VERSION ""

NS_ :

BS_:

BU_: EHR_Spare FEHR_3 PTO_SpeedSelector Dummy_Node_Ch2 FEHR_2 TrailerBrake OffBoardDiagnosticTool1_Ch2 PowerTakeOff_Ch2 Transmission1_Ch2 FEHR_1 REHR_5 REHR_4 REHR_3 REHR_2 REHR_1 InstrumentCluster_Ch2 ManagementComputer_Ch2 GWAY_OnBoardDiagnosticUnit_Ch2 GWAY_OffBoardDiagTool1_VB1_Ch2 GWAY_Engine1_Ch2 GWAY_CabDisplay1_Ch2 AuxiliaryValveControl_Ch2

BO_ 2632777610 TPCM_8A: 8 FEHR_2
 SG_ CByteTPCM M : 0|8@1+ (1,0) [0|255] ""  InstrumentCluster_Ch2
 SG_ ConnAbrtReason m255 : 8|8@1+ (1,0) [0|255] ""  InstrumentCluster_Ch2
 SG_ MaxNumPktTPCM_RTS m16 : 32|8@1+ (1,0) [0|255] ""  InstrumentCluster_Ch2
 SG_ NumPktSentTPCM_CTS m17 : 8|8@1+ (1,0) [0|255] ""  InstrumentCluster_Ch2
 SG_ NxtPktNumSentTPCM_CTS m17 : 16|8@1+ (1,0) [0|255] ""  InstrumentCluster_Ch2
 SG_ PGN_PktMsgTPCM_BAM m32 : 40|24@1+ (1,0) [0|16777200] ""  InstrumentCluster_Ch2
 SG_ PGN_PktMsgTPCM_ConnAbort m255 : 40|24@1+ (1,0) [0|16777200] ""  InstrumentCluster_Ch2
 SG_ PGN_PktMsgTPCM_CTS m17 : 40|24@1+ (1,0) [0|16777200] ""  InstrumentCluster_Ch2
 SG_ PGN_PktMsgTPCM_RTS m16 : 40|24@1+ (1,0) [0|16777200] ""  InstrumentCluster_Ch2
 SG_ PGN_PktMsgTPCM_RTS2 m19 : 40|24@1+ (1,0) [0|16777200] ""  InstrumentCluster_Ch2
 SG_ TotMsgSizeBAM m32 : 8|16@1+ (1,0) [0|64255] "counts"  InstrumentCluster_Ch2
 SG_ TotMsgSizeEoMA m19 : 8|16@1+ (1,0) [0|64255] "counts"  InstrumentCluster_Ch2
 SG_ TotMsgSizeTPCM_RTS m16 : 8|16@1+ (1,0) [0|64255] "counts"  InstrumentCluster_Ch2
 SG_ TotNumPktBAM m32 : 24|8@1+ (1,0) [0|255] ""  InstrumentCluster_Ch2
 SG_ TotNumPktEoMA m19 : 24|8@1+ (1,0) [0|255] ""  InstrumentCluster_Ch2
 SG_ TotNumPktTPCM_RTS m16 : 24|8@1+ (1,0) [0|255] ""  InstrumentCluster_Ch2

BO_ 2566834825 DM1_89: 18 FEHR_1
 SG_ AmbrWarnLmp : 2|2@1+ (1,0) [0|3] ""  InstrumentCluster_Ch2
 SG_ DTC_01 : 16|32@1+ (1,0) [0|4294970000] ""  InstrumentCluster_Ch2
 SG_ DTC_02 : 48|32@1+ (1,0) [0|4294970000] ""  InstrumentCluster_Ch2
 SG_ DTC_03 : 80|32@1+ (1,0) [0|4294970000] ""  InstrumentCluster_Ch2
 SG_ DTC_04 : 112|32@1+ (1,0) [0|4294970000] ""  InstrumentCluster_Ch2
 SG_ FlashAmbrWarnLmpAWL : 10|2@1+ (1,0) [0|3] ""  InstrumentCluster_Ch2
 SG_ FlashMIL : 14|2@1+ (1,0) [0|3] ""  InstrumentCluster_Ch2
 SG_ FlashProtLmp : 8|2@1+ (1,0) [0|3] ""  InstrumentCluster_Ch2
 SG_ FlashRedStopLmpRSL : 12|2@1+ (1,0) [0|3] ""  InstrumentCluster_Ch2
 SG_ MIL : 6|2@1+ (1,0) [0|3] ""  InstrumentCluster_Ch2
 SG_ ProtLmp : 0|2@1+ (1,0) [0|3] ""  InstrumentCluster_Ch2
 SG_ RedStopLmp : 4|2@1+ (1,0) [0|3] ""  InstrumentCluster_Ch2

BO_ 2566834826 DM1_8A: 18 FEHR_2
 SG_ AmbrWarnLmp : 2|2@1+ (1,0) [0|3] ""  InstrumentCluster_Ch2
 SG_ DTC_01 : 16|32@1+ (1,0) [0|4294970000] ""  InstrumentCluster_Ch2
 SG_ DTC_02 : 48|32@1+ (1,0) [0|4294970000] ""  InstrumentCluster_Ch2
 SG_ DTC_03 : 80|32@1+ (1,0) [0|4294970000] ""  InstrumentCluster_Ch2
 SG_ DTC_04 : 112|32@1+ (1,0) [0|4294970000] ""  InstrumentCluster_Ch2
 SG_ FlashAmbrWarnLmpAWL : 10|2@1+ (1,0) [0|3] ""  InstrumentCluster_Ch2
 SG_ FlashMIL : 14|2@1+ (1,0) [0|3] ""  InstrumentCluster_Ch2
 SG_ FlashProtLmp : 8|2@1+ (1,0) [0|3] ""  InstrumentCluster_Ch2
 SG_ FlashRedStopLmpRSL : 12|2@1+ (1,0) [0|3] ""  InstrumentCluster_Ch2
 SG_ MIL : 6|2@1+ (1,0) [0|3] ""  InstrumentCluster_Ch2
 SG_ ProtLmp : 0|2@1+ (1,0) [0|3] ""  InstrumentCluster_Ch2
 SG_ RedStopLmp : 4|2@1+ (1,0) [0|3] ""  InstrumentCluster_Ch2

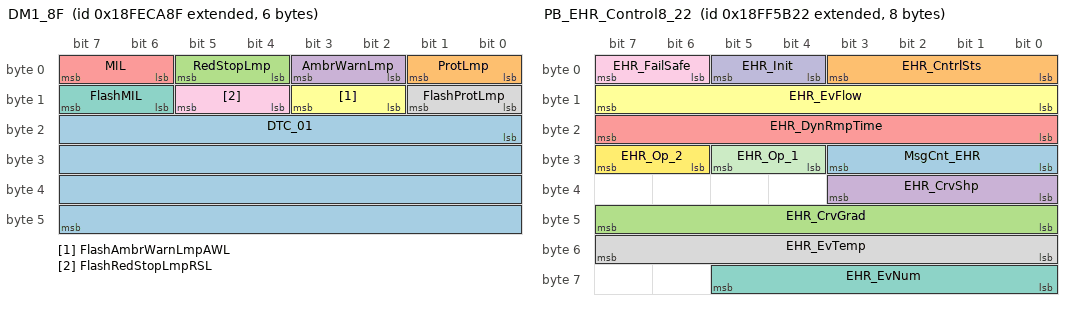
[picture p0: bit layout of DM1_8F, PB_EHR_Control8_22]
BO_ 2566834831 DM1_8F: 6 EHR_Spare
 SG_ DTC_01 : 16|32@1+ (1,0) [0|4294970000] ""  AuxiliaryValveControl_Ch2
 SG_ ProtLmp : 0|2@1+ (1,0) [0|3] ""  AuxiliaryValveControl_Ch2
 SG_ RedStopLmp : 4|2@1+ (1,0) [0|3] ""  AuxiliaryValveControl_Ch2
 SG_ AmbrWarnLmp : 2|2@1+ (1,0) [0|3] ""  AuxiliaryValveControl_Ch2
 SG_ MIL : 6|2@1+ (1,0) [0|3] ""  AuxiliaryValveControl_Ch2
 SG_ FlashAmbrWarnLmpAWL : 10|2@1+ (1,0) [0|3] ""  AuxiliaryValveControl_Ch2
 SG_ FlashMIL : 14|2@1+ (1,0) [0|3] ""  AuxiliaryValveControl_Ch2
 SG_ FlashProtLmp : 8|2@1+ (1,0) [0|3] ""  AuxiliaryValveControl_Ch2
 SG_ FlashRedStopLmpRSL : 12|2@1+ (1,0) [0|3] ""  AuxiliaryValveControl_Ch2

BO_ 2632712075 TPDT_8B: 8 FEHR_3
 SG_ PktDataTPDT : 8|56@1+ (1,0) [0|7.20575940379279E+16] ""  InstrumentCluster_Ch2
 SG_ SN_TPDT : 0|8@1+ (1,0) [0|255] ""  InstrumentCluster_Ch2

BO_ 2632777611 TPCM_8B: 8 FEHR_3
 SG_ CByteTPCM M : 0|8@1+ (1,0) [0|255] ""  InstrumentCluster_Ch2
 SG_ ConnAbrtReason m255 : 8|8@1+ (1,0) [0|255] ""  InstrumentCluster_Ch2
 SG_ MaxNumPktTPCM_RTS m16 : 32|8@1+ (1,0) [0|255] ""  InstrumentCluster_Ch2
 SG_ NumPktSentTPCM_CTS m17 : 8|8@1+ (1,0) [0|255] ""  InstrumentCluster_Ch2
 SG_ NxtPktNumSentTPCM_CTS m17 : 16|8@1+ (1,0) [0|255] ""  InstrumentCluster_Ch2
 SG_ PGN_PktMsgTPCM_BAM m32 : 40|24@1+ (1,0) [0|16777200] ""  InstrumentCluster_Ch2
 SG_ PGN_PktMsgTPCM_ConnAbort m255 : 40|24@1+ (1,0) [0|16777200] ""  InstrumentCluster_Ch2
 SG_ PGN_PktMsgTPCM_CTS m17 : 40|24@1+ (1,0) [0|16777200] ""  InstrumentCluster_Ch2
 SG_ PGN_PktMsgTPCM_RTS m16 : 40|24@1+ (1,0) [0|16777200] ""  InstrumentCluster_Ch2
 SG_ PGN_PktMsgTPCM_RTS2 m19 : 40|24@1+ (1,0) [0|16777200] ""  InstrumentCluster_Ch2
 SG_ TotMsgSizeBAM m32 : 8|16@1+ (1,0) [0|64255] "counts"  InstrumentCluster_Ch2
 SG_ TotMsgSizeEoMA m19 : 8|16@1+ (1,0) [0|64255] "counts"  InstrumentCluster_Ch2
 SG_ TotMsgSizeTPCM_RTS m16 : 8|16@1+ (1,0) [0|64255] "counts"  InstrumentCluster_Ch2
 SG_ TotNumPktBAM m32 : 24|8@1+ (1,0) [0|255] ""  InstrumentCluster_Ch2
 SG_ TotNumPktEoMA m19 : 24|8@1+ (1,0) [0|255] ""  InstrumentCluster_Ch2
 SG_ TotNumPktTPCM_RTS m16 : 24|8@1+ (1,0) [0|255] ""  InstrumentCluster_Ch2

BO_ 2566838923 SOFT_8B: 89 FEHR_3
 SG_ Appl_Id_Byte_24 : 552|8@1+ (1,0) [0|255] ""  AuxiliaryValveControl_Ch2
 SG_ Appl_Id_Byte_25 : 560|8@1+ (1,0) [0|255] ""  AuxiliaryValveControl_Ch2
 SG_ Appl_Id_Byte_26 : 568|8@1+ (1,0) [0|255] ""  AuxiliaryValveControl_Ch2
 SG_ Appl_Id_Byte_27 : 576|8@1+ (1,0) [0|255] ""  AuxiliaryValveControl_Ch2
 SG_ Appl_Id_Byte_28 : 584|8@1+ (1,0) [0|255] ""  AuxiliaryValveControl_Ch2
 SG_ Appl_Id_Byte_29 : 592|8@1+ (1,0) [0|255] ""  AuxiliaryValveControl_Ch2
 SG_ Appl_Id_Byte_30 : 600|8@1+ (1,0) [0|255] ""  AuxiliaryValveControl_Ch2
 SG_ Appl_Id_Byte_31 : 608|8@1+ (1,0) [0|255] ""  AuxiliaryValveControl_Ch2
 SG_ Appl_Id_Byte_32 : 616|8@1+ (1,0) [0|255] ""  AuxiliaryValveControl_Ch2
 SG_ Appl_Id_Byte_33 : 624|8@1+ (1,0) [0|255] ""  AuxiliaryValveControl_Ch2
 SG_ Appl_Id_Byte_34 : 632|8@1+ (1,0) [0|255] ""  AuxiliaryValveControl_Ch2
 SG_ Appl_Id_Byte_35 : 640|8@1+ (1,0) [0|255] ""  AuxiliaryValveControl_Ch2
 SG_ Appl_Id_Byte_36 : 648|8@1+ (1,0) [0|255] ""  AuxiliaryValveControl_Ch2
 SG_ Appl_Id_Byte_37 : 656|8@1+ (1,0) [0|255] ""  AuxiliaryValveControl_Ch2
 SG_ Appl_Id_Byte_38 : 664|8@1+ (1,0) [0|255] ""  AuxiliaryValveControl_Ch2
 SG_ Appl_Id_Byte_39 : 672|8@1+ (1,0) [0|255] ""  AuxiliaryValveControl_Ch2
 SG_ Appl_Id_Enum : 680|24@1+ (1,0) [0|16777215] ""  AuxiliaryValveControl_Ch2
 SG_ Bootloader_Id : 360|8@1+ (1,0) [0|255] ""  AuxiliaryValveControl_Ch2
 SG_ Bootloader_Id_Byte_01 : 16|8@1+ (1,0) [0|255] ""  AuxiliaryValveControl_Ch2
 SG_ Bootloader_Id_Byte_02 : 24|8@1+ (1,0) [0|255] ""  AuxiliaryValveControl_Ch2
 SG_ Bootloader_Id_Byte_03 : 32|8@1+ (1,0) [0|255] ""  AuxiliaryValveControl_Ch2
 SG_ Bootloader_Id_Byte_04 : 40|8@1+ (1,0) [0|255] ""  AuxiliaryValveControl_Ch2
 SG_ Bootloader_Id_Byte_05 : 48|8@1+ (1,0) [0|255] ""  AuxiliaryValveControl_Ch2
 SG_ Bootloader_Id_Byte_06 : 56|8@1+ (1,0) [0|255] ""  AuxiliaryValveControl_Ch2
 SG_ Bootloader_Id_Byte_07 : 64|8@1+ (1,0) [0|255] ""  AuxiliaryValveControl_Ch2
 SG_ Bootloader_Id_Byte_08 : 72|8@1+ (1,0) [0|255] ""  AuxiliaryValveControl_Ch2
 SG_ Bootloader_Id_Byte_09 : 80|8@1+ (1,0) [0|255] ""  AuxiliaryValveControl_Ch2
 SG_ Bootloader_Id_Byte_10 : 88|8@1+ (1,0) [0|255] ""  AuxiliaryValveControl_Ch2
 SG_ Bootloader_Id_Byte_11 : 96|8@1+ (1,0) [0|255] ""  AuxiliaryValveControl_Ch2
 SG_ Bootloader_Id_Byte_12 : 104|8@1+ (1,0) [0|255] ""  AuxiliaryValveControl_Ch2
 SG_ Bootloader_Id_Byte_13 : 112|8@1+ (1,0) [0|255] ""  AuxiliaryValveControl_Ch2
 SG_ Bootloader_Id_Byte_14 : 120|8@1+ (1,0) [0|255] ""  AuxiliaryValveControl_Ch2
 SG_ Bootloader_Id_Byte_15 : 128|8@1+ (1,0) [0|255] ""  AuxiliaryValveControl_Ch2
 SG_ Bootloader_Id_Byte_16 : 136|8@1+ (1,0) [0|255] ""  AuxiliaryValveControl_Ch2
 SG_ Bootloader_Id_Byte_17 : 144|8@1+ (1,0) [0|255] ""  AuxiliaryValveControl_Ch2
 SG_ Bootloader_Id_Byte_18 : 152|8@1+ (1,0) [0|255] ""  AuxiliaryValveControl_Ch2
 SG_ Bootloader_Id_Byte_19 : 160|8@1+ (1,0) [0|255] ""  AuxiliaryValveControl_Ch2
 SG_ Bootloader_Id_Byte_20 : 168|8@1+ (1,0) [0|255] ""  AuxiliaryValveControl_Ch2
 SG_ Bootloader_Id_Byte_21 : 176|8@1+ (1,0) [0|255] ""  AuxiliaryValveControl_Ch2
 SG_ Bootloader_Id_Byte_22 : 184|8@1+ (1,0) [0|255] ""  AuxiliaryValveControl_Ch2
 SG_ Bootloader_Id_Byte_23 : 192|8@1+ (1,0) [0|255] ""  AuxiliaryValveControl_Ch2
 SG_ Bootloader_Id_Byte_24 : 200|8@1+ (1,0) [0|255] ""  AuxiliaryValveControl_Ch2
 SG_ Bootloader_Id_Byte_25 : 208|8@1+ (1,0) [0|255] ""  AuxiliaryValveControl_Ch2
 SG_ Bootloader_Id_Byte_26 : 216|8@1+ (1,0) [0|255] ""  AuxiliaryValveControl_Ch2
 SG_ Bootloader_Id_Byte_27 : 224|8@1+ (1,0) [0|255] ""  AuxiliaryValveControl_Ch2
 SG_ Bootloader_Id_Byte_28 : 232|8@1+ (1,0) [0|255] ""  AuxiliaryValveControl_Ch2
 SG_ Bootloader_Id_Byte_29 : 240|8@1+ (1,0) [0|255] ""  AuxiliaryValveControl_Ch2
 SG_ Bootloader_Id_Byte_30 : 248|8@1+ (1,0) [0|255] ""  AuxiliaryValveControl_Ch2
 SG_ Bootloader_Id_Byte_31 : 256|8@1+ (1,0) [0|255] ""  AuxiliaryValveControl_Ch2
 SG_ Bootloader_Id_Byte_32 : 264|8@1+ (1,0) [0|255] ""  AuxiliaryValveControl_Ch2
 SG_ Bootloader_Id_Byte_33 : 272|8@1+ (1,0) [0|255] ""  AuxiliaryValveControl_Ch2
 SG_ Bootloader_Id_Byte_34 : 280|8@1+ (1,0) [0|255] ""  AuxiliaryValveControl_Ch2
 SG_ Bootloader_Id_Byte_35 : 288|8@1+ (1,0) [0|255] ""  AuxiliaryValveControl_Ch2
 SG_ Bootloader_Id_Byte_36 : 296|8@1+ (1,0) [0|255] ""  AuxiliaryValveControl_Ch2
 SG_ Bootloader_Id_Byte_37 : 304|8@1+ (1,0) [0|255] ""  AuxiliaryValveControl_Ch2
 SG_ Bootloader_Id_Byte_38 : 312|8@1+ (1,0) [0|255] ""  AuxiliaryValveControl_Ch2
 SG_ Bootloader_Id_Byte_39 : 320|8@1+ (1,0) [0|255] ""  AuxiliaryValveControl_Ch2
 SG_ Bootloader_Id_Enum : 328|24@1+ (1,0) [0|16777215] ""  AuxiliaryValveControl_Ch2
 SG_ EndStrng_00 : 352|8@1+ (1,0) [0|255] "per byte"  AuxiliaryValveControl_Ch2
 SG_ EndStrng_01 : 704|8@1+ (1,0) [0|255] "per byte"  AuxiliaryValveControl_Ch2
 SG_ NumSW_IdField : 0|8@1+ (1,0) [0|250] "step"  AuxiliaryValveControl_Ch2
 SG_ Appl_Id : 8|8@1+ (1,0) [0|255] ""  AuxiliaryValveControl_Ch2
 SG_ Appl_Id_Byte_01 : 368|8@1+ (1,0) [0|255] ""  AuxiliaryValveControl_Ch2
 SG_ Appl_Id_Byte_02 : 376|8@1+ (1,0) [0|255] ""  AuxiliaryValveControl_Ch2
 SG_ Appl_Id_Byte_03 : 384|8@1+ (1,0) [0|255] ""  AuxiliaryValveControl_Ch2
 SG_ Appl_Id_Byte_04 : 392|8@1+ (1,0) [0|255] ""  AuxiliaryValveControl_Ch2
 SG_ Appl_Id_Byte_05 : 400|8@1+ (1,0) [0|255] ""  AuxiliaryValveControl_Ch2
 SG_ Appl_Id_Byte_06 : 408|8@1+ (1,0) [0|255] ""  AuxiliaryValveControl_Ch2
 SG_ Appl_Id_Byte_07 : 416|8@1+ (1,0) [0|255] ""  AuxiliaryValveControl_Ch2
 SG_ Appl_Id_Byte_08 : 424|8@1+ (1,0) [0|255] ""  AuxiliaryValveControl_Ch2
 SG_ Appl_Id_Byte_09 : 432|8@1+ (1,0) [0|255] ""  AuxiliaryValveControl_Ch2
 SG_ Appl_Id_Byte_10 : 440|8@1+ (1,0) [0|255] ""  AuxiliaryValveControl_Ch2
 SG_ Appl_Id_Byte_11 : 448|8@1+ (1,0) [0|255] ""  AuxiliaryValveControl_Ch2
 SG_ Appl_Id_Byte_12 : 456|8@1+ (1,0) [0|255] ""  AuxiliaryValveControl_Ch2
 SG_ Appl_Id_Byte_13 : 464|8@1+ (1,0) [0|255] ""  AuxiliaryValveControl_Ch2
 SG_ Appl_Id_Byte_14 : 472|8@1+ (1,0) [0|255] ""  AuxiliaryValveControl_Ch2
 SG_ Appl_Id_Byte_15 : 480|8@1+ (1,0) [0|255] ""  AuxiliaryValveControl_Ch2
 SG_ Appl_Id_Byte_16 : 488|8@1+ (1,0) [0|255] ""  AuxiliaryValveControl_Ch2
 SG_ Appl_Id_Byte_17 : 496|8@1+ (1,0) [0|255] ""  AuxiliaryValveControl_Ch2
 SG_ Appl_Id_Byte_18 : 504|8@1+ (1,0) [0|255] ""  AuxiliaryValveControl_Ch2
 SG_ Appl_Id_Byte_19 : 512|8@1+ (1,0) [0|255] ""  AuxiliaryValveControl_Ch2
 SG_ Appl_Id_Byte_20 : 520|8@1+ (1,0) [0|255] ""  AuxiliaryValveControl_Ch2
 SG_ Appl_Id_Byte_21 : 528|8@1+ (1,0) [0|255] ""  AuxiliaryValveControl_Ch2
 SG_ Appl_Id_Byte_22 : 536|8@1+ (1,0) [0|255] ""  AuxiliaryValveControl_Ch2
 SG_ Appl_Id_Byte_23 : 544|8@1+ (1,0) [0|255] ""  AuxiliaryValveControl_Ch2

BO_ 2566871842 PB_EHR_Control8_22: 8 AuxiliaryValveControl_Ch2
 SG_ MsgCnt_EHR : 24|4@1+ (1,0) [0|12] "count" Vector__XXX
 SG_ EHR_CntrlSts : 0|4@1+ (1,0) [0|15] ""  FEHR_3
 SG_ EHR_CrvGrad : 40|8@1+ (0.3922,0) [0|100] "%"  FEHR_3
 SG_ EHR_CrvShp : 32|4@1+ (1,0) [0|15] ""  FEHR_3
 SG_ EHR_DynRmpTime : 16|8@1+ (32,0) [0|8128] "ms"  FEHR_3
 SG_ EHR_EvFlow : 8|8@1+ (0.3937,0) [0|100] "%"  FEHR_3
 SG_ EHR_EvNum : 56|6@1+ (1,0) [0|63] ""  FEHR_3
 SG_ EHR_EvTemp : 48|8@1+ (1,-80) [-40|120] "Deg C"  FEHR_3
 SG_ EHR_FailSafe : 6|2@1+ (1,0) [0|3] ""  FEHR_3
 SG_ EHR_Init : 4|2@1+ (1,0) [0|3] ""  FEHR_3
 SG_ EHR_Op_1 : 28|2@1+ (1,0) [0|3] ""  FEHR_3
 SG_ EHR_Op_2 : 30|2@1+ (1,0) [0|3] ""  FEHR_3

BO_ 2564487563 ISO15765_Phys_8B_F9: 8 FEHR_3
 SG_ ProtocCntrlInfo M : 4|4@1+ (1,0) [0|3] "" Vector__XXX
 SG_ SingFrameDataLen m0 : 0|4@1+ (1,0) [0|7] "Byte" Vector__XXX
 SG_ N1FrameDataLen m1 : 3|12@0+ (1,0) [0|4095] "Byte" Vector__XXX
 SG_ FlowSts m3 : 0|4@1+ (1,0) [0|3] "" Vector__XXX
 SG_ BlkSize m3 : 8|8@1+ (1,0) [0|255] "" Vector__XXX
 SG_ SepTime m3 : 16|8@1+ (1,0) [0|255] "ms" Vector__XXX
 SG_ SN m2 : 0|4@1+ (1,0) [0|15] "" Vector__XXX

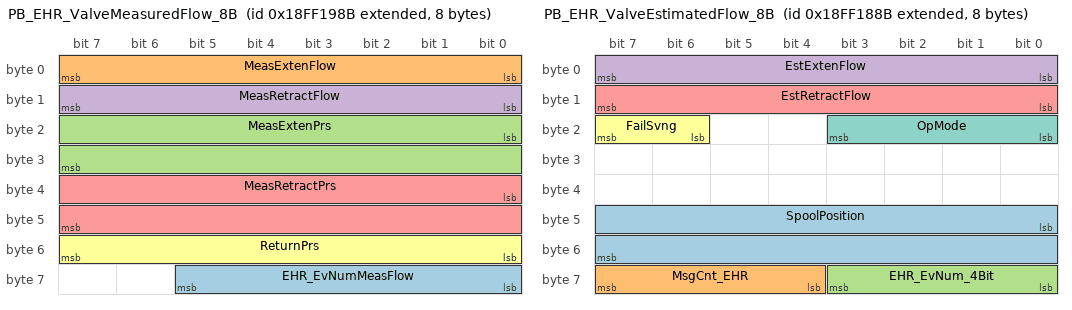
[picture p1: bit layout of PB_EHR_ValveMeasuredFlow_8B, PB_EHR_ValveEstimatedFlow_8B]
BO_ 2566855051 PB_EHR_ValveMeasuredFlow_8B: 8 FEHR_3
 SG_ EHR_EvNumMeasFlow : 56|6@1+ (1,0) [0|63] "" Vector__XXX
 SG_ MeasExtenFlow : 0|8@1+ (1,-125) [-125|125] "%" Vector__XXX
 SG_ MeasExtenPrs : 16|16@1+ (5,0) [0|321275] "kPa" Vector__XXX
 SG_ MeasRetractFlow : 8|8@1+ (1,-125) [-125|125] "%" Vector__XXX
 SG_ MeasRetractPrs : 32|16@1+ (5,0) [0|321275] "kPa" Vector__XXX
 SG_ ReturnPrs : 48|8@1+ (16,0) [0|4000] "kPa" Vector__XXX

BO_ 2566854795 PB_EHR_ValveEstimatedFlow_8B: 8 FEHR_3
 SG_ SpoolPosition : 40|16@1+ (1,0) [0|1023] ""  AuxiliaryValveControl_Ch2
 SG_ MsgCnt_EHR : 60|4@1+ (1,0) [0|12] "count"  AuxiliaryValveControl_Ch2
 SG_ EHR_EvNum_4Bit : 56|4@1+ (1,0) [0|15] ""  AuxiliaryValveControl_Ch2
 SG_ EstExtenFlow : 0|8@1+ (0.8,-102.4) [0|100] "%"  AuxiliaryValveControl_Ch2
 SG_ EstRetractFlow : 8|8@1+ (0.8,-102.4) [0|100] "%"  AuxiliaryValveControl_Ch2
 SG_ FailSvng : 22|2@1+ (1,0) [0|3] ""  AuxiliaryValveControl_Ch2
 SG_ OpMode : 16|4@1+ (1,0) [0|15] ""  AuxiliaryValveControl_Ch2

BO_ 2566866059 PB_EHR_ParameterStatus_8B: 8 FEHR_3
 SG_ EHR_RmpRndng m103 : 32|8@1+ (1,0) [0|255] ""  AuxiliaryValveControl_Ch2
 SG_ EHR_ChksumStor m80 : 40|8@1+ (1,0) [0|255] ""  AuxiliaryValveControl_Ch2
 SG_ EHR_ChksumSW m80 : 32|8@1+ (1,0) [0|255] ""  AuxiliaryValveControl_Ch2
 SG_ EHR_EvNumParamMux_12 : 24|8@1+ (1,0) [0|255] ""  AuxiliaryValveControl_Ch2
 SG_ EHR_ParamStsByte_3 M : 16|8@1+ (1,0) [0|255] ""  AuxiliaryValveControl_Ch2
 SG_ EHR_ParamStsByte_2 : 8|8@1+ (1,0) [0|255] ""  AuxiliaryValveControl_Ch2
 SG_ EHR_ParamByte_1 : 0|8@1+ (1,0) [0|255] ""  AuxiliaryValveControl_Ch2

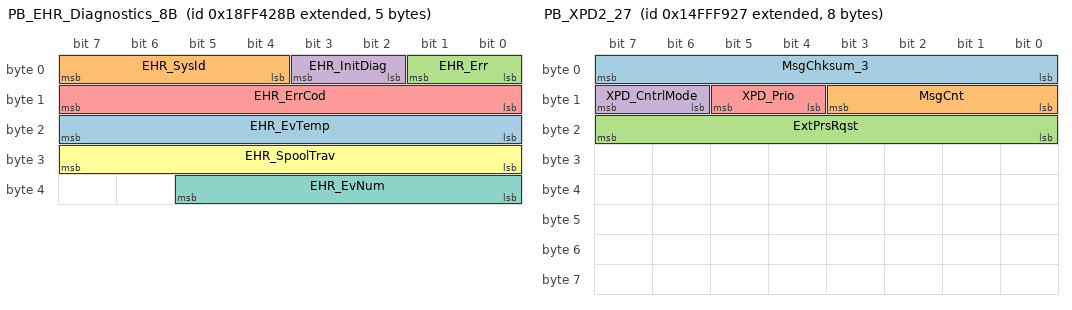
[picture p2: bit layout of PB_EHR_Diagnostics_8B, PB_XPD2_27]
BO_ 2566865547 PB_EHR_Diagnostics_8B: 5 FEHR_3
 SG_ EHR_EvTemp : 16|8@1+ (1,-80) [-40|120] "Deg C"  AuxiliaryValveControl_Ch2
 SG_ EHR_SysId : 4|4@1+ (1,0) [0|15] ""  AuxiliaryValveControl_Ch2
 SG_ EHR_Err : 0|2@1+ (1,0) [0|3] ""  AuxiliaryValveControl_Ch2
 SG_ EHR_InitDiag : 2|2@1+ (1,0) [0|3] ""  AuxiliaryValveControl_Ch2
 SG_ EHR_ErrCod : 8|8@1+ (1,0) [0|254] ""  AuxiliaryValveControl_Ch2
 SG_ EHR_SpoolTrav : 24|8@1+ (1,0) [0|254] ""  AuxiliaryValveControl_Ch2
 SG_ EHR_EvNum : 32|6@1+ (1,0) [0|63] ""  AuxiliaryValveControl_Ch2

BO_ 2566835083 DM2_8B: 74 FEHR_3
 SG_ DTC_01 : 16|32@1+ (1,0) [0|4294970000] "" Vector__XXX
 SG_ FlashAmbrWarnLmpAWL : 10|2@1+ (1,0) [0|3] "" Vector__XXX
 SG_ FlashMIL : 14|2@1+ (1,0) [0|3] "" Vector__XXX
 SG_ FlashProtLmp : 8|2@1+ (1,0) [0|3] "" Vector__XXX
 SG_ FlashRedStopLmpRSL : 12|2@1+ (1,0) [0|3] "" Vector__XXX
 SG_ ProtLmp : 0|2@1+ (1,0) [0|3] "" Vector__XXX
 SG_ AmbrWarnLmp : 2|2@1+ (1,0) [0|3] "" Vector__XXX
 SG_ RedStopLmp : 4|2@1+ (1,0) [0|3] "" Vector__XXX
 SG_ MIL : 6|2@1+ (1,0) [0|3] "" Vector__XXX

BO_ 2566834827 DM1_8B: 42 FEHR_3
 SG_ DTC_10 : 304|32@1+ (1,0) [0|4294970000] "" Vector__XXX
 SG_ DTC_09 : 272|32@1+ (1,0) [0|4294970000] "" Vector__XXX
 SG_ DTC_08 : 240|32@1+ (1,0) [0|4294970000] "" Vector__XXX
 SG_ DTC_07 : 208|32@1+ (1,0) [0|4294970000] "" Vector__XXX
 SG_ DTC_06 : 176|32@1+ (1,0) [0|4294970000] "" Vector__XXX
 SG_ DTC_05 : 144|32@1+ (1,0) [0|4294970000] "" Vector__XXX
 SG_ DTC_04 : 112|32@1+ (1,0) [0|4294970000] "" Vector__XXX
 SG_ DTC_03 : 80|32@1+ (1,0) [0|4294970000] "" Vector__XXX
 SG_ DTC_02 : 48|32@1+ (1,0) [0|4294970000] "" Vector__XXX
 SG_ DTC_01 : 16|32@1+ (1,0) [0|4294970000] "" Vector__XXX
 SG_ ProtLmp : 0|2@1+ (1,0) [0|3] "" Vector__XXX
 SG_ RedStopLmp : 4|2@1+ (1,0) [0|3] "" Vector__XXX
 SG_ AmbrWarnLmp : 2|2@1+ (1,0) [0|3] "" Vector__XXX
 SG_ MIL : 6|2@1+ (1,0) [0|3] "" Vector__XXX
 SG_ FlashAmbrWarnLmpAWL : 10|2@1+ (1,0) [0|3] "" Vector__XXX
 SG_ FlashMIL : 14|2@1+ (1,0) [0|3] "" Vector__XXX
 SG_ FlashProtLmp : 8|2@1+ (1,0) [0|3] "" Vector__XXX
 SG_ FlashRedStopLmpRSL : 12|2@1+ (1,0) [0|3] "" Vector__XXX

BO_ 2499803431 PB_XPD2_27: 8 ManagementComputer_Ch2
 SG_ MsgChksum_3 : 0|8@1+ (1,0) [0|255] "count"  TrailerBrake
 SG_ MsgCnt : 8|4@1+ (1,0) [0|15] "count"  TrailerBrake
 SG_ ExtPrsRqst : 16|8@1+ (5,0) [0|1250] "kPa"  TrailerBrake
 SG_ XPD_CntrlMode : 14|2@1+ (1,0) [0|3] ""  TrailerBrake
 SG_ XPD_Prio : 12|2@1+ (1,0) [0|3] ""  TrailerBrake

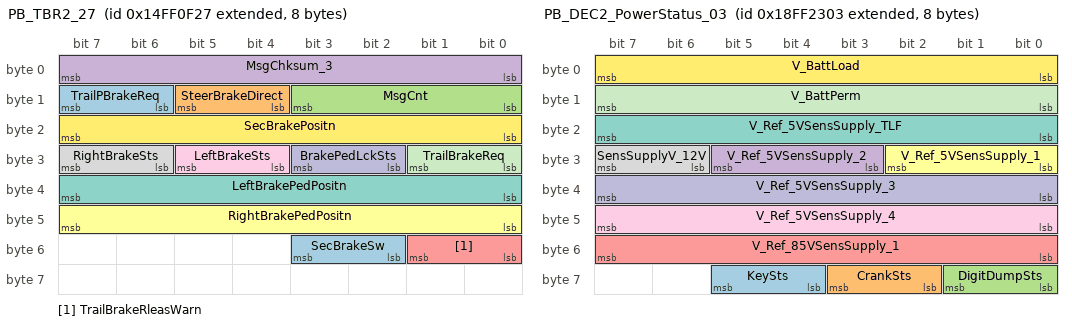
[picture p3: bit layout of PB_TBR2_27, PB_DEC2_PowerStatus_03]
BO_ 2499743527 PB_TBR2_27: 8 ManagementComputer_Ch2
 SG_ TrailPBrakeReq : 14|2@1+ (1,0) [0|3] ""  TrailerBrake
 SG_ SteerBrakeDirect : 12|2@1+ (1,0) [0|3] ""  TrailerBrake
 SG_ MsgCnt : 8|4@1+ (1,0) [0|15] "count"  TrailerBrake
 SG_ MsgChksum_3 : 0|8@1+ (1,0) [0|255] "count"  TrailerBrake
 SG_ TrailBrakeRleasWarn : 48|2@1+ (1,0) [0|3] ""  TrailerBrake
 SG_ RightBrakePedPositn : 40|8@1+ (0.4,0) [0|100] "%"  TrailerBrake
 SG_ LeftBrakePedPositn : 32|8@1+ (0.4,0) [0|100] "%"  TrailerBrake
 SG_ RightBrakeSts : 30|2@1+ (1,0) [0|3] ""  TrailerBrake
 SG_ LeftBrakeSts : 28|2@1+ (1,0) [0|3] ""  TrailerBrake
 SG_ BrakePedLckSts : 26|2@1+ (1,0) [0|3] ""  TrailerBrake
 SG_ TrailBrakeReq : 24|2@1+ (1,0) [0|3] ""  TrailerBrake
 SG_ SecBrakePositn : 16|8@1+ (0.4,0) [0|100] "%"  TrailerBrake
 SG_ SecBrakeSw : 50|2@1+ (1,0) [0|3] ""  TrailerBrake

BO_ 2566857475 PB_DEC2_PowerStatus_03: 8 Transmission1_Ch2
 SG_ KeySts : 60|2@1+ (1,0) [0|3] ""  Dummy_Node_Ch2
 SG_ CrankSts : 58|2@1+ (1,0) [0|3] ""  Dummy_Node_Ch2
 SG_ DigitDumpSts : 56|2@1+ (1,0) [0|3] ""  Dummy_Node_Ch2
 SG_ V_Ref_5VSensSupply_2 : 27|3@1+ (1,0) [0|7] ""  Dummy_Node_Ch2
 SG_ V_Ref_85VSensSupply_1 : 48|8@1+ (0.0625,0) [0|15.8125] "V"  Dummy_Node_Ch2
 SG_ V_Ref_5VSensSupply_1 : 24|3@1+ (1,0) [0|7] ""  Dummy_Node_Ch2
 SG_ V_Ref_5VSensSupply_TLF : 16|8@1+ (0.03125,0) [0|7.90625] "V"  Dummy_Node_Ch2
 SG_ SensSupplyV_12V : 30|2@1+ (1,0) [0|3] ""  Dummy_Node_Ch2
 SG_ V_Ref_5VSensSupply_4 : 40|8@1+ (0.03125,0) [0|7.90625] "V"  Dummy_Node_Ch2
 SG_ V_Ref_5VSensSupply_3 : 32|8@1+ (0.03125,0) [0|7.90625] "V"  Dummy_Node_Ch2
 SG_ V_BattPerm : 8|8@1+ (0.125,0) [0|31.875] "V"  Dummy_Node_Ch2
 SG_ V_BattLoad : 0|8@1+ (0.125,0) [0|31.875] "V"  Dummy_Node_Ch2

BO_ 2564488958 ISO15765_Phys: 8 REHR_1
 SG_ ProtocCntrlInfo M : 4|4@1+ (1,0) [0|3] ""  AuxiliaryValveControl_Ch2
 SG_ SN m2 : 0|4@1+ (1,0) [0|15] ""  AuxiliaryValveControl_Ch2
 SG_ SepTime m3 : 16|8@1+ (1,0) [0|255] "ms"  AuxiliaryValveControl_Ch2
 SG_ SingFrameDataLen m0 : 0|4@1+ (1,0) [0|7] "Byte"  AuxiliaryValveControl_Ch2
 SG_ N1FrameDataLen m1 : 3|12@0+ (1,0) [0|4095] "Byte"  AuxiliaryValveControl_Ch2
 SG_ FlowSts m3 : 0|4@1+ (1,0) [0|3] ""  AuxiliaryValveControl_Ch2
 SG_ BlkSize m3 : 8|8@1+ (1,0) [0|255] ""  AuxiliaryValveControl_Ch2

BO_ 2565603086 TPDT_0E: 8 TrailerBrake
 SG_ PktDataTPDT : 8|56@1+ (1,0) [0|7.20575940379279E+16] ""  ManagementComputer_Ch2
 SG_ SN_TPDT : 0|8@1+ (1,0) [0|255] ""  ManagementComputer_Ch2

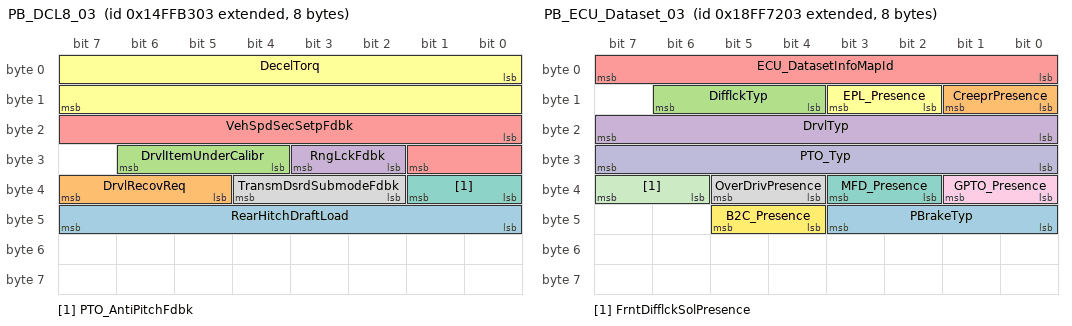
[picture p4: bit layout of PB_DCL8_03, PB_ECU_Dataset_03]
BO_ 2499785475 PB_DCL8_03: 8 Transmission1_Ch2
 SG_ RearHitchDraftLoad : 40|8@1+ (1,0) [0|100] "%"  ManagementComputer_Ch2
 SG_ DrvlRecovReq : 37|3@1+ (1,0) [0|7] ""  ManagementComputer_Ch2
 SG_ DrvlItemUnderCalibr : 28|3@1+ (1,0) [0|7] ""  ManagementComputer_Ch2
 SG_ RngLckFdbk : 26|2@1+ (1,0) [0|3] ""  ManagementComputer_Ch2
 SG_ VehSpdSecSetpFdbk : 16|10@1+ (0.1,0) [0|102] "%"  ManagementComputer_Ch2
 SG_ DecelTorq : 0|16@1+ (1,0) [0|64255] "Nm"  ManagementComputer_Ch2
 SG_ PTO_AntiPitchFdbk : 32|2@1+ (1,0) [0|3] ""  ManagementComputer_Ch2
 SG_ TransmDsrdSubmodeFdbk : 34|3@1+ (1,0) [0|7] ""  ManagementComputer_Ch2

BO_ 2566877699 PB_ECU_Dataset_03: 8 Transmission1_Ch2
 SG_ PBrakeTyp : 40|4@1+ (1,0) [0|15] ""  ManagementComputer_Ch2
 SG_ CreeprPresence : 8|2@1+ (1,0) [0|3] ""  ManagementComputer_Ch2
 SG_ DifflckTyp : 12|3@1+ (1,0) [0|7] ""  ManagementComputer_Ch2
 SG_ DrvlTyp : 16|8@1+ (1,0) [0|255] ""  ManagementComputer_Ch2
 SG_ ECU_DatasetInfoMapId : 0|8@1+ (1,0) [0|250] ""  ManagementComputer_Ch2
 SG_ EPL_Presence : 10|2@1+ (1,0) [0|3] ""  ManagementComputer_Ch2
 SG_ MFD_Presence : 34|2@1+ (1,0) [0|3] ""  ManagementComputer_Ch2
 SG_ OverDrivPresence : 36|2@1+ (1,0) [0|3] ""  ManagementComputer_Ch2
 SG_ GPTO_Presence : 32|2@1+ (1,0) [0|3] ""  ManagementComputer_Ch2
 SG_ PTO_Typ : 24|8@1+ (1,0) [0|255] ""  ManagementComputer_Ch2
 SG_ FrntDifflckSolPresence : 38|2@1+ (1,0) [0|3] "states/2 bit" Vector__XXX
 SG_ B2C_Presence : 44|2@1+ (1,0) [0|3] "" Vector__XXX

BO_ 2565351182 ACKM_0E_27: 8 TrailerBrake
 SG_ AddrAccssDeny m2 : 32|8@1+ (1,0) [0|255] "" Vector__XXX
 SG_ AddrAck m0 : 32|8@1+ (1,0) [0|255] "" Vector__XXX
 SG_ AddrBusy m3 : 32|8@1+ (1,0) [0|255] "" Vector__XXX
 SG_ AddrNegAck m1 : 32|8@1+ (1,0) [0|255] "" Vector__XXX
 SG_ CByteAckm M : 0|8@1+ (1,0) [0|255] "" Vector__XXX
 SG_ GrpFunctValAck : 8|8@1+ (1,0) [0|255] "" Vector__XXX
 SG_ PGN_RQST2_0E_27 : 40|24@1+ (1,0) [0|16777200] ""  ManagementComputer_Ch2

BO_ 2565351171 ACKM_03_27: 8 Transmission1_Ch2
 SG_ AddrNegAck m1 : 32|8@1+ (1,0) [0|255] "" Vector__XXX
 SG_ AddrBusy m3 : 32|8@1+ (1,0) [0|255] "" Vector__XXX
 SG_ AddrAck m0 : 32|8@1+ (1,0) [0|255] "" Vector__XXX
 SG_ AddrAccssDeny m2 : 32|8@1+ (1,0) [0|255] "" Vector__XXX
 SG_ GrpFunctValAck : 8|8@1+ (1,0) [0|255] "" Vector__XXX
 SG_ PGN_RQST2_03_27 : 40|24@1+ (1,0) [0|16777200] ""  ManagementComputer_Ch2
 SG_ CByteAckm M : 0|8@1+ (1,0) [0|255] "" Vector__XXX

BO_ 2566888195 PB_DCL5_03: 8 Transmission1_Ch2
 SG_ GearMapAv : 0|64@1+ (1,0) [0|64] "bit bit-mapped"  ManagementComputer_Ch2

BO_ 2566871043 PB_AxleId_03: 8 Transmission1_Ch2
 SG_ AxId : 0|8@1+ (1,0) [0|255] ""  ManagementComputer_Ch2

BO_ 2499798019 PB_Heartbeat_03_27: 8 Transmission1_Ch2
 SG_ Hrtbt : 0|8@1+ (1,0) [0|251] "count"  ManagementComputer_Ch2
 SG_ MsgChksum_4 : 12|4@1+ (1,0) [0|15] "count"  ManagementComputer_Ch2
 SG_ SpecialModeResp : 47|1@1+ (1,0) [0|1] "" Vector__XXX
 SG_ SpecialModeReq : 44|3@1+ (1,0) [0|7] "" Vector__XXX
 SG_ ThisNetReq : 22|2@1+ (1,0) [0|3] "" Vector__XXX
 SG_ BattMainSwHoldReq : 20|2@1+ (1,0) [0|3] "" Vector__XXX
 SG_ KeyPositn : 48|8@1+ (1,0) [0|255] "" Vector__XXX
 SG_ BattMainSwHoldFunct : 40|4@1+ (1,0) [0|15] "" Vector__XXX
 SG_ OpSeatSw : 8|2@1+ (1,0) [0|3] "" Vector__XXX
 SG_ AutoGuideEnaSts : 16|2@1+ (1,0) [0|3] "" Vector__XXX
 SG_ WakeUpInDozeMode : 24|2@1+ (1,0) [0|3] "" Vector__XXX
 SG_ WakeUpFunct : 28|4@1+ (1,0) [0|15] "" Vector__XXX
 SG_ VehMov : 36|2@1+ (1,0) [0|3] "" Vector__XXX
 SG_ KeySwNotOFF : 10|2@1+ (1,0) [0|3] "" Vector__XXX
 SG_ IgnON : 26|2@1+ (1,0) [0|3] "" Vector__XXX
 SG_ EngStartSts : 32|2@1+ (1,0) [0|3] "" Vector__XXX
 SG_ CByteNetManage : 18|2@1+ (1,0) [0|3] "" Vector__XXX
 SG_ EngRun : 34|2@1+ (1,0) [0|3] "" Vector__XXX
 SG_ EmergEngOff_ReqSts : 39|1@1+ (1,0) [0|1] "states/1 bit" Vector__XXX
 SG_ MasterDisconnSwSts : 38|1@1+ (1,0) [0|1] "states/1 bit" Vector__XXX

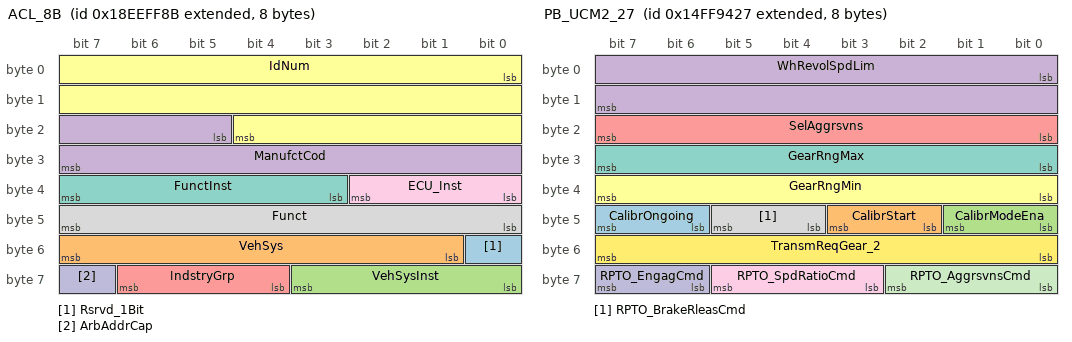
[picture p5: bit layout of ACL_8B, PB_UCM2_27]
BO_ 2565799819 ACL_8B: 8 FEHR_3
 SG_ Rsrvd_1Bit : 48|1@1+ (1,0) [0|1] "" Vector__XXX
 SG_ VehSys : 49|7@1+ (1,0) [0|127] "" Vector__XXX
 SG_ VehSysInst : 56|4@1+ (1,0) [0|15] "" Vector__XXX
 SG_ ManufctCod : 21|11@1+ (1,0) [0|2047] "" Vector__XXX
 SG_ IndstryGrp M : 60|3@1+ (1,0) [0|7] "" Vector__XXX
 SG_ IdNum : 0|21@1+ (1,0) [0|2097151] "" Vector__XXX
 SG_ FunctInst : 35|5@1+ (1,0) [0|31] "" Vector__XXX
 SG_ Funct : 40|8@1+ (1,0) [0|255] "" Vector__XXX
 SG_ ECU_Inst : 32|3@1+ (1,0) [0|7] "" Vector__XXX
 SG_ ArbAddrCap : 63|1@1+ (1,0) [0|1] "" Vector__XXX

BO_ 2565406603 ACKM_8B: 8 FEHR_3
 SG_ AddrAccssDeny m2 : 32|8@1+ (1,0) [0|255] "" Vector__XXX
 SG_ AddrAck m0 : 32|8@1+ (1,0) [0|255] "" Vector__XXX
 SG_ AddrBusy m3 : 32|8@1+ (1,0) [0|255] "" Vector__XXX
 SG_ AddrNegAck m1 : 32|8@1+ (1,0) [0|255] "" Vector__XXX
 SG_ CByteAckm M : 0|8@1+ (1,0) [0|255] "" Vector__XXX
 SG_ GrpFunctValAck : 8|8@1+ (1,0) [0|255] "" Vector__XXX
 SG_ PGN_RQST2_EHR : 40|24@1+ (1,0) [0|16777200] "" Vector__XXX

BO_ 2499777575 PB_UCM2_27: 8 ManagementComputer_Ch2
 SG_ CalibrOngoing : 46|2@1+ (1,0) [0|3] ""  InstrumentCluster_Ch2
 SG_ CalibrStart : 42|2@1+ (1,0) [0|3] ""  InstrumentCluster_Ch2,Transmission1_Ch2
 SG_ CalibrModeEna : 40|2@1+ (1,0) [0|3] ""  InstrumentCluster_Ch2,Transmission1_Ch2
 SG_ WhRevolSpdLim : 0|16@1+ (0.125,0) [0|8031.875] "rpm"  InstrumentCluster_Ch2,Transmission1_Ch2
 SG_ SelAggrsvns : 16|8@1+ (0.4,0) [0|100] "%"  InstrumentCluster_Ch2,Transmission1_Ch2
 SG_ GearRngMin : 32|8@1+ (1,-125) [-125|125] "gear value"  InstrumentCluster_Ch2,Transmission1_Ch2
 SG_ GearRngMax : 24|8@1+ (1,-125) [-125|125] "gear value"  InstrumentCluster_Ch2,Transmission1_Ch2
 SG_ RPTO_BrakeRleasCmd : 44|2@1+ (1,0) [0|3] ""  InstrumentCluster_Ch2,Transmission1_Ch2
 SG_ RPTO_SpdRatioCmd : 59|3@1+ (1,0) [0|7] ""  InstrumentCluster_Ch2,Transmission1_Ch2
 SG_ RPTO_EngagCmd : 62|2@1+ (1,0) [0|3] ""  InstrumentCluster_Ch2,Transmission1_Ch2
 SG_ RPTO_AggrsvnsCmd : 56|3@1+ (1,0) [0|7] ""  InstrumentCluster_Ch2,Transmission1_Ch2
 SG_ TransmReqGear_2 : 48|8@1+ (1,-125) [-125|125] "gear value"  InstrumentCluster_Ch2,Transmission1_Ch2

BO_TX_BU_ 2564488958 : AuxiliaryValveControl_Ch2,REHR_2,REHR_3,REHR_4,REHR_5,FEHR_1,OffBoardDiagnosticTool1_Ch2,FEHR_2,REHR_1;
CM_ BO_ 2632777610 "Transport Protocol - Connection Management";
CM_ SG_ 2632777610 ConnAbrtReason "Reason for connection abort message.";
CM_ SG_ 2632777610 MaxNumPktTPCM_RTS "Maximum number of packets for RTS/CTS message.";
CM_ SG_ 2632777610 NumPktSentTPCM_CTS "Number of Packets that can be sent (TP.CM_CTS)";
CM_ SG_ 2632777610 NxtPktNumSentTPCM_CTS "Next Packet Number to be sent (TP.CM_CTS)";
CM_ SG_ 2632777610 TotMsgSizeBAM "Total message size (in bytes) for BAM message.Total message size (in bytes) for RTS/CTS message.Total message size (in bytes) for RTS/CTS message.";
CM_ SG_ 2632777610 TotMsgSizeEoMA "Total message size (in bytes) for BAM message.Total message size (in bytes) for RTS/CTS message.Total message size (in bytes) for RTS/CTS message.";
CM_ SG_ 2632777610 TotMsgSizeTPCM_RTS "Total message size (in bytes) for BAM message.Total message size (in bytes) for RTS/CTS message.Total message size (in bytes) for RTS/CTS message.";
CM_ SG_ 2632777610 TotNumPktBAM "Total number of packets for BAM message.Total number of packets received for RTS/CTS message.Total number of packets for RTS/CTS message.";
CM_ SG_ 2632777610 TotNumPktEoMA "Total number of packets for BAM message.Total number of packets received for RTS/CTS message.Total number of packets for RTS/CTS message.";
CM_ SG_ 2632777610 TotNumPktTPCM_RTS "Total number of packets for BAM message.Total number of packets received for RTS/CTS message.Total number of packets for RTS/CTS message.";
CM_ BO_ 2566834825 "Active diagnostic trouble codes";
CM_ SG_ 2566834825 AmbrWarnLmp "This lamp is used to relay trouble code information that is reporting a problem with the vehicle system but the vehicle need...";
CM_ SG_ 2566834825 DTC_01 "Diagnostic Trouble Code";
CM_ SG_ 2566834825 DTC_02 "Diagnostic Trouble Code";
CM_ SG_ 2566834825 DTC_03 "Diagnostic Trouble Code";
CM_ SG_ 2566834825 DTC_04 "Diagnostic Trouble Code";
CM_ SG_ 2566834825 FlashAmbrWarnLmpAWL "This parameter provides the capability to flash the AWL (SPN 3040).";
CM_ SG_ 2566834825 FlashMIL "This parameter provides the capability to flash the MIL (SPN 3038).";
CM_ SG_ 2566834825 FlashProtLmp "This parameter provides the capability to flash the engine protect lamp (SPN 3041).";
CM_ SG_ 2566834825 FlashRedStopLmpRSL "This parameter provides the capability to flash the RSL (SPN 3039).";
CM_ SG_ 2566834825 MIL "A lamp used to relay only emissions-related trouble code information.";
CM_ SG_ 2566834825 ProtLmp "This lamp is used to relay trouble code informatio that is reporting a problem with a vehicle system that is most...";
CM_ SG_ 2566834825 RedStopLmp "This lamp is used to relay trouble code information that is of a severe enought condition that it warrants stopping the vehicle.";
CM_ BO_ 2566834826 "Active diagnostic trouble codes";
CM_ SG_ 2566834826 AmbrWarnLmp "This lamp is used to relay trouble code information that is reporting a problem with the vehicle system but the vehicle need...";
CM_ SG_ 2566834826 DTC_01 "Diagnostic Trouble Code";
CM_ SG_ 2566834826 DTC_02 "Diagnostic Trouble Code";
CM_ SG_ 2566834826 DTC_03 "Diagnostic Trouble Code";
CM_ SG_ 2566834826 DTC_04 "Diagnostic Trouble Code";
CM_ SG_ 2566834826 FlashAmbrWarnLmpAWL "This parameter provides the capability to flash the AWL (SPN 3040).";
CM_ SG_ 2566834826 FlashMIL "This parameter provides the capability to flash the MIL (SPN 3038).";
CM_ SG_ 2566834826 FlashProtLmp "This parameter provides the capability to flash the engine protect lamp (SPN 3041).";
CM_ SG_ 2566834826 FlashRedStopLmpRSL "This parameter provides the capability to flash the RSL (SPN 3039).";
CM_ SG_ 2566834826 MIL "A lamp used to relay only emissions-related trouble code information.";
CM_ SG_ 2566834826 ProtLmp "This lamp is used to relay trouble code informatio that is reporting a problem with a vehicle system that is most...";
CM_ SG_ 2566834826 RedStopLmp "This lamp is used to relay trouble code information that is of a severe enought condition that it warrants stopping the vehicle.";
CM_ BO_ 2566834831 "Active diagnostic trouble codes";
CM_ SG_ 2566834831 DTC_01 "Diagnostic Trouble Code";
CM_ SG_ 2566834831 ProtLmp "This lamp is used to relay trouble code informatio that is reporting a problem with a vehicle system that is most...";
CM_ SG_ 2566834831 RedStopLmp "This lamp is used to relay trouble code information that is of a severe enought condition that it warrants stopping the vehicle.";
CM_ SG_ 2566834831 AmbrWarnLmp "This lamp is used to relay trouble code information that is reporting a problem with the vehicle system but the vehicle need...";
CM_ SG_ 2566834831 MIL "A lamp used to relay only emissions-related trouble code information.";
CM_ SG_ 2566834831 FlashAmbrWarnLmpAWL "This parameter provides the capability to flash the AWL (SPN 3040).";
CM_ SG_ 2566834831 FlashMIL "This parameter provides the capability to flash the MIL (SPN 3038).";
CM_ SG_ 2566834831 FlashProtLmp "This parameter provides the capability to flash the engine protect lamp (SPN 3041).";
CM_ SG_ 2566834831 FlashRedStopLmpRSL "This parameter provides the capability to flash the RSL (SPN 3039).";
CM_ BO_ 2632712075 "Transport Protocol - Data Transfer";
CM_ SG_ 2632712075 PktDataTPDT "Relevant data for this PGNs unique use.";
CM_ BO_ 2632777611 "Transport Protocol - Connection Management";
CM_ SG_ 2632777611 ConnAbrtReason "Reason for connection abort message.";
CM_ SG_ 2632777611 MaxNumPktTPCM_RTS "Maximum number of packets for RTS/CTS message.";
CM_ SG_ 2632777611 NumPktSentTPCM_CTS "Number of Packets that can be sent (TP.CM_CTS)";
CM_ SG_ 2632777611 NxtPktNumSentTPCM_CTS "Next Packet Number to be sent (TP.CM_CTS)";
CM_ SG_ 2632777611 TotMsgSizeBAM "Total message size (in bytes) for BAM message.Total message size (in bytes) for RTS/CTS message.Total message size (in bytes) for RTS/CTS message.";
CM_ SG_ 2632777611 TotMsgSizeEoMA "Total message size (in bytes) for BAM message.Total message size (in bytes) for RTS/CTS message.Total message size (in bytes) for RTS/CTS message.";
CM_ SG_ 2632777611 TotMsgSizeTPCM_RTS "Total message size (in bytes) for BAM message.Total message size (in bytes) for RTS/CTS message.Total message size (in bytes) for RTS/CTS message.";
CM_ SG_ 2632777611 TotNumPktBAM "Total number of packets for BAM message.Total number of packets received for RTS/CTS message.Total number of packets for RTS/CTS message.";
CM_ SG_ 2632777611 TotNumPktEoMA "Total number of packets for BAM message.Total number of packets received for RTS/CTS message.Total number of packets for RTS/CTS message.";
CM_ SG_ 2632777611 TotNumPktTPCM_RTS "Total number of packets for BAM message.Total number of packets received for RTS/CTS message.Total number of packets for RTS/CTS message.";
CM_ BO_ 2566838923 "Software Identification. 'On request'. Variable DLC for Joystick Steering Valve (Danfoss) 11 identification fields (see signals) separated by  '*'";
CM_ SG_ 2566838923 Appl_Id_Byte_24 "Software ID. Set to P826vxx or to P662vxx";
CM_ SG_ 2566838923 Appl_Id_Byte_25 "Software ID. Set to P826vxx or to P662vxx";
CM_ SG_ 2566838923 Appl_Id_Byte_26 "Software ID. Set to P826vxx or to P662vxx";
CM_ SG_ 2566838923 Appl_Id_Byte_27 "Software ID. Set to P826vxx or to P662vxx";
CM_ SG_ 2566838923 Appl_Id_Byte_28 "Software ID. Set to P826vxx or to P662vxx";
CM_ SG_ 2566838923 Appl_Id_Byte_29 "Software ID. Set to P826vxx or to P662vxx";
CM_ SG_ 2566838923 Appl_Id_Byte_30 "Software ID. Set to P826vxx or to P662vxx";
CM_ SG_ 2566838923 Appl_Id_Byte_31 "Software ID. Set to P826vxx or to P662vxx";
CM_ SG_ 2566838923 Appl_Id_Byte_32 "Software ID. Set to P826vxx or to P662vxx";
CM_ SG_ 2566838923 Appl_Id_Byte_33 "Software ID. Set to P826vxx or to P662vxx";
CM_ SG_ 2566838923 Appl_Id_Byte_34 "Software ID. Set to P826vxx or to P662vxx";
CM_ SG_ 2566838923 Appl_Id_Byte_35 "Software ID. Set to P826vxx or to P662vxx";
CM_ SG_ 2566838923 Appl_Id_Byte_36 "Software ID. Set to P826vxx or to P662vxx";
CM_ SG_ 2566838923 Appl_Id_Byte_37 "Software ID. Set to P826vxx or to P662vxx";
CM_ SG_ 2566838923 Appl_Id_Byte_38 "Software ID. Set to P826vxx or to P662vxx";
CM_ SG_ 2566838923 Appl_Id_Byte_39 "Software ID. Set to P826vxx or to P662vxx";
CM_ SG_ 2566838923 Appl_Id_Enum "Software ID.";
CM_ SG_ 2566838923 Bootloader_Id "Software ID.";
CM_ SG_ 2566838923 Bootloader_Id_Byte_01 "Software ID.";
CM_ SG_ 2566838923 Bootloader_Id_Byte_02 "Software ID.";
CM_ SG_ 2566838923 Bootloader_Id_Byte_03 "Software ID.";
CM_ SG_ 2566838923 Bootloader_Id_Byte_04 "Software ID.";
CM_ SG_ 2566838923 Bootloader_Id_Byte_05 "Software ID.";
CM_ SG_ 2566838923 Bootloader_Id_Byte_06 "Software ID.";
CM_ SG_ 2566838923 Bootloader_Id_Byte_07 "Software ID.";
CM_ SG_ 2566838923 Bootloader_Id_Byte_08 "Software ID.";
CM_ SG_ 2566838923 Bootloader_Id_Byte_09 "Software ID.";
CM_ SG_ 2566838923 Bootloader_Id_Byte_10 "Software ID.";
CM_ SG_ 2566838923 Bootloader_Id_Byte_11 "Software ID.";
CM_ SG_ 2566838923 Bootloader_Id_Byte_12 "Software ID.";
CM_ SG_ 2566838923 Bootloader_Id_Byte_13 "Software ID.";
CM_ SG_ 2566838923 Bootloader_Id_Byte_14 "Software ID.";
CM_ SG_ 2566838923 Bootloader_Id_Byte_15 "Software ID.";
CM_ SG_ 2566838923 Bootloader_Id_Byte_16 "Software ID.";
CM_ SG_ 2566838923 Bootloader_Id_Byte_17 "Software ID.";
CM_ SG_ 2566838923 Bootloader_Id_Byte_18 "Software ID.";
CM_ SG_ 2566838923 Bootloader_Id_Byte_19 "Software ID.";
CM_ SG_ 2566838923 Bootloader_Id_Byte_20 "Software ID.";
CM_ SG_ 2566838923 Bootloader_Id_Byte_21 "Software ID.";
CM_ SG_ 2566838923 Bootloader_Id_Byte_22 "Software ID.";
CM_ SG_ 2566838923 Bootloader_Id_Byte_23 "Software ID.";
CM_ SG_ 2566838923 Bootloader_Id_Byte_24 "Software ID.";
CM_ SG_ 2566838923 Bootloader_Id_Byte_25 "Software ID.";
CM_ SG_ 2566838923 Bootloader_Id_Byte_26 "Software ID.";
CM_ SG_ 2566838923 Bootloader_Id_Byte_27 "Software ID.";
CM_ SG_ 2566838923 Bootloader_Id_Byte_28 "Software ID.";
CM_ SG_ 2566838923 Bootloader_Id_Byte_29 "Software ID.";
CM_ SG_ 2566838923 Bootloader_Id_Byte_30 "Software ID.";
CM_ SG_ 2566838923 Bootloader_Id_Byte_31 "Software ID.";
CM_ SG_ 2566838923 Bootloader_Id_Byte_32 "Software ID.";
CM_ SG_ 2566838923 Bootloader_Id_Byte_33 "Software ID.";
CM_ SG_ 2566838923 Bootloader_Id_Byte_34 "Software ID.";
CM_ SG_ 2566838923 Bootloader_Id_Byte_35 "Software ID.";
CM_ SG_ 2566838923 Bootloader_Id_Byte_36 "Software ID.";
CM_ SG_ 2566838923 Bootloader_Id_Byte_37 "Software ID.";
CM_ SG_ 2566838923 Bootloader_Id_Byte_38 "Software ID.";
CM_ SG_ 2566838923 Bootloader_Id_Byte_39 "Software ID.";
CM_ SG_ 2566838923 Bootloader_Id_Enum "Software ID.";
CM_ SG_ 2566838923 EndStrng_00 "Software ID. ";
CM_ SG_ 2566838923 EndStrng_01 "Software ID. ";
CM_ SG_ 2566838923 NumSW_IdField "Number of software identification designators represented in the software identification parameter group.";
CM_ SG_ 2566838923 Appl_Id "Software ID. Set to P826vxx or to P662vxx";
CM_ SG_ 2566838923 Appl_Id_Byte_01 "Software ID. Set to P826vxx or to P662vxx";
CM_ SG_ 2566838923 Appl_Id_Byte_02 "Software ID. Set to P826vxx or to P662vxx";
CM_ SG_ 2566838923 Appl_Id_Byte_03 "Software ID. Set to P826vxx or to P662vxx";
CM_ SG_ 2566838923 Appl_Id_Byte_04 "Software ID. Set to P826vxx or to P662vxx";
CM_ SG_ 2566838923 Appl_Id_Byte_05 "Software ID. Set to P826vxx or to P662vxx";
CM_ SG_ 2566838923 Appl_Id_Byte_06 "Software ID. Set to P826vxx or to P662vxx";
CM_ SG_ 2566838923 Appl_Id_Byte_07 "Software ID. Set to P826vxx or to P662vxx";
CM_ SG_ 2566838923 Appl_Id_Byte_08 "Software ID. Set to P826vxx or to P662vxx";
CM_ SG_ 2566838923 Appl_Id_Byte_09 "Software ID. Set to P826vxx or to P662vxx";
CM_ SG_ 2566838923 Appl_Id_Byte_10 "Software ID. Set to P826vxx or to P662vxx";
CM_ SG_ 2566838923 Appl_Id_Byte_11 "Software ID. Set to P826vxx or to P662vxx";
CM_ SG_ 2566838923 Appl_Id_Byte_12 "Software ID. Set to P826vxx or to P662vxx";
CM_ SG_ 2566838923 Appl_Id_Byte_13 "Software ID. Set to P826vxx or to P662vxx";
CM_ SG_ 2566838923 Appl_Id_Byte_14 "Software ID. Set to P826vxx or to P662vxx";
CM_ SG_ 2566838923 Appl_Id_Byte_15 "Software ID. Set to P826vxx or to P662vxx";
CM_ SG_ 2566838923 Appl_Id_Byte_16 "Software ID. Set to P826vxx or to P662vxx";
CM_ SG_ 2566838923 Appl_Id_Byte_17 "Software ID. Set to P826vxx or to P662vxx";
CM_ SG_ 2566838923 Appl_Id_Byte_18 "Software ID. Set to P826vxx or to P662vxx";
CM_ SG_ 2566838923 Appl_Id_Byte_19 "Software ID. Set to P826vxx or to P662vxx";
CM_ SG_ 2566838923 Appl_Id_Byte_20 "Software ID. Set to P826vxx or to P662vxx";
CM_ SG_ 2566838923 Appl_Id_Byte_21 "Software ID. Set to P826vxx or to P662vxx";
CM_ SG_ 2566838923 Appl_Id_Byte_22 "Software ID. Set to P826vxx or to P662vxx";
CM_ SG_ 2566838923 Appl_Id_Byte_23 "Software ID. Set to P826vxx or to P662vxx";
CM_ BO_ 2566871842 "Message used with mid-mounts option (FEHRs).";
CM_ SG_ 2566871842 MsgCnt_EHR "Initial Value 12. Counts from 0 to 11 and then back to 0. 12, 13 are reserved, 14 error, 15 NA. Tecnord EHR Only";
CM_ SG_ 2566871842 EHR_CrvGrad "The characteristic-curve shape allows changes from linear to highly progressive. The fine metering properties of the valve can also be altered in this way, if necessary.";
CM_ SG_ 2566871842 EHR_CrvShp "The characteristic-curve shape allows changes from linear to highly progressive. The fine metering properties of the valve can also be altered in this way, if necessary.";
CM_ SG_ 2566871842 EHR_DynRmpTime "By using time ramps, the dynamics of the valve can be reduced in a well-targeted manner. The time ramp is the time required until the full stroke has been completed (from 0 to 100 % or from 100 to 0 % raising or lowering).";
CM_ SG_ 2566871842 EHR_EvTemp "A measured value to indicate the EHR valve temperature. Used for front & rear EHR's.";
CM_ SG_ 2566871842 EHR_FailSafe "The aim of this function is if an internal fault is detected by the valve, then the valve will default to either neutral or float depending on failsave mode set in the Ehr control message.";
CM_ BO_ 2564487563 "Reserved for ISO 15765";
CM_ SG_ 2564487563 ProtocCntrlInfo "Part of Network Protocol Control Information (N_PCI) of a ISO 15765 message.";
CM_ BO_ 2566855051 "Used only in Bosch EHRs";
CM_ BO_ 2566854795 "Not Used";
CM_ SG_ 2566854795 SpoolPosition "Spool position of the valve (only for Technord EHR).";
CM_ SG_ 2566854795 MsgCnt_EHR "Initial Value 12. Counts from 0 to 11 and then back to 0. 12, 13 are reserved, 14 error, 15 NA. Tecnord EHR Only";
CM_ BO_ 2566866059 "The message is used 'On event' to configure the valves. Every byte not used, to be set 0xFF.";
CM_ SG_ 2566866059 EHR_RmpRndng "A status signal indicating the EHR valve number. Used for front & rear EHR's.";
CM_ SG_ 2566866059 EHR_ChksumSW "Calculated checksum of the application software.";
CM_ SG_ 2566866059 EHR_EvNumParamMux_12 "A status signal indicating the EHR valve number. Used for front & rear EHR's.";
CM_ SG_ 2566866059 EHR_ParamStsByte_2 "The signal has a fix value 0x3B";
CM_ BO_ 2566865547 "During engine cranking, all diagnostics checks shall be disabled to avoid reporting of spurious error. Engine cranking is indicated by ‘init’ parameter in Ehr Control message.";
CM_ SG_ 2566865547 EHR_EvTemp "A measured value to indicate the EHR valve temperature. Used for front & rear EHR's.";
CM_ SG_ 2566865547 EHR_SysId "NOT USED";
CM_ SG_ 2566865547 EHR_Err "A status signal indicating the EHR fault condition. Sent by both front & rear EHR's.";
CM_ SG_ 2566865547 EHR_InitDiag "A status signal indicating the EHR fault condition. Sent by both front & rear EHR's.";
CM_ SG_ 2566865547 EHR_ErrCod "A status value to indicate the EHR fault code. Used for front & rear EHR's.";
CM_ BO_ 2566835083 "Previously active diagnostic trouble codes";
CM_ SG_ 2566835083 DTC_01 "Diagnostic Trouble Code";
CM_ SG_ 2566835083 FlashAmbrWarnLmpAWL "This parameter provides the capability to flash the AWL (SPN 3040).";
CM_ SG_ 2566835083 FlashMIL "This parameter provides the capability to flash the MIL (SPN 3038).";
CM_ SG_ 2566835083 FlashProtLmp "This parameter provides the capability to flash the engine protect lamp (SPN 3041).";
CM_ SG_ 2566835083 FlashRedStopLmpRSL "This parameter provides the capability to flash the RSL (SPN 3039).";
CM_ SG_ 2566835083 ProtLmp "This lamp is used to relay trouble code informatio that is reporting a problem with a vehicle system that is most...";
CM_ SG_ 2566835083 AmbrWarnLmp "This lamp is used to relay trouble code information that is reporting a problem with the vehicle system but the vehicle need...";
CM_ SG_ 2566835083 RedStopLmp "This lamp is used to relay trouble code information that is of a severe enought condition that it warrants stopping the vehicle.";
CM_ SG_ 2566835083 MIL "A lamp used to relay only emissions-related trouble code information.";
CM_ BO_ 2566834827 "Active diagnostic trouble codes";
CM_ SG_ 2566834827 DTC_10 "Diagnostic Trouble Code";
CM_ SG_ 2566834827 DTC_09 "Diagnostic Trouble Code";
CM_ SG_ 2566834827 DTC_08 "Diagnostic Trouble Code";
CM_ SG_ 2566834827 DTC_07 "Diagnostic Trouble Code";
CM_ SG_ 2566834827 DTC_06 "Diagnostic Trouble Code";
CM_ SG_ 2566834827 DTC_05 "Diagnostic Trouble Code";
CM_ SG_ 2566834827 DTC_04 "Diagnostic Trouble Code";
CM_ SG_ 2566834827 DTC_03 "Diagnostic Trouble Code";
CM_ SG_ 2566834827 DTC_02 "Diagnostic Trouble Code";
CM_ SG_ 2566834827 DTC_01 "Diagnostic Trouble Code";
CM_ SG_ 2566834827 ProtLmp "This lamp is used to relay trouble code informatio that is reporting a problem with a vehicle system that is most...";
CM_ SG_ 2566834827 RedStopLmp "This lamp is used to relay trouble code information that is of a severe enought condition that it warrants stopping the vehicle.";
CM_ SG_ 2566834827 AmbrWarnLmp "This lamp is used to relay trouble code information that is reporting a problem with the vehicle system but the vehicle need...";
CM_ SG_ 2566834827 MIL "A lamp used to relay only emissions-related trouble code information.";
CM_ SG_ 2566834827 FlashAmbrWarnLmpAWL "This parameter provides the capability to flash the AWL (SPN 3040).";
CM_ SG_ 2566834827 FlashMIL "This parameter provides the capability to flash the MIL (SPN 3038).";
CM_ SG_ 2566834827 FlashProtLmp "This parameter provides the capability to flash the engine protect lamp (SPN 3041).";
CM_ SG_ 2566834827 FlashRedStopLmpRSL "This parameter provides the capability to flash the RSL (SPN 3039).";
CM_ BO_ 2499803431 "Used for information on brake control.";
CM_ SG_ 2499803431 MsgChksum_3 "The message checksum is used to verify the signal path from the transmitting device to the receiving device. The message checksum is calculated using the first 7 data bytes, the message counter and the bytes of the message identifier. It is calculated...";
CM_ SG_ 2499803431 MsgCnt "Init Value 12. The transmitter will increase the counter in every cycle,  0 to 11 and then wrap.14 Error, 15 NA. Used to detect situations where the transmitting ECU malfunction repeats the same frame all the time";
CM_ SG_ 2499803431 ExtPrsRqst "brake pressure that the trailer is expected to realize";
CM_ SG_ 2499803431 XPD_CntrlMode "Shall be used as in input to the brake system and define how the external pressure demand has to be realized";
CM_ SG_ 2499803431 XPD_Prio "Shall be used as in input to the brake system to manage the priority of overlapping external and internal requests";
CM_ SG_ 2499743527 MsgCnt "Init Value 12. The transmitter will increase the counter in every cycle,  0 to 11 and then wrap.14 Error, 15 NA. Used to detect situations where the transmitting ECU malfunction repeats the same frame all the time";
CM_ SG_ 2499743527 MsgChksum_3 "The message checksum is used to verify the signal path from the transmitting device to the receiving device. The message checksum is calculated using the first 7 data bytes, the message counter and the bytes of the message identifier. It is calculated...";
CM_ SG_ 2499743527 RightBrakePedPositn "Not relevant for CNHi-Ratio of the right brake pedal position to maximum right brake pedal position. 0% means no braking. The maximum of this (Right Brake Pedal Position) and SPN 3033 (Left Brake Pedal Position) should be transmitted as SPN 521";
CM_ SG_ 2499743527 LeftBrakePedPositn "Not relevant for CNHi-Ratio of the left brake pedal position to maximum left brake pedal position. 0% means no braking. The maximum of this (Left Brake Pedal Position) and SPN 3032 (Right Brake Pedal Position) should be transmitted as SPN 521";
CM_ SG_ 2499743527 RightBrakeSts "VCL-DCL10-188 - This is the signal used by the VCL to notify the DCL about the Right Brake Pedal status";
CM_ SG_ 2499743527 LeftBrakeSts "VCL-DCL10-188 - This is the signal used by the VCL to notify the DCL about the Left Brake Pedal status";
CM_ SG_ 2499743527 SecBrakePositn "Ratio of handbrake  position to maximum handbrakel position. 0% means no braking.";
CM_ BO_ 2566857475 "This message replaces PB_DEC_PowerStatus_03 on architectures with DEC2.0 ";
CM_ BO_ 2564488958 "Reserved for ISO 15765";
CM_ SG_ 2564488958 ProtocCntrlInfo "Part of Network Protocol Control Information (N_PCI) of a ISO 15765 message.";
CM_ BO_ 2565603086 "Transport Protocol - Data Transfer";
CM_ SG_ 2565603086 PktDataTPDT "Relevant data for this PGNs unique use.";
CM_ SG_ 2499785475 DrvlRecovReq "VCL-DCL10-59 - The DCL informs VCL about the effect on the vehicle that is in progress due to an internal recovery status";
CM_ SG_ 2499785475 RngLckFdbk "This is the signal is the feedback (logical) of  Range lock signal";
CM_ SG_ 2499785475 VehSpdSecSetpFdbk "VCL-DCL10-653 Internal Wheel Speed Setpoint for Driveline to be used for populating correctly the bar graph. This signal has the aim to advise the VCL on the target speed that the DEC has stored.";
CM_ SG_ 2499785475 DecelTorq "VCL-DCL10-452";
CM_ BO_ 2566877699 "The message contains the set of data of a specific ECU that are needed to other ECUs.";
CM_ SG_ 2566877699 PBrakeTyp "A signal from the DEC to to the UCM to communicate the Parking Brake Type.";
CM_ SG_ 2566877699 CreeprPresence "A signal from the DEC to to the UCM to communicate if the Creeper feature is installed.";
CM_ SG_ 2566877699 DrvlTyp "A signal from the DEC to to the UCM to communicate the Driveline Type.";
CM_ SG_ 2566877699 EPL_Presence "Signal for Electronic Park Lock presence.";
CM_ SG_ 2566877699 MFD_Presence "A signal from the DEC to to the UCM to communicate if the Mechanical Front Drive is installed.";
CM_ SG_ 2566877699 OverDrivPresence "A signal from the DEC to to the UCM to communicate if the Overdrive is installed.";
CM_ SG_ 2566877699 PTO_Typ "A signal from the DEC to to the UCM to communicate the PTO Type.";
CM_ SG_ 2566877699 FrntDifflckSolPresence "VCL-DCL10-692";
CM_ BO_ 2565351182 "The Acknowledgment PG is used to provide a handshake mechanism between transmitting and receiving devices";
CM_ SG_ 2565351182 GrpFunctValAck "Group Function of PGN being acknowledged. This field identifies for a device the specific group function of a PGN being acknowledged or declined.  This field is not used if the PGN being acknowledged or declined is not a group function PGN.";
CM_ SG_ 2565351182 PGN_RQST2_0E_27 "PGN which is requested by Request2 message";
CM_ BO_ 2565351171 "The Acknowledgment PG is used to provide a handshake mechanism between transmitting and receiving devices.";
CM_ SG_ 2565351171 GrpFunctValAck "Group Function of PGN being acknowledged. This field identifies for a device the specific group function of a PGN being acknowledged or declined.  This field is not used if the PGN being acknowledged or declined is not a group function PGN.";
CM_ SG_ 2565351171 PGN_RQST2_03_27 "PGN which is requested by Request2 message";
CM_ BO_ 2566888195 "Message used to send to UCM some transmission parameters. This message was added after UCM-DEC splitting.Sent on event";
CM_ SG_ 2566888195 GearMapAv "VCL-DCL10-77 - DCL informs VCL about the gears that are not inhibited for fault; Bitmap: ‘1’ = available, ‘0’ = not available; the first 32 bits are used for FWD gears; The second 32 bits are used for REV gears; Creeper gear start at bit 0";
CM_ SG_ 2566871043 AxId " Signal containing Axle Type. Used for anti-tamper protection.
";
CM_ BO_ 2499798019 "All not used bits must be set at 1. Cycle time must be finalized (default value = 10 ms)";
CM_ SG_ 2499798019 Hrtbt "Init Value 251; The transmitter will increase the counter in every cycle,  0 to 250 and then wrap.254 Error; 255 NA. Approach Unilateral";
CM_ SG_ 2499798019 MsgChksum_4 "Chksum = (Byte1 + (Byte2 & 0x0F) + Byte3 + Byte4 + Byte5 + Byte6 + Byte7 + Bytes8 + msgID byte1 + msgID byte2 + msgID byte3 + msgID byte4)  = (((chksum >> 6) & 0x03) + (chksum >>3) + chksum) & 0x07 = ((chksum & 0x0F) << 4) + (chksum & 0x0F)";
CM_ SG_ 2499798019 SpecialModeResp "Not used on CH26. Setup with a value !=1 by all the other ECU that is receiving the Rqst information, on the WL SFB and maybe UCM";
CM_ SG_ 2499798019 SpecialModeReq "Not used on CH26. Setup with a value != 7 by each ECU that want to advise that it is starting a special mode, for the WL the display";
CM_ SG_ 2499798019 ThisNetReq "Request to hold the net on which the ECU is performing the communication. Set to 11b if not managed";
CM_ SG_ 2499798019 BattMainSwHoldReq "Request to hold the battery main switch.";
CM_ SG_ 2499798019 KeyPositn "Bitmapped signal that indicates the Key position.";
CM_ SG_ 2499798019 BattMainSwHoldFunct "Managed by ECU performing the Manitain Power. Set to 0xF if not managed";
CM_ SG_ 2499798019 OpSeatSw "Senses the presence of the operator in the seat. (Satisfies requirement VCL-DCL10-357 only when mapped into PB_Heartbeat_27_03.)";
CM_ SG_ 2499798019 AutoGuideEnaSts "A status signal indicating the activation command sent to a subsystem. On the 'autoguidance' the transition 01->00 doesn't cause a status change (disable command not permitted). If not managed, set to 11b";
CM_ SG_ 2499798019 WakeUpInDozeMode "Managed by ECU performing the Network Management. Set to 11b if not managed";
CM_ SG_ 2499798019 WakeUpFunct "Managed by ECU performing the Manitain Power. Set to 0xF if not managed";
CM_ SG_ 2499798019 VehMov "Set to 11b if not managed";
CM_ SG_ 2499798019 IgnON "Managed by ECU performing the Network Management. Set to 11b if not managed";
CM_ SG_ 2499798019 EngStartSts "If not managed, set to (11b)";
CM_ SG_ 2499798019 EngRun "Set to 11b if not managed";
CM_ BO_ 2565799819 "Address Claimed";
CM_ SG_ 2565799819 Rsrvd_1Bit "Set to 0 for J1939-81";
CM_ BO_ 2565406603 "The Acknowledgment PG is used to provide a handshake mechanism between transmitting and receiving devices.";
CM_ SG_ 2565406603 GrpFunctValAck "Group Function of PGN being acknowledged. This field identifies for a device the specific group function of a PGN being acknowledged or declined.  This field is not used if the PGN being acknowledged or declined is not a group function PGN.";
CM_ SG_ 2565406603 PGN_RQST2_EHR "PGN which is requested by Request2 message";
CM_ BO_ 2499777575 "Message used to send to DEC some parameters. This message was added after UCM-DEC splitting";
CM_ SG_ 2499777575 CalibrStart "VCL-DCL10-368 - UCM will need to send a CAN message to the other modules (display and DEC at a minimum) to notify them when the calibration starts";
CM_ SG_ 2499777575 CalibrModeEna "VCL-DCL10-367 - UCM will need to send a CAN message to the other modules (display and DEC at a minimum) to notify them that calibration mode has been enabled to allow certain calibrations";
CM_ SG_ 2499777575 WhRevolSpdLim "VCL-DCL10-359 - Used to inform the DEC about the speed that shall never be exceed. It will include the tolerance (e.g, if the homologation limit is 40 kph, the signal will be calculated based on 42.5 kph). Min and Max value depends on the Specific Vehicle";
CM_ SG_ 2499777575 SelAggrsvns "VCL-DCL10-81 - The VCL will send to the DCL the aggressiveness, that will define the performance requested to reach the targetnd it will defined in terms of percentage. The performance details will be defined for each specific platform";
CM_ SG_ 2499777575 GearRngMin "VCL-DCL10-70 - Describes minimum gear range for autofunction/APM";
CM_ SG_ 2499777575 GearRngMax "VCL-DCL10-70 - Describes Maximum gear range for autofunction/APM";
CM_ SG_ 2499777575 RPTO_BrakeRleasCmd "VCL-DCL10-323 - Brake Release Request";
CM_ SG_ 2499777575 RPTO_SpdRatioCmd "VCL-DCL10-330";
CM_ SG_ 2499777575 RPTO_EngagCmd "VCL-DCL10-321 - This signal is used to request to the Driveline the RPTO Engagement";
CM_ SG_ 2499777575 RPTO_AggrsvnsCmd "VCL-DCL10-322 - This signal is used to request a specific RPTO Aggressiveness";
CM_ SG_ 2499777575 TransmReqGear_2 "VCL-DCL10-68 - Gear requested by the operator/VCL. Negative values are reverse gears, positive values are forward gears, zero is neutral.";
BA_DEF_ SG_  "GenSigReceiveSetting" STRING ;
BA_DEF_ SG_  "GenSigPreSetting" STRING ;
BA_DEF_ SG_  "GenSigPreIfSetting" STRING ;
BA_DEF_ SG_  "GenSigPostSetting" STRING ;
BA_DEF_ SG_  "GenSigPostIfSetting" STRING ;
BA_DEF_ SG_  "GenSigEnvVarType" ENUM  "int","float","undef";
BA_DEF_ SG_  "GenSigConditionalSend" STRING ;
BA_DEF_ SG_  "GenSigAutoGenSnd" ENUM  "No","Yes";
BA_DEF_ SG_  "GenSigAutoGenDsp" ENUM  "No","Yes";
BA_DEF_ SG_  "GenSigAssignSetting" STRING ;
BA_DEF_ SG_  "GenSigAltSetting" STRING ;
BA_DEF_ SG_  "SPN_Definition" STRING ;
BA_DEF_ SG_  "External_Reference_decod" STRING ;
BA_DEF_ SG_  "UtilizationOnNetwork" ENUM  "Used","NOT USED";
BA_DEF_ SG_  "CI_RepetitionNum" ENUM  "1","2";
BA_DEF_ SG_  "CI_RepetitionType" ENUM  "NA","1","2","3","4";
BA_DEF_ SG_  "CI_RepetitionComplemented" ENUM  "0","1","vector_leerstring";
BA_DEF_ SG_  "DDI" INT 0 65535;
BA_DEF_ SG_  "CI_FullName" STRING ;
BA_DEF_ SG_  "GenSigTimeoutTime" INT 0 3600000;
BA_DEF_ SG_  "CI_ParId" STRING ;
BA_DEF_ SG_  "CI_SLOT_Name" STRING ;
BA_DEF_ SG_  "CI_ParVersion" STRING ;
BA_DEF_ SG_  "GenSigSendType" ENUM  "Cyclic","OnWrite","OnWriteWithRepetition","OnChange","OnChangeWithRepetition","IfActive","IfActiveWithRepetition","NoSigSendType";
BA_DEF_ SG_  "GenSigInactiveValue" INT 0 2147483647;
BA_DEF_ SG_  "GenSigStartValue" INT 0 2147483647;
BA_DEF_ SG_  "GenSigEVName" STRING ;
BA_DEF_ SG_  "SPN" INT 0 524287;
BA_DEF_ SG_  "SigType" ENUM  "Default","Range","RangeSigned","ASCII","Discrete","Control","ReferencePGN","DTC","StringDelimiter","StringLength","StringLengthControl";
BA_DEF_ SG_  "GenSigILSupport" ENUM  "Yes","No";
BA_DEF_ BO_  "ShowSignals" INT -1 0;
BA_DEF_ BO_  "GroupSignals" INT 1 100;
BA_DEF_ BO_  "PGN_Definition" STRING ;
BA_DEF_ BO_  "External_Reference" STRING ;
BA_DEF_ BO_  "SingleFrame" INT 0 1;
BA_DEF_ BO_  "CI_AllowedLostMessages" ENUM  "NA","0","1","2","3","4";
BA_DEF_ BO_  "CI_AliveTimeout" INT 0 3600000;
BA_DEF_ BO_  "TpJ1939VarDlc" ENUM  "No","Yes";
BA_DEF_ BO_  "CI_ShowSignals" INT -1 0;
BA_DEF_ BO_  "CI_PgVersion" STRING ;
BA_DEF_ BO_  "CI_GroupSignals" INT 1 100;
BA_DEF_ BO_  "DiagUUDTResponse" ENUM  "No","Yes";
BA_DEF_ BO_  "DiagState" ENUM  "No","Yes";
BA_DEF_ BO_  "DiagResponse" ENUM  "No","Yes";
BA_DEF_ BO_  "DiagRequest" ENUM  "No","Yes";
BA_DEF_ BO_  "DiagConnection" INT 0 65535;
BA_DEF_ BO_  "GenMsgNrOfRepetition" INT 0 1000000;
BA_DEF_ BO_  "GenMsgILSupport" ENUM  "No","Yes";
BA_DEF_ BO_  "GenMsgFastOnStart" INT 0 100000;
BA_DEF_ BO_  "GenMsgCycleTimeFast" INT 0 3600000;
BA_DEF_ BO_  "GenMsgStartDelayTime" INT 0 100000;
BA_DEF_ BO_  "GenMsgDelayTime" INT 0 3600000;
BA_DEF_ BO_  "VFrameFormat" ENUM  "StandardCAN","ExtendedCAN","reserved","J1939PG";
BA_DEF_ BO_  "GenMsgCycleTime" INT 0 3600000;
BA_DEF_ BO_  "GenMsgRequestable" INT 0 1;
BA_DEF_ BO_  "GenMsgSendType" ENUM  "cyclic","reserved","cyclicIfActive","reserved","reserved","reserved","reserved","reserved","noMsgSendType";
BA_DEF_DEF_  "GenSigReceiveSetting" "";
BA_DEF_DEF_  "GenSigPreSetting" "";
BA_DEF_DEF_  "GenSigPreIfSetting" "";
BA_DEF_DEF_  "GenSigPostSetting" "";
BA_DEF_DEF_  "GenSigPostIfSetting" "";
BA_DEF_DEF_  "GenSigEnvVarType" "undef";
BA_DEF_DEF_  "GenSigConditionalSend" "";
BA_DEF_DEF_  "GenSigAutoGenSnd" "";
BA_DEF_DEF_  "GenSigAutoGenDsp" "";
BA_DEF_DEF_  "GenSigAssignSetting" "";
BA_DEF_DEF_  "GenSigAltSetting" "";
BA_DEF_DEF_  "SPN_Definition" "";
BA_DEF_DEF_  "External_Reference_decod" "";
BA_DEF_DEF_  "UtilizationOnNetwork" "Used";
BA_DEF_DEF_  "CI_RepetitionNum" "1";
BA_DEF_DEF_  "CI_RepetitionType" "NA";
BA_DEF_DEF_  "CI_RepetitionComplemented" "0";
BA_DEF_DEF_  "DDI" 0;
BA_DEF_DEF_  "CI_FullName" "";
BA_DEF_DEF_  "GenSigTimeoutTime" 0;
BA_DEF_DEF_  "CI_ParId" "";
BA_DEF_DEF_  "CI_SLOT_Name" "0";
BA_DEF_DEF_  "CI_ParVersion" "0";
BA_DEF_DEF_  "GenSigSendType" "NoSigSendType";
BA_DEF_DEF_  "GenSigInactiveValue" 0;
BA_DEF_DEF_  "GenSigStartValue" 0;
BA_DEF_DEF_  "GenSigEVName" "Env@Nodename_@Signame";
BA_DEF_DEF_  "SPN" 0;
BA_DEF_DEF_  "SigType" "Default";
BA_DEF_DEF_  "GenSigILSupport" "Yes";
BA_DEF_DEF_  "ShowSignals" -1;
BA_DEF_DEF_  "GroupSignals" 1;
BA_DEF_DEF_  "PGN_Definition" "N/A";
BA_DEF_DEF_  "External_Reference" "";
BA_DEF_DEF_  "SingleFrame" 1;
BA_DEF_DEF_  "CI_AllowedLostMessages" "NA";
BA_DEF_DEF_  "CI_AliveTimeout" 0;
BA_DEF_DEF_  "TpJ1939VarDlc" "No";
BA_DEF_DEF_  "CI_ShowSignals" -1;
BA_DEF_DEF_  "CI_PgVersion" "0";
BA_DEF_DEF_  "CI_GroupSignals" 1;
BA_DEF_DEF_  "DiagUUDTResponse" "No";
BA_DEF_DEF_  "DiagState" "No";
BA_DEF_DEF_  "DiagResponse" "No";
BA_DEF_DEF_  "DiagRequest" "No";
BA_DEF_DEF_  "DiagConnection" 0;
BA_DEF_DEF_  "GenMsgNrOfRepetition" 0;
BA_DEF_DEF_  "GenMsgILSupport" "Yes";
BA_DEF_DEF_  "GenMsgFastOnStart" 0;
BA_DEF_DEF_  "GenMsgCycleTimeFast" 0;
BA_DEF_DEF_  "GenMsgStartDelayTime" 0;
BA_DEF_DEF_  "GenMsgDelayTime" 1;
BA_DEF_DEF_  "VFrameFormat" "J1939PG";
BA_DEF_DEF_  "GenMsgCycleTime" 0;
BA_DEF_DEF_  "GenMsgRequestable" 0;
BA_DEF_DEF_  "GenMsgSendType" "noMsgSendType";
BA_ "TpJ1939VarDlc" BO_ 2632777610 1;
BA_ "CI_ShowSignals" BO_ 2632777610 0;
BA_ "CI_AliveTimeout" BO_ 2566834825 3000;
BA_ "CI_ShowSignals" BO_ 2566834825 0;
BA_ "GenMsgCycleTime" BO_ 2566834825 1000;
BA_ "GenMsgSendType" BO_ 2566834825 0;
BA_ "CI_AliveTimeout" BO_ 2566834826 3000;
BA_ "TpJ1939VarDlc" BO_ 2566834826 1;
BA_ "CI_ShowSignals" BO_ 2566834826 0;
BA_ "GenMsgCycleTime" BO_ 2566834826 1000;
BA_ "GenMsgSendType" BO_ 2566834826 0;
BA_ "TpJ1939VarDlc" BO_ 2566834831 1;
BA_ "CI_ShowSignals" BO_ 2566834831 0;
BA_ "CI_GroupSignals" BO_ 2566834831 4;
BA_ "GenMsgCycleTime" BO_ 2566834831 1000;
BA_ "GenMsgSendType" BO_ 2566834831 0;
BA_ "TpJ1939VarDlc" BO_ 2632712075 1;
BA_ "CI_ShowSignals" BO_ 2632712075 0;
BA_ "TpJ1939VarDlc" BO_ 2632777611 1;
BA_ "CI_ShowSignals" BO_ 2632777611 0;
BA_ "PGN_Definition" BO_ 2566838923 "J1939 Standard";
BA_ "CI_ShowSignals" BO_ 2566838923 0;
BA_ "CI_PgVersion" BO_ 2566838923 "-1";
BA_ "CI_GroupSignals" BO_ 2566838923 10;
BA_ "GenMsgRequestable" BO_ 2566838923 1;
BA_ "CI_AliveTimeout" BO_ 2566871842 400;
BA_ "GenMsgCycleTime" BO_ 2566871842 100;
BA_ "GenMsgSendType" BO_ 2566871842 0;
BA_ "TpJ1939VarDlc" BO_ 2564487563 1;
BA_ "CI_ShowSignals" BO_ 2564487563 0;
BA_ "DiagResponse" BO_ 2564487563 1;
BA_ "CI_ShowSignals" BO_ 2566855051 0;
BA_ "GenMsgCycleTime" BO_ 2566855051 100;
BA_ "GenMsgSendType" BO_ 2566855051 0;
BA_ "CI_ShowSignals" BO_ 2566854795 0;
BA_ "GenMsgCycleTime" BO_ 2566854795 100;
BA_ "GenMsgSendType" BO_ 2566854795 0;
BA_ "CI_ShowSignals" BO_ 2566866059 0;
BA_ "CI_AllowedLostMessages" BO_ 2566865547 4;
BA_ "CI_AliveTimeout" BO_ 2566865547 300;
BA_ "CI_ShowSignals" BO_ 2566865547 0;
BA_ "GenMsgCycleTime" BO_ 2566865547 100;
BA_ "GenMsgSendType" BO_ 2566865547 0;
BA_ "TpJ1939VarDlc" BO_ 2566835083 1;
BA_ "CI_ShowSignals" BO_ 2566835083 0;
BA_ "GenMsgRequestable" BO_ 2566835083 1;
BA_ "CI_AliveTimeout" BO_ 2566834827 3000;
BA_ "TpJ1939VarDlc" BO_ 2566834827 1;
BA_ "CI_ShowSignals" BO_ 2566834827 0;
BA_ "GenMsgCycleTime" BO_ 2566834827 1000;
BA_ "GenMsgSendType" BO_ 2566834827 0;
BA_ "CI_AllowedLostMessages" BO_ 2499803431 2;
BA_ "CI_AliveTimeout" BO_ 2499803431 800;
BA_ "TpJ1939VarDlc" BO_ 2499803431 1;
BA_ "GenMsgCycleTimeFast" BO_ 2499803431 20;
BA_ "GenMsgCycleTime" BO_ 2499803431 200;
BA_ "GenMsgSendType" BO_ 2499803431 0;
BA_ "GenMsgCycleTime" BO_ 2499743527 10;
BA_ "GenMsgSendType" BO_ 2499743527 0;
BA_ "GenMsgCycleTime" BO_ 2566857475 10;
BA_ "TpJ1939VarDlc" BO_ 2564488958 1;
BA_ "CI_ShowSignals" BO_ 2564488958 0;
BA_ "TpJ1939VarDlc" BO_ 2565603086 1;
BA_ "CI_ShowSignals" BO_ 2565603086 0;
BA_ "CI_AliveTimeout" BO_ 2499785475 40;
BA_ "GenMsgCycleTime" BO_ 2499785475 10;
BA_ "GenMsgSendType" BO_ 2499785475 0;
BA_ "GenMsgRequestable" BO_ 2566877699 1;
BA_ "CI_ShowSignals" BO_ 2565351182 0;
BA_ "CI_PgVersion" BO_ 2565351182 "-1";
BA_ "CI_GroupSignals" BO_ 2565351182 8;
BA_ "External_Reference" BO_ 2565351171 "0";
BA_ "CI_PgVersion" BO_ 2565351171 "-1";
BA_ "CI_GroupSignals" BO_ 2565351171 50;
BA_ "CI_AliveTimeout" BO_ 2566888195 2000;
BA_ "GenMsgCycleTime" BO_ 2566888195 500;
BA_ "GenMsgSendType" BO_ 2566888195 0;
BA_ "GenMsgRequestable" BO_ 2566871043 1;
BA_ "CI_AllowedLostMessages" BO_ 2499798019 3;
BA_ "CI_AliveTimeout" BO_ 2499798019 40;
BA_ "CI_GroupSignals" BO_ 2499798019 2;
BA_ "GenMsgCycleTime" BO_ 2499798019 10;
BA_ "GenMsgSendType" BO_ 2499798019 0;
BA_ "TpJ1939VarDlc" BO_ 2565799819 1;
BA_ "CI_ShowSignals" BO_ 2565799819 0;
BA_ "CI_ShowSignals" BO_ 2565406603 0;
BA_ "CI_PgVersion" BO_ 2565406603 "-1";
BA_ "CI_AliveTimeout" BO_ 2499777575 40;
BA_ "GenMsgCycleTime" BO_ 2499777575 10;
BA_ "GenMsgSendType" BO_ 2499777575 0;
BA_ "GenSigAutoGenSnd" SG_ 2632777610 CByteTPCM 0;
BA_ "GenSigAutoGenDsp" SG_ 2632777610 CByteTPCM 0;
BA_ "CI_RepetitionComplemented" SG_ 2632777610 CByteTPCM 2;
BA_ "CI_FullName" SG_ 2632777610 CByteTPCM "Control Byte (TP.CM)";
BA_ "CI_ParId" SG_ 2632777610 CByteTPCM "ESMD_00941";
BA_ "SPN" SG_ 2632777610 CByteTPCM 2556;
BA_ "GenSigAutoGenSnd" SG_ 2632777610 ConnAbrtReason 0;
BA_ "GenSigAutoGenDsp" SG_ 2632777610 ConnAbrtReason 0;
BA_ "CI_RepetitionComplemented" SG_ 2632777610 ConnAbrtReason 2;
BA_ "CI_FullName" SG_ 2632777610 ConnAbrtReason "Connection Abort Reason";
BA_ "CI_ParId" SG_ 2632777610 ConnAbrtReason "ESMD_00939";
BA_ "SPN" SG_ 2632777610 ConnAbrtReason 2570;
BA_ "GenSigAutoGenSnd" SG_ 2632777610 MaxNumPktTPCM_RTS 0;
BA_ "GenSigAutoGenDsp" SG_ 2632777610 MaxNumPktTPCM_RTS 0;
BA_ "CI_RepetitionComplemented" SG_ 2632777610 MaxNumPktTPCM_RTS 2;
BA_ "CI_FullName" SG_ 2632777610 MaxNumPktTPCM_RTS "Maximum Number of Packets (TP.CM_RTS)";
BA_ "CI_ParId" SG_ 2632777610 MaxNumPktTPCM_RTS "ESMD_02684";
BA_ "SPN" SG_ 2632777610 MaxNumPktTPCM_RTS 2559;
BA_ "GenSigAutoGenSnd" SG_ 2632777610 NumPktSentTPCM_CTS 0;
BA_ "GenSigAutoGenDsp" SG_ 2632777610 NumPktSentTPCM_CTS 0;
BA_ "CI_RepetitionComplemented" SG_ 2632777610 NumPktSentTPCM_CTS 2;
BA_ "CI_FullName" SG_ 2632777610 NumPktSentTPCM_CTS "Number of Packets that can be sent (TP.CM_CTS)";
BA_ "CI_ParId" SG_ 2632777610 NumPktSentTPCM_CTS "ESMD_02790";
BA_ "SPN" SG_ 2632777610 NumPktSentTPCM_CTS 2561;
BA_ "GenSigAutoGenSnd" SG_ 2632777610 NxtPktNumSentTPCM_CTS 0;
BA_ "GenSigAutoGenDsp" SG_ 2632777610 NxtPktNumSentTPCM_CTS 0;
BA_ "CI_RepetitionComplemented" SG_ 2632777610 NxtPktNumSentTPCM_CTS 2;
BA_ "CI_FullName" SG_ 2632777610 NxtPktNumSentTPCM_CTS "Next Packet Number to be sent (TP.CM_CTS)";
BA_ "CI_ParId" SG_ 2632777610 NxtPktNumSentTPCM_CTS "ESMD_02740";
BA_ "SPN" SG_ 2632777610 NxtPktNumSentTPCM_CTS 2562;
BA_ "GenSigAutoGenSnd" SG_ 2632777610 PGN_PktMsgTPCM_BAM 0;
BA_ "GenSigAutoGenDsp" SG_ 2632777610 PGN_PktMsgTPCM_BAM 0;
BA_ "CI_RepetitionComplemented" SG_ 2632777610 PGN_PktMsgTPCM_BAM 2;
BA_ "CI_FullName" SG_ 2632777610 PGN_PktMsgTPCM_BAM "Parameter Group Number of the packeted message (TP.CM_BAM)";
BA_ "CI_ParId" SG_ 2632777610 PGN_PktMsgTPCM_BAM "ESMD_03861";
BA_ "SPN" SG_ 2632777610 PGN_PktMsgTPCM_BAM 2569;
BA_ "GenSigAutoGenSnd" SG_ 2632777610 PGN_PktMsgTPCM_ConnAbort 0;
BA_ "GenSigAutoGenDsp" SG_ 2632777610 PGN_PktMsgTPCM_ConnAbort 0;
BA_ "CI_RepetitionComplemented" SG_ 2632777610 PGN_PktMsgTPCM_ConnAbort 2;
BA_ "CI_FullName" SG_ 2632777610 PGN_PktMsgTPCM_ConnAbort "Parameter Group Number of the packeted message (TP.CM_Conn_Abort)";
BA_ "CI_ParId" SG_ 2632777610 PGN_PktMsgTPCM_ConnAbort "ESMD_03862";
BA_ "SPN" SG_ 2632777610 PGN_PktMsgTPCM_ConnAbort 2571;
BA_ "GenSigAutoGenSnd" SG_ 2632777610 PGN_PktMsgTPCM_CTS 0;
BA_ "GenSigAutoGenDsp" SG_ 2632777610 PGN_PktMsgTPCM_CTS 0;
BA_ "CI_RepetitionComplemented" SG_ 2632777610 PGN_PktMsgTPCM_CTS 2;
BA_ "CI_FullName" SG_ 2632777610 PGN_PktMsgTPCM_CTS "Parameter Group Number of the packeted message (TP.CM_CTS)";
BA_ "CI_ParId" SG_ 2632777610 PGN_PktMsgTPCM_CTS "ESMD_03859";
BA_ "SPN" SG_ 2632777610 PGN_PktMsgTPCM_CTS 2563;
BA_ "GenSigAutoGenSnd" SG_ 2632777610 PGN_PktMsgTPCM_RTS 0;
BA_ "GenSigAutoGenDsp" SG_ 2632777610 PGN_PktMsgTPCM_RTS 0;
BA_ "CI_RepetitionComplemented" SG_ 2632777610 PGN_PktMsgTPCM_RTS 2;
BA_ "CI_FullName" SG_ 2632777610 PGN_PktMsgTPCM_RTS "Parameter Group Number of the packeted message (TP.CM_RTS)";
BA_ "CI_ParId" SG_ 2632777610 PGN_PktMsgTPCM_RTS "ESMD_02869";
BA_ "SPN" SG_ 2632777610 PGN_PktMsgTPCM_RTS 2560;
BA_ "CI_FullName" SG_ 2632777610 PGN_PktMsgTPCM_RTS2 "Parameter Group Number of the packeted message (TP.CM_RTS) 2";
BA_ "CI_ParId" SG_ 2632777610 PGN_PktMsgTPCM_RTS2 "ESMD_03860";
BA_ "SPN" SG_ 2632777610 PGN_PktMsgTPCM_RTS2 2566;
BA_ "GenSigAutoGenSnd" SG_ 2632777610 TotMsgSizeBAM 0;
BA_ "GenSigAutoGenDsp" SG_ 2632777610 TotMsgSizeBAM 0;
BA_ "CI_RepetitionComplemented" SG_ 2632777610 TotMsgSizeBAM 2;
BA_ "CI_FullName" SG_ 2632777610 TotMsgSizeBAM "_";
BA_ "CI_ParId" SG_ 2632777610 TotMsgSizeBAM "ESMD_03432";
BA_ "SPN" SG_ 2632777610 TotMsgSizeBAM 2567;
BA_ "GenSigAutoGenSnd" SG_ 2632777610 TotMsgSizeEoMA 0;
BA_ "GenSigAutoGenDsp" SG_ 2632777610 TotMsgSizeEoMA 0;
BA_ "CI_RepetitionComplemented" SG_ 2632777610 TotMsgSizeEoMA 2;
BA_ "CI_FullName" SG_ 2632777610 TotMsgSizeEoMA "_";
BA_ "CI_ParId" SG_ 2632777610 TotMsgSizeEoMA "ESMD_03433";
BA_ "SPN" SG_ 2632777610 TotMsgSizeEoMA 2564;
BA_ "GenSigAutoGenSnd" SG_ 2632777610 TotMsgSizeTPCM_RTS 0;
BA_ "GenSigAutoGenDsp" SG_ 2632777610 TotMsgSizeTPCM_RTS 0;
BA_ "CI_RepetitionComplemented" SG_ 2632777610 TotMsgSizeTPCM_RTS 2;
BA_ "CI_FullName" SG_ 2632777610 TotMsgSizeTPCM_RTS "Total Message Size (TP.CM_RTS)";
BA_ "CI_ParId" SG_ 2632777610 TotMsgSizeTPCM_RTS "ESMD_03431";
BA_ "SPN" SG_ 2632777610 TotMsgSizeTPCM_RTS 2557;
BA_ "GenSigAutoGenSnd" SG_ 2632777610 TotNumPktBAM 0;
BA_ "GenSigAutoGenDsp" SG_ 2632777610 TotNumPktBAM 0;
BA_ "CI_RepetitionComplemented" SG_ 2632777610 TotNumPktBAM 2;
BA_ "CI_FullName" SG_ 2632777610 TotNumPktBAM "_";
BA_ "CI_ParId" SG_ 2632777610 TotNumPktBAM "ESMD_03435";
BA_ "SPN" SG_ 2632777610 TotNumPktBAM 2568;
BA_ "GenSigAutoGenSnd" SG_ 2632777610 TotNumPktEoMA 0;
BA_ "GenSigAutoGenDsp" SG_ 2632777610 TotNumPktEoMA 0;
BA_ "CI_RepetitionComplemented" SG_ 2632777610 TotNumPktEoMA 2;
BA_ "CI_FullName" SG_ 2632777610 TotNumPktEoMA "_";
BA_ "CI_ParId" SG_ 2632777610 TotNumPktEoMA "ESMD_03436";
BA_ "SPN" SG_ 2632777610 TotNumPktEoMA 2565;
BA_ "GenSigAutoGenSnd" SG_ 2632777610 TotNumPktTPCM_RTS 0;
BA_ "GenSigAutoGenDsp" SG_ 2632777610 TotNumPktTPCM_RTS 0;
BA_ "CI_RepetitionComplemented" SG_ 2632777610 TotNumPktTPCM_RTS 2;
BA_ "CI_FullName" SG_ 2632777610 TotNumPktTPCM_RTS "Total Number of Packets (TP.CM_RTS)";
BA_ "CI_ParId" SG_ 2632777610 TotNumPktTPCM_RTS "ESMD_03434";
BA_ "SPN" SG_ 2632777610 TotNumPktTPCM_RTS 2558;
BA_ "CI_FullName" SG_ 2566834825 AmbrWarnLmp "Amber Warning Lamp";
BA_ "CI_ParId" SG_ 2566834825 AmbrWarnLmp "ESMD_00554";
BA_ "CI_SLOT_Name" SG_ 2566834825 AmbrWarnLmp "SAEbs02";
BA_ "SPN" SG_ 2566834825 AmbrWarnLmp 624;
BA_ "CI_FullName" SG_ 2566834825 DTC_01 "Diagnostic Trouble Code 01";
BA_ "CI_ParId" SG_ 2566834825 DTC_01 "ESMD_01142";
BA_ "CI_FullName" SG_ 2566834825 DTC_02 "Diagnostic Trouble Code 02";
BA_ "CI_ParId" SG_ 2566834825 DTC_02 "ESMD_01143";
BA_ "CI_FullName" SG_ 2566834825 DTC_03 "Diagnostic Trouble Code 03";
BA_ "CI_ParId" SG_ 2566834825 DTC_03 "ESMD_01144";
BA_ "CI_FullName" SG_ 2566834825 DTC_04 "Diagnostic Trouble Code 04";
BA_ "CI_ParId" SG_ 2566834825 DTC_04 "ESMD_01145";
BA_ "CI_FullName" SG_ 2566834825 FlashAmbrWarnLmpAWL "Flash Amber Warning Lamp (AWL)";
BA_ "CI_ParId" SG_ 2566834825 FlashAmbrWarnLmpAWL "ESMD_01963";
BA_ "CI_SLOT_Name" SG_ 2566834825 FlashAmbrWarnLmpAWL "SAEbs02";
BA_ "SPN" SG_ 2566834825 FlashAmbrWarnLmpAWL 3040;
BA_ "CI_FullName" SG_ 2566834825 FlashMIL "Flash Malfunction Indicator Lamp";
BA_ "CI_ParId" SG_ 2566834825 FlashMIL "ESMD_01964";
BA_ "CI_SLOT_Name" SG_ 2566834825 FlashMIL "SAEbs02";
BA_ "SPN" SG_ 2566834825 FlashMIL 3038;
BA_ "CI_FullName" SG_ 2566834825 FlashProtLmp "Flash Protect Lamp";
BA_ "CI_ParId" SG_ 2566834825 FlashProtLmp "ESMD_01965";
BA_ "CI_SLOT_Name" SG_ 2566834825 FlashProtLmp "SAEbs02";
BA_ "SPN" SG_ 2566834825 FlashProtLmp 3041;
BA_ "CI_FullName" SG_ 2566834825 FlashRedStopLmpRSL "Flash Red Stop Lamp (RSL)";
BA_ "CI_ParId" SG_ 2566834825 FlashRedStopLmpRSL "ESMD_01966";
BA_ "CI_SLOT_Name" SG_ 2566834825 FlashRedStopLmpRSL "SAEbs02";
BA_ "SPN" SG_ 2566834825 FlashRedStopLmpRSL 3039;
BA_ "CI_FullName" SG_ 2566834825 MIL "Malfunction Indicator Lamp";
BA_ "CI_ParId" SG_ 2566834825 MIL "ESMD_02672";
BA_ "CI_SLOT_Name" SG_ 2566834825 MIL "SAEbs02";
BA_ "SPN" SG_ 2566834825 MIL 1213;
BA_ "CI_FullName" SG_ 2566834825 ProtLmp "Protect Lamp";
BA_ "CI_ParId" SG_ 2566834825 ProtLmp "ESMD_02904";
BA_ "CI_SLOT_Name" SG_ 2566834825 ProtLmp "SAEbs02";
BA_ "SPN" SG_ 2566834825 ProtLmp 987;
BA_ "CI_FullName" SG_ 2566834825 RedStopLmp "Red Stop Lamp";
BA_ "CI_ParId" SG_ 2566834825 RedStopLmp "ESMD_02945";
BA_ "CI_SLOT_Name" SG_ 2566834825 RedStopLmp "SAEbs02";
BA_ "SPN" SG_ 2566834825 RedStopLmp 623;
BA_ "CI_FullName" SG_ 2566834826 AmbrWarnLmp "Amber Warning Lamp";
BA_ "CI_ParId" SG_ 2566834826 AmbrWarnLmp "ESMD_00554";
BA_ "CI_SLOT_Name" SG_ 2566834826 AmbrWarnLmp "SAEbs02";
BA_ "SPN" SG_ 2566834826 AmbrWarnLmp 624;
BA_ "CI_FullName" SG_ 2566834826 DTC_01 "Diagnostic Trouble Code 01";
BA_ "CI_ParId" SG_ 2566834826 DTC_01 "ESMD_01142";
BA_ "CI_FullName" SG_ 2566834826 DTC_02 "Diagnostic Trouble Code 02";
BA_ "CI_ParId" SG_ 2566834826 DTC_02 "ESMD_01143";
BA_ "CI_FullName" SG_ 2566834826 DTC_03 "Diagnostic Trouble Code 03";
BA_ "CI_ParId" SG_ 2566834826 DTC_03 "ESMD_01144";
BA_ "CI_FullName" SG_ 2566834826 DTC_04 "Diagnostic Trouble Code 04";
BA_ "CI_ParId" SG_ 2566834826 DTC_04 "ESMD_01145";
BA_ "CI_FullName" SG_ 2566834826 FlashAmbrWarnLmpAWL "Flash Amber Warning Lamp (AWL)";
BA_ "CI_ParId" SG_ 2566834826 FlashAmbrWarnLmpAWL "ESMD_01963";
BA_ "CI_SLOT_Name" SG_ 2566834826 FlashAmbrWarnLmpAWL "SAEbs02";
BA_ "SPN" SG_ 2566834826 FlashAmbrWarnLmpAWL 3040;
BA_ "CI_FullName" SG_ 2566834826 FlashMIL "Flash Malfunction Indicator Lamp";
BA_ "CI_ParId" SG_ 2566834826 FlashMIL "ESMD_01964";
BA_ "CI_SLOT_Name" SG_ 2566834826 FlashMIL "SAEbs02";
BA_ "SPN" SG_ 2566834826 FlashMIL 3038;
BA_ "CI_FullName" SG_ 2566834826 FlashProtLmp "Flash Protect Lamp";
BA_ "CI_ParId" SG_ 2566834826 FlashProtLmp "ESMD_01965";
BA_ "CI_SLOT_Name" SG_ 2566834826 FlashProtLmp "SAEbs02";
BA_ "SPN" SG_ 2566834826 FlashProtLmp 3041;
BA_ "CI_FullName" SG_ 2566834826 FlashRedStopLmpRSL "Flash Red Stop Lamp (RSL)";
BA_ "CI_ParId" SG_ 2566834826 FlashRedStopLmpRSL "ESMD_01966";
BA_ "CI_SLOT_Name" SG_ 2566834826 FlashRedStopLmpRSL "SAEbs02";
BA_ "SPN" SG_ 2566834826 FlashRedStopLmpRSL 3039;
BA_ "CI_FullName" SG_ 2566834826 MIL "Malfunction Indicator Lamp";
BA_ "CI_ParId" SG_ 2566834826 MIL "ESMD_02672";
BA_ "CI_SLOT_Name" SG_ 2566834826 MIL "SAEbs02";
BA_ "SPN" SG_ 2566834826 MIL 1213;
BA_ "CI_FullName" SG_ 2566834826 ProtLmp "Protect Lamp";
BA_ "CI_ParId" SG_ 2566834826 ProtLmp "ESMD_02904";
BA_ "CI_SLOT_Name" SG_ 2566834826 ProtLmp "SAEbs02";
BA_ "SPN" SG_ 2566834826 ProtLmp 987;
BA_ "CI_FullName" SG_ 2566834826 RedStopLmp "Red Stop Lamp";
BA_ "CI_ParId" SG_ 2566834826 RedStopLmp "ESMD_02945";
BA_ "CI_SLOT_Name" SG_ 2566834826 RedStopLmp "SAEbs02";
BA_ "SPN" SG_ 2566834826 RedStopLmp 623;
BA_ "CI_FullName" SG_ 2566834831 DTC_01 "Diagnostic Trouble Code 01";
BA_ "CI_ParId" SG_ 2566834831 DTC_01 "ESMD_01142";
BA_ "CI_FullName" SG_ 2566834831 ProtLmp "Protect Lamp";
BA_ "CI_ParId" SG_ 2566834831 ProtLmp "ESMD_02904";
BA_ "CI_SLOT_Name" SG_ 2566834831 ProtLmp "SAEbs02";
BA_ "SPN" SG_ 2566834831 ProtLmp 987;
BA_ "CI_FullName" SG_ 2566834831 RedStopLmp "Red Stop Lamp";
BA_ "CI_ParId" SG_ 2566834831 RedStopLmp "ESMD_02945";
BA_ "CI_SLOT_Name" SG_ 2566834831 RedStopLmp "SAEbs02";
BA_ "SPN" SG_ 2566834831 RedStopLmp 623;
BA_ "CI_FullName" SG_ 2566834831 AmbrWarnLmp "Amber Warning Lamp";
BA_ "CI_ParId" SG_ 2566834831 AmbrWarnLmp "ESMD_00554";
BA_ "CI_SLOT_Name" SG_ 2566834831 AmbrWarnLmp "SAEbs02";
BA_ "SPN" SG_ 2566834831 AmbrWarnLmp 624;
BA_ "CI_FullName" SG_ 2566834831 MIL "Malfunction Indicator Lamp";
BA_ "CI_ParId" SG_ 2566834831 MIL "ESMD_02672";
BA_ "CI_SLOT_Name" SG_ 2566834831 MIL "SAEbs02";
BA_ "SPN" SG_ 2566834831 MIL 1213;
BA_ "CI_FullName" SG_ 2566834831 FlashAmbrWarnLmpAWL "Flash Amber Warning Lamp (AWL)";
BA_ "CI_ParId" SG_ 2566834831 FlashAmbrWarnLmpAWL "ESMD_01963";
BA_ "CI_SLOT_Name" SG_ 2566834831 FlashAmbrWarnLmpAWL "SAEbs02";
BA_ "SPN" SG_ 2566834831 FlashAmbrWarnLmpAWL 3040;
BA_ "CI_FullName" SG_ 2566834831 FlashMIL "Flash Malfunction Indicator Lamp";
BA_ "CI_ParId" SG_ 2566834831 FlashMIL "ESMD_01964";
BA_ "CI_SLOT_Name" SG_ 2566834831 FlashMIL "SAEbs02";
BA_ "SPN" SG_ 2566834831 FlashMIL 3038;
BA_ "CI_FullName" SG_ 2566834831 FlashProtLmp "Flash Protect Lamp";
BA_ "CI_ParId" SG_ 2566834831 FlashProtLmp "ESMD_01965";
BA_ "CI_SLOT_Name" SG_ 2566834831 FlashProtLmp "SAEbs02";
BA_ "SPN" SG_ 2566834831 FlashProtLmp 3041;
BA_ "CI_FullName" SG_ 2566834831 FlashRedStopLmpRSL "Flash Red Stop Lamp (RSL)";
BA_ "CI_ParId" SG_ 2566834831 FlashRedStopLmpRSL "ESMD_01966";
BA_ "CI_SLOT_Name" SG_ 2566834831 FlashRedStopLmpRSL "SAEbs02";
BA_ "SPN" SG_ 2566834831 FlashRedStopLmpRSL 3039;
BA_ "CI_FullName" SG_ 2632712075 PktDataTPDT "Packetized Data (TP.DT)";
BA_ "CI_ParId" SG_ 2632712075 PktDataTPDT "ESMD_16027";
BA_ "SPN" SG_ 2632712075 PktDataTPDT 2573;
BA_ "CI_FullName" SG_ 2632712075 SN_TPDT "Sequence Number (TP.DT)";
BA_ "CI_ParId" SG_ 2632712075 SN_TPDT "ESMD_03114";
BA_ "SPN" SG_ 2632712075 SN_TPDT 2572;
BA_ "GenSigAutoGenSnd" SG_ 2632777611 CByteTPCM 0;
BA_ "GenSigAutoGenDsp" SG_ 2632777611 CByteTPCM 0;
BA_ "CI_RepetitionComplemented" SG_ 2632777611 CByteTPCM 2;
BA_ "CI_FullName" SG_ 2632777611 CByteTPCM "Control Byte (TP.CM)";
BA_ "CI_ParId" SG_ 2632777611 CByteTPCM "ESMD_00941";
BA_ "SPN" SG_ 2632777611 CByteTPCM 2556;
BA_ "GenSigAutoGenSnd" SG_ 2632777611 ConnAbrtReason 0;
BA_ "GenSigAutoGenDsp" SG_ 2632777611 ConnAbrtReason 0;
BA_ "CI_RepetitionComplemented" SG_ 2632777611 ConnAbrtReason 2;
BA_ "CI_FullName" SG_ 2632777611 ConnAbrtReason "Connection Abort Reason";
BA_ "CI_ParId" SG_ 2632777611 ConnAbrtReason "ESMD_00939";
BA_ "SPN" SG_ 2632777611 ConnAbrtReason 2570;
BA_ "GenSigAutoGenSnd" SG_ 2632777611 MaxNumPktTPCM_RTS 0;
BA_ "GenSigAutoGenDsp" SG_ 2632777611 MaxNumPktTPCM_RTS 0;
BA_ "CI_RepetitionComplemented" SG_ 2632777611 MaxNumPktTPCM_RTS 2;
BA_ "CI_FullName" SG_ 2632777611 MaxNumPktTPCM_RTS "Maximum Number of Packets (TP.CM_RTS)";
BA_ "CI_ParId" SG_ 2632777611 MaxNumPktTPCM_RTS "ESMD_02684";
BA_ "SPN" SG_ 2632777611 MaxNumPktTPCM_RTS 2559;
BA_ "GenSigAutoGenSnd" SG_ 2632777611 NumPktSentTPCM_CTS 0;
BA_ "GenSigAutoGenDsp" SG_ 2632777611 NumPktSentTPCM_CTS 0;
BA_ "CI_RepetitionComplemented" SG_ 2632777611 NumPktSentTPCM_CTS 2;
BA_ "CI_FullName" SG_ 2632777611 NumPktSentTPCM_CTS "Number of Packets that can be sent (TP.CM_CTS)";
BA_ "CI_ParId" SG_ 2632777611 NumPktSentTPCM_CTS "ESMD_02790";
BA_ "SPN" SG_ 2632777611 NumPktSentTPCM_CTS 2561;
BA_ "GenSigAutoGenSnd" SG_ 2632777611 NxtPktNumSentTPCM_CTS 0;
BA_ "GenSigAutoGenDsp" SG_ 2632777611 NxtPktNumSentTPCM_CTS 0;
BA_ "CI_RepetitionComplemented" SG_ 2632777611 NxtPktNumSentTPCM_CTS 2;
BA_ "CI_FullName" SG_ 2632777611 NxtPktNumSentTPCM_CTS "Next Packet Number to be sent (TP.CM_CTS)";
BA_ "CI_ParId" SG_ 2632777611 NxtPktNumSentTPCM_CTS "ESMD_02740";
BA_ "SPN" SG_ 2632777611 NxtPktNumSentTPCM_CTS 2562;
BA_ "GenSigAutoGenSnd" SG_ 2632777611 PGN_PktMsgTPCM_BAM 0;
BA_ "GenSigAutoGenDsp" SG_ 2632777611 PGN_PktMsgTPCM_BAM 0;
BA_ "CI_RepetitionComplemented" SG_ 2632777611 PGN_PktMsgTPCM_BAM 2;
BA_ "CI_FullName" SG_ 2632777611 PGN_PktMsgTPCM_BAM "Parameter Group Number of the packeted message (TP.CM_BAM)";
BA_ "CI_ParId" SG_ 2632777611 PGN_PktMsgTPCM_BAM "ESMD_03861";
BA_ "SPN" SG_ 2632777611 PGN_PktMsgTPCM_BAM 2569;
BA_ "GenSigAutoGenSnd" SG_ 2632777611 PGN_PktMsgTPCM_ConnAbort 0;
BA_ "GenSigAutoGenDsp" SG_ 2632777611 PGN_PktMsgTPCM_ConnAbort 0;
BA_ "CI_RepetitionComplemented" SG_ 2632777611 PGN_PktMsgTPCM_ConnAbort 2;
BA_ "CI_FullName" SG_ 2632777611 PGN_PktMsgTPCM_ConnAbort "Parameter Group Number of the packeted message (TP.CM_Conn_Abort)";
BA_ "CI_ParId" SG_ 2632777611 PGN_PktMsgTPCM_ConnAbort "ESMD_03862";
BA_ "SPN" SG_ 2632777611 PGN_PktMsgTPCM_ConnAbort 2571;
BA_ "GenSigAutoGenSnd" SG_ 2632777611 PGN_PktMsgTPCM_CTS 0;
BA_ "GenSigAutoGenDsp" SG_ 2632777611 PGN_PktMsgTPCM_CTS 0;
BA_ "CI_RepetitionComplemented" SG_ 2632777611 PGN_PktMsgTPCM_CTS 2;
BA_ "CI_FullName" SG_ 2632777611 PGN_PktMsgTPCM_CTS "Parameter Group Number of the packeted message (TP.CM_CTS)";
BA_ "CI_ParId" SG_ 2632777611 PGN_PktMsgTPCM_CTS "ESMD_03859";
BA_ "SPN" SG_ 2632777611 PGN_PktMsgTPCM_CTS 2563;
BA_ "GenSigAutoGenSnd" SG_ 2632777611 PGN_PktMsgTPCM_RTS 0;
BA_ "GenSigAutoGenDsp" SG_ 2632777611 PGN_PktMsgTPCM_RTS 0;
BA_ "CI_RepetitionComplemented" SG_ 2632777611 PGN_PktMsgTPCM_RTS 2;
BA_ "CI_FullName" SG_ 2632777611 PGN_PktMsgTPCM_RTS "Parameter Group Number of the packeted message (TP.CM_RTS)";
BA_ "CI_ParId" SG_ 2632777611 PGN_PktMsgTPCM_RTS "ESMD_02869";
BA_ "SPN" SG_ 2632777611 PGN_PktMsgTPCM_RTS 2560;
BA_ "CI_FullName" SG_ 2632777611 PGN_PktMsgTPCM_RTS2 "Parameter Group Number of the packeted message (TP.CM_RTS) 2";
BA_ "CI_ParId" SG_ 2632777611 PGN_PktMsgTPCM_RTS2 "ESMD_03860";
BA_ "SPN" SG_ 2632777611 PGN_PktMsgTPCM_RTS2 2566;
BA_ "GenSigAutoGenSnd" SG_ 2632777611 TotMsgSizeBAM 0;
BA_ "GenSigAutoGenDsp" SG_ 2632777611 TotMsgSizeBAM 0;
BA_ "CI_RepetitionComplemented" SG_ 2632777611 TotMsgSizeBAM 2;
BA_ "CI_FullName" SG_ 2632777611 TotMsgSizeBAM "_";
BA_ "CI_ParId" SG_ 2632777611 TotMsgSizeBAM "ESMD_03432";
BA_ "SPN" SG_ 2632777611 TotMsgSizeBAM 2567;
BA_ "GenSigAutoGenSnd" SG_ 2632777611 TotMsgSizeEoMA 0;
BA_ "GenSigAutoGenDsp" SG_ 2632777611 TotMsgSizeEoMA 0;
BA_ "CI_RepetitionComplemented" SG_ 2632777611 TotMsgSizeEoMA 2;
BA_ "CI_FullName" SG_ 2632777611 TotMsgSizeEoMA "_";
BA_ "CI_ParId" SG_ 2632777611 TotMsgSizeEoMA "ESMD_03433";
BA_ "SPN" SG_ 2632777611 TotMsgSizeEoMA 2564;
BA_ "GenSigAutoGenSnd" SG_ 2632777611 TotMsgSizeTPCM_RTS 0;
BA_ "GenSigAutoGenDsp" SG_ 2632777611 TotMsgSizeTPCM_RTS 0;
BA_ "CI_RepetitionComplemented" SG_ 2632777611 TotMsgSizeTPCM_RTS 2;
BA_ "CI_FullName" SG_ 2632777611 TotMsgSizeTPCM_RTS "Total Message Size (TP.CM_RTS)";
BA_ "CI_ParId" SG_ 2632777611 TotMsgSizeTPCM_RTS "ESMD_03431";
BA_ "SPN" SG_ 2632777611 TotMsgSizeTPCM_RTS 2557;
BA_ "GenSigAutoGenSnd" SG_ 2632777611 TotNumPktBAM 0;
BA_ "GenSigAutoGenDsp" SG_ 2632777611 TotNumPktBAM 0;
BA_ "CI_RepetitionComplemented" SG_ 2632777611 TotNumPktBAM 2;
BA_ "CI_FullName" SG_ 2632777611 TotNumPktBAM "_";
BA_ "CI_ParId" SG_ 2632777611 TotNumPktBAM "ESMD_03435";
BA_ "SPN" SG_ 2632777611 TotNumPktBAM 2568;
BA_ "GenSigAutoGenSnd" SG_ 2632777611 TotNumPktEoMA 0;
BA_ "GenSigAutoGenDsp" SG_ 2632777611 TotNumPktEoMA 0;
BA_ "CI_RepetitionComplemented" SG_ 2632777611 TotNumPktEoMA 2;
BA_ "CI_FullName" SG_ 2632777611 TotNumPktEoMA "_";
BA_ "CI_ParId" SG_ 2632777611 TotNumPktEoMA "ESMD_03436";
BA_ "SPN" SG_ 2632777611 TotNumPktEoMA 2565;
BA_ "GenSigAutoGenSnd" SG_ 2632777611 TotNumPktTPCM_RTS 0;
BA_ "GenSigAutoGenDsp" SG_ 2632777611 TotNumPktTPCM_RTS 0;
BA_ "CI_RepetitionComplemented" SG_ 2632777611 TotNumPktTPCM_RTS 2;
BA_ "CI_FullName" SG_ 2632777611 TotNumPktTPCM_RTS "Total Number of Packets (TP.CM_RTS)";
BA_ "CI_ParId" SG_ 2632777611 TotNumPktTPCM_RTS "ESMD_03434";
BA_ "SPN" SG_ 2632777611 TotNumPktTPCM_RTS 2558;
BA_ "CI_FullName" SG_ 2566838923 Appl_Id_Byte_24 "Software Identification";
BA_ "CI_ParId" SG_ 2566838923 Appl_Id_Byte_24 "ESMD_03139";
BA_ "CI_SLOT_Name" SG_ 2566838923 Appl_Id_Byte_24 "SAEatad0200";
BA_ "SPN" SG_ 2566838923 Appl_Id_Byte_24 234;
BA_ "CI_FullName" SG_ 2566838923 Appl_Id_Byte_25 "Software Identification";
BA_ "CI_ParId" SG_ 2566838923 Appl_Id_Byte_25 "ESMD_03139";
BA_ "CI_SLOT_Name" SG_ 2566838923 Appl_Id_Byte_25 "SAEatad0200";
BA_ "SPN" SG_ 2566838923 Appl_Id_Byte_25 234;
BA_ "CI_FullName" SG_ 2566838923 Appl_Id_Byte_26 "Software Identification";
BA_ "CI_ParId" SG_ 2566838923 Appl_Id_Byte_26 "ESMD_03139";
BA_ "CI_SLOT_Name" SG_ 2566838923 Appl_Id_Byte_26 "SAEatad0200";
BA_ "SPN" SG_ 2566838923 Appl_Id_Byte_26 234;
BA_ "CI_FullName" SG_ 2566838923 Appl_Id_Byte_27 "Software Identification";
BA_ "CI_ParId" SG_ 2566838923 Appl_Id_Byte_27 "ESMD_03139";
BA_ "CI_SLOT_Name" SG_ 2566838923 Appl_Id_Byte_27 "SAEatad0200";
BA_ "SPN" SG_ 2566838923 Appl_Id_Byte_27 234;
BA_ "CI_FullName" SG_ 2566838923 Appl_Id_Byte_28 "Software Identification";
BA_ "CI_ParId" SG_ 2566838923 Appl_Id_Byte_28 "ESMD_03139";
BA_ "CI_SLOT_Name" SG_ 2566838923 Appl_Id_Byte_28 "SAEatad0200";
BA_ "SPN" SG_ 2566838923 Appl_Id_Byte_28 234;
BA_ "CI_FullName" SG_ 2566838923 Appl_Id_Byte_29 "Software Identification";
BA_ "CI_ParId" SG_ 2566838923 Appl_Id_Byte_29 "ESMD_03139";
BA_ "CI_SLOT_Name" SG_ 2566838923 Appl_Id_Byte_29 "SAEatad0200";
BA_ "SPN" SG_ 2566838923 Appl_Id_Byte_29 234;
BA_ "CI_FullName" SG_ 2566838923 Appl_Id_Byte_30 "Software Identification";
BA_ "CI_ParId" SG_ 2566838923 Appl_Id_Byte_30 "ESMD_03139";
BA_ "CI_SLOT_Name" SG_ 2566838923 Appl_Id_Byte_30 "SAEatad0200";
BA_ "SPN" SG_ 2566838923 Appl_Id_Byte_30 234;
BA_ "CI_FullName" SG_ 2566838923 Appl_Id_Byte_31 "Software Identification";
BA_ "CI_ParId" SG_ 2566838923 Appl_Id_Byte_31 "ESMD_03139";
BA_ "CI_SLOT_Name" SG_ 2566838923 Appl_Id_Byte_31 "SAEatad0200";
BA_ "SPN" SG_ 2566838923 Appl_Id_Byte_31 234;
BA_ "CI_FullName" SG_ 2566838923 Appl_Id_Byte_32 "Software Identification";
BA_ "CI_ParId" SG_ 2566838923 Appl_Id_Byte_32 "ESMD_03139";
BA_ "CI_SLOT_Name" SG_ 2566838923 Appl_Id_Byte_32 "SAEatad0200";
BA_ "SPN" SG_ 2566838923 Appl_Id_Byte_32 234;
BA_ "CI_FullName" SG_ 2566838923 Appl_Id_Byte_33 "Software Identification";
BA_ "CI_ParId" SG_ 2566838923 Appl_Id_Byte_33 "ESMD_03139";
BA_ "CI_SLOT_Name" SG_ 2566838923 Appl_Id_Byte_33 "SAEatad0200";
BA_ "SPN" SG_ 2566838923 Appl_Id_Byte_33 234;
BA_ "CI_FullName" SG_ 2566838923 Appl_Id_Byte_34 "Software Identification";
BA_ "CI_ParId" SG_ 2566838923 Appl_Id_Byte_34 "ESMD_03139";
BA_ "CI_SLOT_Name" SG_ 2566838923 Appl_Id_Byte_34 "SAEatad0200";
BA_ "SPN" SG_ 2566838923 Appl_Id_Byte_34 234;
BA_ "CI_FullName" SG_ 2566838923 Appl_Id_Byte_35 "Software Identification";
BA_ "CI_ParId" SG_ 2566838923 Appl_Id_Byte_35 "ESMD_03139";
BA_ "CI_SLOT_Name" SG_ 2566838923 Appl_Id_Byte_35 "SAEatad0200";
BA_ "SPN" SG_ 2566838923 Appl_Id_Byte_35 234;
BA_ "CI_FullName" SG_ 2566838923 Appl_Id_Byte_36 "Software Identification";
BA_ "CI_ParId" SG_ 2566838923 Appl_Id_Byte_36 "ESMD_03139";
BA_ "CI_SLOT_Name" SG_ 2566838923 Appl_Id_Byte_36 "SAEatad0200";
BA_ "SPN" SG_ 2566838923 Appl_Id_Byte_36 234;
BA_ "CI_FullName" SG_ 2566838923 Appl_Id_Byte_37 "Software Identification";
BA_ "CI_ParId" SG_ 2566838923 Appl_Id_Byte_37 "ESMD_03139";
BA_ "CI_SLOT_Name" SG_ 2566838923 Appl_Id_Byte_37 "SAEatad0200";
BA_ "SPN" SG_ 2566838923 Appl_Id_Byte_37 234;
BA_ "CI_FullName" SG_ 2566838923 Appl_Id_Byte_38 "Software Identification";
BA_ "CI_ParId" SG_ 2566838923 Appl_Id_Byte_38 "ESMD_03139";
BA_ "CI_SLOT_Name" SG_ 2566838923 Appl_Id_Byte_38 "SAEatad0200";
BA_ "SPN" SG_ 2566838923 Appl_Id_Byte_38 234;
BA_ "CI_FullName" SG_ 2566838923 Appl_Id_Byte_39 "Software Identification";
BA_ "CI_ParId" SG_ 2566838923 Appl_Id_Byte_39 "ESMD_03139";
BA_ "CI_SLOT_Name" SG_ 2566838923 Appl_Id_Byte_39 "SAEatad0200";
BA_ "SPN" SG_ 2566838923 Appl_Id_Byte_39 234;
BA_ "CI_FullName" SG_ 2566838923 Appl_Id_Enum "Software Identification";
BA_ "CI_ParId" SG_ 2566838923 Appl_Id_Enum "ESMD_03139";
BA_ "CI_SLOT_Name" SG_ 2566838923 Appl_Id_Enum "SAEbs24";
BA_ "SPN" SG_ 2566838923 Appl_Id_Enum 234;
BA_ "CI_FullName" SG_ 2566838923 Bootloader_Id "Software Identification";
BA_ "CI_ParId" SG_ 2566838923 Bootloader_Id "ESMD_03139";
BA_ "CI_SLOT_Name" SG_ 2566838923 Bootloader_Id "SAEatad0200";
BA_ "SPN" SG_ 2566838923 Bootloader_Id 234;
BA_ "CI_FullName" SG_ 2566838923 Bootloader_Id_Byte_01 "Software Identification";
BA_ "CI_ParId" SG_ 2566838923 Bootloader_Id_Byte_01 "ESMD_03139";
BA_ "CI_SLOT_Name" SG_ 2566838923 Bootloader_Id_Byte_01 "SAEatad0200";
BA_ "SPN" SG_ 2566838923 Bootloader_Id_Byte_01 234;
BA_ "CI_FullName" SG_ 2566838923 Bootloader_Id_Byte_02 "Software Identification";
BA_ "CI_ParId" SG_ 2566838923 Bootloader_Id_Byte_02 "ESMD_03139";
BA_ "CI_SLOT_Name" SG_ 2566838923 Bootloader_Id_Byte_02 "SAEatad0200";
BA_ "SPN" SG_ 2566838923 Bootloader_Id_Byte_02 234;
BA_ "CI_FullName" SG_ 2566838923 Bootloader_Id_Byte_03 "Software Identification";
BA_ "CI_ParId" SG_ 2566838923 Bootloader_Id_Byte_03 "ESMD_03139";
BA_ "CI_SLOT_Name" SG_ 2566838923 Bootloader_Id_Byte_03 "SAEatad0200";
BA_ "SPN" SG_ 2566838923 Bootloader_Id_Byte_03 234;
BA_ "CI_FullName" SG_ 2566838923 Bootloader_Id_Byte_04 "Software Identification";
BA_ "CI_ParId" SG_ 2566838923 Bootloader_Id_Byte_04 "ESMD_03139";
BA_ "CI_SLOT_Name" SG_ 2566838923 Bootloader_Id_Byte_04 "SAEatad0200";
BA_ "SPN" SG_ 2566838923 Bootloader_Id_Byte_04 234;
BA_ "CI_FullName" SG_ 2566838923 Bootloader_Id_Byte_05 "Software Identification";
BA_ "CI_ParId" SG_ 2566838923 Bootloader_Id_Byte_05 "ESMD_03139";
BA_ "CI_SLOT_Name" SG_ 2566838923 Bootloader_Id_Byte_05 "SAEatad0200";
BA_ "SPN" SG_ 2566838923 Bootloader_Id_Byte_05 234;
BA_ "CI_FullName" SG_ 2566838923 Bootloader_Id_Byte_06 "Software Identification";
BA_ "CI_ParId" SG_ 2566838923 Bootloader_Id_Byte_06 "ESMD_03139";
BA_ "CI_SLOT_Name" SG_ 2566838923 Bootloader_Id_Byte_06 "SAEatad0200";
BA_ "SPN" SG_ 2566838923 Bootloader_Id_Byte_06 234;
BA_ "CI_FullName" SG_ 2566838923 Bootloader_Id_Byte_07 "Software Identification";
BA_ "CI_ParId" SG_ 2566838923 Bootloader_Id_Byte_07 "ESMD_03139";
BA_ "CI_SLOT_Name" SG_ 2566838923 Bootloader_Id_Byte_07 "SAEatad0200";
BA_ "SPN" SG_ 2566838923 Bootloader_Id_Byte_07 234;
BA_ "CI_FullName" SG_ 2566838923 Bootloader_Id_Byte_08 "Software Identification";
BA_ "CI_ParId" SG_ 2566838923 Bootloader_Id_Byte_08 "ESMD_03139";
BA_ "CI_SLOT_Name" SG_ 2566838923 Bootloader_Id_Byte_08 "SAEatad0200";
BA_ "SPN" SG_ 2566838923 Bootloader_Id_Byte_08 234;
BA_ "CI_FullName" SG_ 2566838923 Bootloader_Id_Byte_09 "Software Identification";
BA_ "CI_ParId" SG_ 2566838923 Bootloader_Id_Byte_09 "ESMD_03139";
BA_ "CI_SLOT_Name" SG_ 2566838923 Bootloader_Id_Byte_09 "SAEatad0200";
BA_ "SPN" SG_ 2566838923 Bootloader_Id_Byte_09 234;
BA_ "CI_FullName" SG_ 2566838923 Bootloader_Id_Byte_10 "Software Identification";
BA_ "CI_ParId" SG_ 2566838923 Bootloader_Id_Byte_10 "ESMD_03139";
BA_ "CI_SLOT_Name" SG_ 2566838923 Bootloader_Id_Byte_10 "SAEatad0200";
BA_ "SPN" SG_ 2566838923 Bootloader_Id_Byte_10 234;
BA_ "CI_FullName" SG_ 2566838923 Bootloader_Id_Byte_11 "Software Identification";
BA_ "CI_ParId" SG_ 2566838923 Bootloader_Id_Byte_11 "ESMD_03139";
BA_ "CI_SLOT_Name" SG_ 2566838923 Bootloader_Id_Byte_11 "SAEatad0200";
BA_ "SPN" SG_ 2566838923 Bootloader_Id_Byte_11 234;
BA_ "CI_FullName" SG_ 2566838923 Bootloader_Id_Byte_12 "Software Identification";
BA_ "CI_ParId" SG_ 2566838923 Bootloader_Id_Byte_12 "ESMD_03139";
BA_ "CI_SLOT_Name" SG_ 2566838923 Bootloader_Id_Byte_12 "SAEatad0200";
BA_ "SPN" SG_ 2566838923 Bootloader_Id_Byte_12 234;
BA_ "CI_FullName" SG_ 2566838923 Bootloader_Id_Byte_13 "Software Identification";
BA_ "CI_ParId" SG_ 2566838923 Bootloader_Id_Byte_13 "ESMD_03139";
BA_ "CI_SLOT_Name" SG_ 2566838923 Bootloader_Id_Byte_13 "SAEatad0200";
BA_ "SPN" SG_ 2566838923 Bootloader_Id_Byte_13 234;
BA_ "CI_FullName" SG_ 2566838923 Bootloader_Id_Byte_14 "Software Identification";
BA_ "CI_ParId" SG_ 2566838923 Bootloader_Id_Byte_14 "ESMD_03139";
BA_ "CI_SLOT_Name" SG_ 2566838923 Bootloader_Id_Byte_14 "SAEatad0200";
BA_ "SPN" SG_ 2566838923 Bootloader_Id_Byte_14 234;
BA_ "CI_FullName" SG_ 2566838923 Bootloader_Id_Byte_15 "Software Identification";
BA_ "CI_ParId" SG_ 2566838923 Bootloader_Id_Byte_15 "ESMD_03139";
BA_ "CI_SLOT_Name" SG_ 2566838923 Bootloader_Id_Byte_15 "SAEatad0200";
BA_ "SPN" SG_ 2566838923 Bootloader_Id_Byte_15 234;
BA_ "CI_FullName" SG_ 2566838923 Bootloader_Id_Byte_16 "Software Identification";
BA_ "CI_ParId" SG_ 2566838923 Bootloader_Id_Byte_16 "ESMD_03139";
BA_ "CI_SLOT_Name" SG_ 2566838923 Bootloader_Id_Byte_16 "SAEatad0200";
BA_ "SPN" SG_ 2566838923 Bootloader_Id_Byte_16 234;
BA_ "CI_FullName" SG_ 2566838923 Bootloader_Id_Byte_17 "Software Identification";
BA_ "CI_ParId" SG_ 2566838923 Bootloader_Id_Byte_17 "ESMD_03139";
BA_ "CI_SLOT_Name" SG_ 2566838923 Bootloader_Id_Byte_17 "SAEatad0200";
BA_ "SPN" SG_ 2566838923 Bootloader_Id_Byte_17 234;
BA_ "CI_FullName" SG_ 2566838923 Bootloader_Id_Byte_18 "Software Identification";
BA_ "CI_ParId" SG_ 2566838923 Bootloader_Id_Byte_18 "ESMD_03139";
BA_ "CI_SLOT_Name" SG_ 2566838923 Bootloader_Id_Byte_18 "SAEatad0200";
BA_ "SPN" SG_ 2566838923 Bootloader_Id_Byte_18 234;
BA_ "CI_FullName" SG_ 2566838923 Bootloader_Id_Byte_19 "Software Identification";
BA_ "CI_ParId" SG_ 2566838923 Bootloader_Id_Byte_19 "ESMD_03139";
BA_ "CI_SLOT_Name" SG_ 2566838923 Bootloader_Id_Byte_19 "SAEatad0200";
BA_ "SPN" SG_ 2566838923 Bootloader_Id_Byte_19 234;
BA_ "CI_FullName" SG_ 2566838923 Bootloader_Id_Byte_20 "Software Identification";
BA_ "CI_ParId" SG_ 2566838923 Bootloader_Id_Byte_20 "ESMD_03139";
BA_ "CI_SLOT_Name" SG_ 2566838923 Bootloader_Id_Byte_20 "SAEatad0200";
BA_ "SPN" SG_ 2566838923 Bootloader_Id_Byte_20 234;
BA_ "CI_FullName" SG_ 2566838923 Bootloader_Id_Byte_21 "Software Identification";
BA_ "CI_ParId" SG_ 2566838923 Bootloader_Id_Byte_21 "ESMD_03139";
BA_ "CI_SLOT_Name" SG_ 2566838923 Bootloader_Id_Byte_21 "SAEatad0200";
BA_ "SPN" SG_ 2566838923 Bootloader_Id_Byte_21 234;
BA_ "CI_FullName" SG_ 2566838923 Bootloader_Id_Byte_22 "Software Identification";
BA_ "CI_ParId" SG_ 2566838923 Bootloader_Id_Byte_22 "ESMD_03139";
BA_ "CI_SLOT_Name" SG_ 2566838923 Bootloader_Id_Byte_22 "SAEatad0200";
BA_ "SPN" SG_ 2566838923 Bootloader_Id_Byte_22 234;
BA_ "CI_FullName" SG_ 2566838923 Bootloader_Id_Byte_23 "Software Identification";
BA_ "CI_ParId" SG_ 2566838923 Bootloader_Id_Byte_23 "ESMD_03139";
BA_ "CI_SLOT_Name" SG_ 2566838923 Bootloader_Id_Byte_23 "SAEatad0200";
BA_ "SPN" SG_ 2566838923 Bootloader_Id_Byte_23 234;
BA_ "CI_FullName" SG_ 2566838923 Bootloader_Id_Byte_24 "Software Identification";
BA_ "CI_ParId" SG_ 2566838923 Bootloader_Id_Byte_24 "ESMD_03139";
BA_ "CI_SLOT_Name" SG_ 2566838923 Bootloader_Id_Byte_24 "SAEatad0200";
BA_ "SPN" SG_ 2566838923 Bootloader_Id_Byte_24 234;
BA_ "CI_FullName" SG_ 2566838923 Bootloader_Id_Byte_25 "Software Identification";
BA_ "CI_ParId" SG_ 2566838923 Bootloader_Id_Byte_25 "ESMD_03139";
BA_ "CI_SLOT_Name" SG_ 2566838923 Bootloader_Id_Byte_25 "SAEatad0200";
BA_ "SPN" SG_ 2566838923 Bootloader_Id_Byte_25 234;
BA_ "CI_FullName" SG_ 2566838923 Bootloader_Id_Byte_26 "Software Identification";
BA_ "CI_ParId" SG_ 2566838923 Bootloader_Id_Byte_26 "ESMD_03139";
BA_ "CI_SLOT_Name" SG_ 2566838923 Bootloader_Id_Byte_26 "SAEatad0200";
BA_ "SPN" SG_ 2566838923 Bootloader_Id_Byte_26 234;
BA_ "CI_FullName" SG_ 2566838923 Bootloader_Id_Byte_27 "Software Identification";
BA_ "CI_ParId" SG_ 2566838923 Bootloader_Id_Byte_27 "ESMD_03139";
BA_ "CI_SLOT_Name" SG_ 2566838923 Bootloader_Id_Byte_27 "SAEatad0200";
BA_ "SPN" SG_ 2566838923 Bootloader_Id_Byte_27 234;
BA_ "CI_FullName" SG_ 2566838923 Bootloader_Id_Byte_28 "Software Identification";
BA_ "CI_ParId" SG_ 2566838923 Bootloader_Id_Byte_28 "ESMD_03139";
BA_ "CI_SLOT_Name" SG_ 2566838923 Bootloader_Id_Byte_28 "SAEatad0200";
BA_ "SPN" SG_ 2566838923 Bootloader_Id_Byte_28 234;
BA_ "CI_FullName" SG_ 2566838923 Bootloader_Id_Byte_29 "Software Identification";
BA_ "CI_ParId" SG_ 2566838923 Bootloader_Id_Byte_29 "ESMD_03139";
BA_ "CI_SLOT_Name" SG_ 2566838923 Bootloader_Id_Byte_29 "SAEatad0200";
BA_ "SPN" SG_ 2566838923 Bootloader_Id_Byte_29 234;
BA_ "CI_FullName" SG_ 2566838923 Bootloader_Id_Byte_30 "Software Identification";
BA_ "CI_ParId" SG_ 2566838923 Bootloader_Id_Byte_30 "ESMD_03139";
BA_ "CI_SLOT_Name" SG_ 2566838923 Bootloader_Id_Byte_30 "SAEatad0200";
BA_ "SPN" SG_ 2566838923 Bootloader_Id_Byte_30 234;
BA_ "CI_FullName" SG_ 2566838923 Bootloader_Id_Byte_31 "Software Identification";
BA_ "CI_ParId" SG_ 2566838923 Bootloader_Id_Byte_31 "ESMD_03139";
BA_ "CI_SLOT_Name" SG_ 2566838923 Bootloader_Id_Byte_31 "SAEatad0200";
BA_ "SPN" SG_ 2566838923 Bootloader_Id_Byte_31 234;
BA_ "CI_FullName" SG_ 2566838923 Bootloader_Id_Byte_32 "Software Identification";
BA_ "CI_ParId" SG_ 2566838923 Bootloader_Id_Byte_32 "ESMD_03139";
BA_ "CI_SLOT_Name" SG_ 2566838923 Bootloader_Id_Byte_32 "SAEatad0200";
BA_ "SPN" SG_ 2566838923 Bootloader_Id_Byte_32 234;
BA_ "CI_FullName" SG_ 2566838923 Bootloader_Id_Byte_33 "Software Identification";
BA_ "CI_ParId" SG_ 2566838923 Bootloader_Id_Byte_33 "ESMD_03139";
BA_ "CI_SLOT_Name" SG_ 2566838923 Bootloader_Id_Byte_33 "SAEatad0200";
BA_ "SPN" SG_ 2566838923 Bootloader_Id_Byte_33 234;
BA_ "CI_FullName" SG_ 2566838923 Bootloader_Id_Byte_34 "Software Identification";
BA_ "CI_ParId" SG_ 2566838923 Bootloader_Id_Byte_34 "ESMD_03139";
BA_ "CI_SLOT_Name" SG_ 2566838923 Bootloader_Id_Byte_34 "SAEatad0200";
BA_ "SPN" SG_ 2566838923 Bootloader_Id_Byte_34 234;
BA_ "CI_FullName" SG_ 2566838923 Bootloader_Id_Byte_35 "Software Identification";
BA_ "CI_ParId" SG_ 2566838923 Bootloader_Id_Byte_35 "ESMD_03139";
BA_ "CI_SLOT_Name" SG_ 2566838923 Bootloader_Id_Byte_35 "SAEatad0200";
BA_ "SPN" SG_ 2566838923 Bootloader_Id_Byte_35 234;
BA_ "CI_FullName" SG_ 2566838923 Bootloader_Id_Byte_36 "Software Identification";
BA_ "CI_ParId" SG_ 2566838923 Bootloader_Id_Byte_36 "ESMD_03139";
BA_ "CI_SLOT_Name" SG_ 2566838923 Bootloader_Id_Byte_36 "SAEatad0200";
BA_ "SPN" SG_ 2566838923 Bootloader_Id_Byte_36 234;
BA_ "CI_FullName" SG_ 2566838923 Bootloader_Id_Byte_37 "Software Identification";
BA_ "CI_ParId" SG_ 2566838923 Bootloader_Id_Byte_37 "ESMD_03139";
BA_ "CI_SLOT_Name" SG_ 2566838923 Bootloader_Id_Byte_37 "SAEatad0200";
BA_ "SPN" SG_ 2566838923 Bootloader_Id_Byte_37 234;
BA_ "CI_FullName" SG_ 2566838923 Bootloader_Id_Byte_38 "Software Identification";
BA_ "CI_ParId" SG_ 2566838923 Bootloader_Id_Byte_38 "ESMD_03139";
BA_ "CI_SLOT_Name" SG_ 2566838923 Bootloader_Id_Byte_38 "SAEatad0200";
BA_ "SPN" SG_ 2566838923 Bootloader_Id_Byte_38 234;
BA_ "CI_FullName" SG_ 2566838923 Bootloader_Id_Byte_39 "Software Identification";
BA_ "CI_ParId" SG_ 2566838923 Bootloader_Id_Byte_39 "ESMD_03139";
BA_ "CI_SLOT_Name" SG_ 2566838923 Bootloader_Id_Byte_39 "SAEatad0200";
BA_ "SPN" SG_ 2566838923 Bootloader_Id_Byte_39 234;
BA_ "CI_FullName" SG_ 2566838923 Bootloader_Id_Enum "Software Identification";
BA_ "CI_ParId" SG_ 2566838923 Bootloader_Id_Enum "ESMD_03139";
BA_ "CI_SLOT_Name" SG_ 2566838923 Bootloader_Id_Enum "SAEbs24";
BA_ "SPN" SG_ 2566838923 Bootloader_Id_Enum 234;
BA_ "CI_FullName" SG_ 2566838923 EndStrng_00 "Software Identification";
BA_ "CI_ParId" SG_ 2566838923 EndStrng_00 "ESMD_21930";
BA_ "CI_SLOT_Name" SG_ 2566838923 EndStrng_00 "SAEatad0200";
BA_ "GenSigStartValue" SG_ 2566838923 EndStrng_00 42;
BA_ "SigType" SG_ 2566838923 EndStrng_00 8;
BA_ "CI_FullName" SG_ 2566838923 EndStrng_01 "Software Identification";
BA_ "CI_ParId" SG_ 2566838923 EndStrng_01 "ESMD_21931";
BA_ "CI_SLOT_Name" SG_ 2566838923 EndStrng_01 "SAEatad0200";
BA_ "GenSigStartValue" SG_ 2566838923 EndStrng_01 42;
BA_ "SigType" SG_ 2566838923 EndStrng_01 8;
BA_ "GenSigAutoGenSnd" SG_ 2566838923 NumSW_IdField 0;
BA_ "GenSigAutoGenDsp" SG_ 2566838923 NumSW_IdField 0;
BA_ "CI_RepetitionComplemented" SG_ 2566838923 NumSW_IdField 2;
BA_ "CI_FullName" SG_ 2566838923 NumSW_IdField "Number of Software Identification Fields";
BA_ "CI_ParId" SG_ 2566838923 NumSW_IdField "ESMD_02746";
BA_ "CI_SLOT_Name" SG_ 2566838923 NumSW_IdField "SAEst01";
BA_ "SPN" SG_ 2566838923 NumSW_IdField 965;
BA_ "SigType" SG_ 2566838923 NumSW_IdField 1;
BA_ "CI_FullName" SG_ 2566838923 Appl_Id "Software Identification";
BA_ "CI_ParId" SG_ 2566838923 Appl_Id "ESMD_03139";
BA_ "CI_SLOT_Name" SG_ 2566838923 Appl_Id "SAEatad0200";
BA_ "SPN" SG_ 2566838923 Appl_Id 234;
BA_ "CI_FullName" SG_ 2566838923 Appl_Id_Byte_01 "Software Identification";
BA_ "CI_ParId" SG_ 2566838923 Appl_Id_Byte_01 "ESMD_03139";
BA_ "CI_SLOT_Name" SG_ 2566838923 Appl_Id_Byte_01 "SAEatad0200";
BA_ "SPN" SG_ 2566838923 Appl_Id_Byte_01 234;
BA_ "CI_FullName" SG_ 2566838923 Appl_Id_Byte_02 "Software Identification";
BA_ "CI_ParId" SG_ 2566838923 Appl_Id_Byte_02 "ESMD_03139";
BA_ "CI_SLOT_Name" SG_ 2566838923 Appl_Id_Byte_02 "SAEatad0200";
BA_ "SPN" SG_ 2566838923 Appl_Id_Byte_02 234;
BA_ "CI_FullName" SG_ 2566838923 Appl_Id_Byte_03 "Software Identification";
BA_ "CI_ParId" SG_ 2566838923 Appl_Id_Byte_03 "ESMD_03139";
BA_ "CI_SLOT_Name" SG_ 2566838923 Appl_Id_Byte_03 "SAEatad0200";
BA_ "SPN" SG_ 2566838923 Appl_Id_Byte_03 234;
BA_ "CI_FullName" SG_ 2566838923 Appl_Id_Byte_04 "Software Identification";
BA_ "CI_ParId" SG_ 2566838923 Appl_Id_Byte_04 "ESMD_03139";
BA_ "CI_SLOT_Name" SG_ 2566838923 Appl_Id_Byte_04 "SAEatad0200";
BA_ "SPN" SG_ 2566838923 Appl_Id_Byte_04 234;
BA_ "CI_FullName" SG_ 2566838923 Appl_Id_Byte_05 "Software Identification";
BA_ "CI_ParId" SG_ 2566838923 Appl_Id_Byte_05 "ESMD_03139";
BA_ "CI_SLOT_Name" SG_ 2566838923 Appl_Id_Byte_05 "SAEatad0200";
BA_ "SPN" SG_ 2566838923 Appl_Id_Byte_05 234;
BA_ "CI_FullName" SG_ 2566838923 Appl_Id_Byte_06 "Software Identification";
BA_ "CI_ParId" SG_ 2566838923 Appl_Id_Byte_06 "ESMD_03139";
BA_ "CI_SLOT_Name" SG_ 2566838923 Appl_Id_Byte_06 "SAEatad0200";
BA_ "SPN" SG_ 2566838923 Appl_Id_Byte_06 234;
BA_ "CI_FullName" SG_ 2566838923 Appl_Id_Byte_07 "Software Identification";
BA_ "CI_ParId" SG_ 2566838923 Appl_Id_Byte_07 "ESMD_03139";
BA_ "CI_SLOT_Name" SG_ 2566838923 Appl_Id_Byte_07 "SAEatad0200";
BA_ "SPN" SG_ 2566838923 Appl_Id_Byte_07 234;
BA_ "CI_FullName" SG_ 2566838923 Appl_Id_Byte_08 "Software Identification";
BA_ "CI_ParId" SG_ 2566838923 Appl_Id_Byte_08 "ESMD_03139";
BA_ "CI_SLOT_Name" SG_ 2566838923 Appl_Id_Byte_08 "SAEatad0200";
BA_ "SPN" SG_ 2566838923 Appl_Id_Byte_08 234;
BA_ "CI_FullName" SG_ 2566838923 Appl_Id_Byte_09 "Software Identification";
BA_ "CI_ParId" SG_ 2566838923 Appl_Id_Byte_09 "ESMD_03139";
BA_ "CI_SLOT_Name" SG_ 2566838923 Appl_Id_Byte_09 "SAEatad0200";
BA_ "SPN" SG_ 2566838923 Appl_Id_Byte_09 234;
BA_ "CI_FullName" SG_ 2566838923 Appl_Id_Byte_10 "Software Identification";
BA_ "CI_ParId" SG_ 2566838923 Appl_Id_Byte_10 "ESMD_03139";
BA_ "CI_SLOT_Name" SG_ 2566838923 Appl_Id_Byte_10 "SAEatad0200";
BA_ "SPN" SG_ 2566838923 Appl_Id_Byte_10 234;
BA_ "CI_FullName" SG_ 2566838923 Appl_Id_Byte_11 "Software Identification";
BA_ "CI_ParId" SG_ 2566838923 Appl_Id_Byte_11 "ESMD_03139";
BA_ "CI_SLOT_Name" SG_ 2566838923 Appl_Id_Byte_11 "SAEatad0200";
BA_ "SPN" SG_ 2566838923 Appl_Id_Byte_11 234;
BA_ "CI_FullName" SG_ 2566838923 Appl_Id_Byte_12 "Software Identification";
BA_ "CI_ParId" SG_ 2566838923 Appl_Id_Byte_12 "ESMD_03139";
BA_ "CI_SLOT_Name" SG_ 2566838923 Appl_Id_Byte_12 "SAEatad0200";
BA_ "SPN" SG_ 2566838923 Appl_Id_Byte_12 234;
BA_ "CI_FullName" SG_ 2566838923 Appl_Id_Byte_13 "Software Identification";
BA_ "CI_ParId" SG_ 2566838923 Appl_Id_Byte_13 "ESMD_03139";
BA_ "CI_SLOT_Name" SG_ 2566838923 Appl_Id_Byte_13 "SAEatad0200";
BA_ "SPN" SG_ 2566838923 Appl_Id_Byte_13 234;
BA_ "CI_FullName" SG_ 2566838923 Appl_Id_Byte_14 "Software Identification";
BA_ "CI_ParId" SG_ 2566838923 Appl_Id_Byte_14 "ESMD_03139";
BA_ "CI_SLOT_Name" SG_ 2566838923 Appl_Id_Byte_14 "SAEatad0200";
BA_ "SPN" SG_ 2566838923 Appl_Id_Byte_14 234;
BA_ "CI_FullName" SG_ 2566838923 Appl_Id_Byte_15 "Software Identification";
BA_ "CI_ParId" SG_ 2566838923 Appl_Id_Byte_15 "ESMD_03139";
BA_ "CI_SLOT_Name" SG_ 2566838923 Appl_Id_Byte_15 "SAEatad0200";
BA_ "SPN" SG_ 2566838923 Appl_Id_Byte_15 234;
BA_ "CI_FullName" SG_ 2566838923 Appl_Id_Byte_16 "Software Identification";
BA_ "CI_ParId" SG_ 2566838923 Appl_Id_Byte_16 "ESMD_03139";
BA_ "CI_SLOT_Name" SG_ 2566838923 Appl_Id_Byte_16 "SAEatad0200";
BA_ "SPN" SG_ 2566838923 Appl_Id_Byte_16 234;
BA_ "CI_FullName" SG_ 2566838923 Appl_Id_Byte_17 "Software Identification";
BA_ "CI_ParId" SG_ 2566838923 Appl_Id_Byte_17 "ESMD_03139";
BA_ "CI_SLOT_Name" SG_ 2566838923 Appl_Id_Byte_17 "SAEatad0200";
BA_ "SPN" SG_ 2566838923 Appl_Id_Byte_17 234;
BA_ "CI_FullName" SG_ 2566838923 Appl_Id_Byte_18 "Software Identification";
BA_ "CI_ParId" SG_ 2566838923 Appl_Id_Byte_18 "ESMD_03139";
BA_ "CI_SLOT_Name" SG_ 2566838923 Appl_Id_Byte_18 "SAEatad0200";
BA_ "SPN" SG_ 2566838923 Appl_Id_Byte_18 234;
BA_ "CI_FullName" SG_ 2566838923 Appl_Id_Byte_19 "Software Identification";
BA_ "CI_ParId" SG_ 2566838923 Appl_Id_Byte_19 "ESMD_03139";
BA_ "CI_SLOT_Name" SG_ 2566838923 Appl_Id_Byte_19 "SAEatad0200";
BA_ "SPN" SG_ 2566838923 Appl_Id_Byte_19 234;
BA_ "CI_FullName" SG_ 2566838923 Appl_Id_Byte_20 "Software Identification";
BA_ "CI_ParId" SG_ 2566838923 Appl_Id_Byte_20 "ESMD_03139";
BA_ "CI_SLOT_Name" SG_ 2566838923 Appl_Id_Byte_20 "SAEatad0200";
BA_ "SPN" SG_ 2566838923 Appl_Id_Byte_20 234;
BA_ "CI_FullName" SG_ 2566838923 Appl_Id_Byte_21 "Software Identification";
BA_ "CI_ParId" SG_ 2566838923 Appl_Id_Byte_21 "ESMD_03139";
BA_ "CI_SLOT_Name" SG_ 2566838923 Appl_Id_Byte_21 "SAEatad0200";
BA_ "SPN" SG_ 2566838923 Appl_Id_Byte_21 234;
BA_ "CI_FullName" SG_ 2566838923 Appl_Id_Byte_22 "Software Identification";
BA_ "CI_ParId" SG_ 2566838923 Appl_Id_Byte_22 "ESMD_03139";
BA_ "CI_SLOT_Name" SG_ 2566838923 Appl_Id_Byte_22 "SAEatad0200";
BA_ "SPN" SG_ 2566838923 Appl_Id_Byte_22 234;
BA_ "CI_FullName" SG_ 2566838923 Appl_Id_Byte_23 "Software Identification";
BA_ "CI_ParId" SG_ 2566838923 Appl_Id_Byte_23 "ESMD_03139";
BA_ "CI_SLOT_Name" SG_ 2566838923 Appl_Id_Byte_23 "SAEatad0200";
BA_ "SPN" SG_ 2566838923 Appl_Id_Byte_23 234;
BA_ "CI_RepetitionNum" SG_ 2566871842 MsgCnt_EHR 1;
BA_ "CI_RepetitionType" SG_ 2566871842 MsgCnt_EHR 3;
BA_ "CI_FullName" SG_ 2566871842 MsgCnt_EHR "Message Counter 2";
BA_ "CI_ParId" SG_ 2566871842 MsgCnt_EHR "ESMD_27907";
BA_ "CI_SLOT_Name" SG_ 2566871842 MsgCnt_EHR "SAEct08";
BA_ "GenSigStartValue" SG_ 2566871842 MsgCnt_EHR 12;
BA_ "SPN" SG_ 2566871842 MsgCnt_EHR 7041;
BA_ "CI_FullName" SG_ 2566871842 EHR_CntrlSts "EHR Control State";
BA_ "CI_ParId" SG_ 2566871842 EHR_CntrlSts "ESMD_20888";
BA_ "CI_FullName" SG_ 2566871842 EHR_CrvGrad "EHR Curve Gradient";
BA_ "CI_ParId" SG_ 2566871842 EHR_CrvGrad "ESMD_20889";
BA_ "CI_FullName" SG_ 2566871842 EHR_CrvShp "EHR Curve Shape";
BA_ "CI_ParId" SG_ 2566871842 EHR_CrvShp "ESMD_20890";
BA_ "CI_FullName" SG_ 2566871842 EHR_DynRmpTime "EHR Dynamic Ramp Time";
BA_ "CI_ParId" SG_ 2566871842 EHR_DynRmpTime "ESMD_20891";
BA_ "CI_FullName" SG_ 2566871842 EHR_EvFlow "EHR Valve Flow";
BA_ "CI_ParId" SG_ 2566871842 EHR_EvFlow "ESMD_20911";
BA_ "CI_FullName" SG_ 2566871842 EHR_EvNum "EHR Valve Number";
BA_ "CI_ParId" SG_ 2566871842 EHR_EvNum "ESMD_20914";
BA_ "CI_FullName" SG_ 2566871842 EHR_EvTemp "EHR Valve Temperature";
BA_ "CI_ParId" SG_ 2566871842 EHR_EvTemp "ESMD_20923";
BA_ "GenSigStartValue" SG_ 2566871842 EHR_EvTemp 40;
BA_ "CI_FullName" SG_ 2566871842 EHR_FailSafe "EHR Fail safe";
BA_ "CI_ParId" SG_ 2566871842 EHR_FailSafe "ESMD_20892";
BA_ "CI_FullName" SG_ 2566871842 EHR_Init "EHR Initial";
BA_ "CI_ParId" SG_ 2566871842 EHR_Init "ESMD_20897";
BA_ "CI_FullName" SG_ 2566871842 EHR_Op_1 "EHR Operation 1";
BA_ "CI_ParId" SG_ 2566871842 EHR_Op_1 "ESMD_20899";
BA_ "CI_FullName" SG_ 2566871842 EHR_Op_2 "EHR Operation 2";
BA_ "CI_ParId" SG_ 2566871842 EHR_Op_2 "ESMD_20900";
BA_ "GenSigAutoGenSnd" SG_ 2564487563 ProtocCntrlInfo 0;
BA_ "GenSigAutoGenDsp" SG_ 2564487563 ProtocCntrlInfo 0;
BA_ "CI_RepetitionComplemented" SG_ 2564487563 ProtocCntrlInfo 2;
BA_ "CI_FullName" SG_ 2564487563 ProtocCntrlInfo "Protocol Control Information";
BA_ "CI_ParId" SG_ 2564487563 ProtocCntrlInfo "ESMD_02905";
BA_ "GenSigAutoGenSnd" SG_ 2564487563 SingFrameDataLen 0;
BA_ "GenSigAutoGenDsp" SG_ 2564487563 SingFrameDataLen 0;
BA_ "CI_RepetitionComplemented" SG_ 2564487563 SingFrameDataLen 2;
BA_ "CI_FullName" SG_ 2564487563 SingFrameDataLen "Single Frame Data Length";
BA_ "CI_ParId" SG_ 2564487563 SingFrameDataLen "ESMD_03135";
BA_ "GenSigAutoGenSnd" SG_ 2564487563 N1FrameDataLen 0;
BA_ "GenSigAutoGenDsp" SG_ 2564487563 N1FrameDataLen 0;
BA_ "CI_RepetitionComplemented" SG_ 2564487563 N1FrameDataLen 2;
BA_ "CI_FullName" SG_ 2564487563 N1FrameDataLen "First Frame Data Length";
BA_ "CI_ParId" SG_ 2564487563 N1FrameDataLen "ESMD_01962";
BA_ "GenSigAutoGenSnd" SG_ 2564487563 FlowSts 0;
BA_ "GenSigAutoGenDsp" SG_ 2564487563 FlowSts 0;
BA_ "CI_RepetitionComplemented" SG_ 2564487563 FlowSts 2;
BA_ "CI_FullName" SG_ 2564487563 FlowSts "Flow Status";
BA_ "CI_ParId" SG_ 2564487563 FlowSts "ESMD_01968";
BA_ "GenSigAutoGenSnd" SG_ 2564487563 BlkSize 0;
BA_ "GenSigAutoGenDsp" SG_ 2564487563 BlkSize 0;
BA_ "CI_RepetitionComplemented" SG_ 2564487563 BlkSize 2;
BA_ "CI_FullName" SG_ 2564487563 BlkSize "Block Size";
BA_ "CI_ParId" SG_ 2564487563 BlkSize "ESMD_00809";
BA_ "GenSigAutoGenSnd" SG_ 2564487563 SepTime 0;
BA_ "GenSigAutoGenDsp" SG_ 2564487563 SepTime 0;
BA_ "CI_RepetitionComplemented" SG_ 2564487563 SepTime 2;
BA_ "CI_FullName" SG_ 2564487563 SepTime "Separation Time";
BA_ "CI_ParId" SG_ 2564487563 SepTime "ESMD_03113";
BA_ "GenSigAutoGenSnd" SG_ 2564487563 SN 0;
BA_ "GenSigAutoGenDsp" SG_ 2564487563 SN 0;
BA_ "CI_RepetitionComplemented" SG_ 2564487563 SN 2;
BA_ "CI_FullName" SG_ 2564487563 SN "Serial Number";
BA_ "CI_ParId" SG_ 2564487563 SN "ESMD_03138";
BA_ "CI_FullName" SG_ 2566855051 EHR_EvNumMeasFlow "EHR Valve Number Measured Flow";
BA_ "CI_ParId" SG_ 2566855051 EHR_EvNumMeasFlow "ESMD_20915";
BA_ "CI_FullName" SG_ 2566855051 MeasExtenFlow "Measured Extend Flow";
BA_ "CI_ParId" SG_ 2566855051 MeasExtenFlow "ESMD_20927";
BA_ "CI_FullName" SG_ 2566855051 MeasExtenPrs "Measured Extend Pressure";
BA_ "CI_ParId" SG_ 2566855051 MeasExtenPrs "ESMD_20928";
BA_ "CI_FullName" SG_ 2566855051 MeasRetractFlow "Measured Retract Flow";
BA_ "CI_ParId" SG_ 2566855051 MeasRetractFlow "ESMD_20929";
BA_ "CI_FullName" SG_ 2566855051 MeasRetractPrs "Measured Retract Pressure";
BA_ "CI_ParId" SG_ 2566855051 MeasRetractPrs "ESMD_20930";
BA_ "CI_FullName" SG_ 2566855051 ReturnPrs "Return Pressure";
BA_ "CI_ParId" SG_ 2566855051 ReturnPrs "ESMD_20933";
BA_ "SPN_Definition" SG_ 2566854795 SpoolPosition "91";
BA_ "CI_ParId" SG_ 2566854795 SpoolPosition "ESMD_27444";
BA_ "SPN" SG_ 2566854795 SpoolPosition 91;
BA_ "SigType" SG_ 2566854795 SpoolPosition 1;
BA_ "CI_RepetitionNum" SG_ 2566854795 MsgCnt_EHR 1;
BA_ "CI_RepetitionType" SG_ 2566854795 MsgCnt_EHR 3;
BA_ "CI_FullName" SG_ 2566854795 MsgCnt_EHR "Message Counter 2";
BA_ "CI_ParId" SG_ 2566854795 MsgCnt_EHR "ESMD_27907";
BA_ "CI_SLOT_Name" SG_ 2566854795 MsgCnt_EHR "SAEct08";
BA_ "GenSigStartValue" SG_ 2566854795 MsgCnt_EHR 12;
BA_ "SPN" SG_ 2566854795 MsgCnt_EHR 7041;
BA_ "CI_FullName" SG_ 2566854795 EHR_EvNum_4Bit "EHR Valve Number 4 Bit";
BA_ "CI_ParId" SG_ 2566854795 EHR_EvNum_4Bit "ESMD_20935";
BA_ "CI_FullName" SG_ 2566854795 EstExtenFlow "Estimated Extend Flow";
BA_ "CI_ParId" SG_ 2566854795 EstExtenFlow "ESMD_20924";
BA_ "GenSigStartValue" SG_ 2566854795 EstExtenFlow 128;
BA_ "CI_FullName" SG_ 2566854795 EstRetractFlow "Estimated Retract Flow";
BA_ "CI_ParId" SG_ 2566854795 EstRetractFlow "ESMD_20925";
BA_ "GenSigStartValue" SG_ 2566854795 EstRetractFlow 128;
BA_ "CI_FullName" SG_ 2566854795 FailSvng "Fail Saving";
BA_ "CI_ParId" SG_ 2566854795 FailSvng "ESMD_20926";
BA_ "CI_FullName" SG_ 2566854795 OpMode "Operation Mode";
BA_ "CI_ParId" SG_ 2566854795 OpMode "ESMD_20931";
BA_ "CI_FullName" SG_ 2566866059 EHR_RmpRndng "EHR Ramp Rounding";
BA_ "CI_ParId" SG_ 2566866059 EHR_RmpRndng "ESMD_20908";
BA_ "CI_FullName" SG_ 2566866059 EHR_ChksumStor "EHR Checksum Storage";
BA_ "CI_ParId" SG_ 2566866059 EHR_ChksumStor "ESMD_20887";
BA_ "CI_FullName" SG_ 2566866059 EHR_ChksumSW "EHR Checksum Software";
BA_ "CI_ParId" SG_ 2566866059 EHR_ChksumSW "ESMD_20886";
BA_ "CI_FullName" SG_ 2566866059 EHR_EvNumParamMux_12 "EHR Valve Number Parameter Multiplex 12";
BA_ "CI_ParId" SG_ 2566866059 EHR_EvNumParamMux_12 "ESMD_20916";
BA_ "CI_FullName" SG_ 2566866059 EHR_ParamStsByte_3 "EHR Parameter Status Byte 3";
BA_ "CI_ParId" SG_ 2566866059 EHR_ParamStsByte_3 "ESMD_20904";
BA_ "CI_FullName" SG_ 2566866059 EHR_ParamStsByte_2 "EHR Parameter Status Byte 2";
BA_ "CI_ParId" SG_ 2566866059 EHR_ParamStsByte_2 "ESMD_20903";
BA_ "CI_FullName" SG_ 2566866059 EHR_ParamByte_1 "EHR Parameter Byte 1";
BA_ "CI_ParId" SG_ 2566866059 EHR_ParamByte_1 "ESMD_20901";
BA_ "CI_FullName" SG_ 2566865547 EHR_EvTemp "EHR Valve Temperature";
BA_ "CI_ParId" SG_ 2566865547 EHR_EvTemp "ESMD_20923";
BA_ "GenSigStartValue" SG_ 2566865547 EHR_EvTemp 40;
BA_ "CI_FullName" SG_ 2566865547 EHR_SysId "EHR System Id";
BA_ "CI_ParId" SG_ 2566865547 EHR_SysId "ESMD_20910";
BA_ "CI_FullName" SG_ 2566865547 EHR_Err "EHR Fault";
BA_ "CI_ParId" SG_ 2566865547 EHR_Err "ESMD_20893";
BA_ "CI_FullName" SG_ 2566865547 EHR_InitDiag "EHR Initial Diagnostic";
BA_ "CI_ParId" SG_ 2566865547 EHR_InitDiag "ESMD_20898";
BA_ "CI_FullName" SG_ 2566865547 EHR_ErrCod "EHR Fault Code";
BA_ "CI_ParId" SG_ 2566865547 EHR_ErrCod "ESMD_20896";
BA_ "CI_FullName" SG_ 2566865547 EHR_SpoolTrav "EHR Spool Travel";
BA_ "CI_ParId" SG_ 2566865547 EHR_SpoolTrav "ESMD_20909";
BA_ "CI_FullName" SG_ 2566865547 EHR_EvNum "EHR Valve Number";
BA_ "CI_ParId" SG_ 2566865547 EHR_EvNum "ESMD_20914";
BA_ "CI_FullName" SG_ 2566835083 DTC_01 "Diagnostic Trouble Code 01";
BA_ "CI_ParId" SG_ 2566835083 DTC_01 "ESMD_01142";
BA_ "CI_FullName" SG_ 2566835083 FlashAmbrWarnLmpAWL "Flash Amber Warning Lamp (AWL)";
BA_ "CI_ParId" SG_ 2566835083 FlashAmbrWarnLmpAWL "ESMD_01963";
BA_ "CI_SLOT_Name" SG_ 2566835083 FlashAmbrWarnLmpAWL "SAEbs02";
BA_ "SPN" SG_ 2566835083 FlashAmbrWarnLmpAWL 3040;
BA_ "CI_FullName" SG_ 2566835083 FlashMIL "Flash Malfunction Indicator Lamp";
BA_ "CI_ParId" SG_ 2566835083 FlashMIL "ESMD_01964";
BA_ "CI_SLOT_Name" SG_ 2566835083 FlashMIL "SAEbs02";
BA_ "SPN" SG_ 2566835083 FlashMIL 3038;
BA_ "CI_FullName" SG_ 2566835083 FlashProtLmp "Flash Protect Lamp";
BA_ "CI_ParId" SG_ 2566835083 FlashProtLmp "ESMD_01965";
BA_ "CI_SLOT_Name" SG_ 2566835083 FlashProtLmp "SAEbs02";
BA_ "SPN" SG_ 2566835083 FlashProtLmp 3041;
BA_ "CI_FullName" SG_ 2566835083 FlashRedStopLmpRSL "Flash Red Stop Lamp (RSL)";
BA_ "CI_ParId" SG_ 2566835083 FlashRedStopLmpRSL "ESMD_01966";
BA_ "CI_SLOT_Name" SG_ 2566835083 FlashRedStopLmpRSL "SAEbs02";
BA_ "SPN" SG_ 2566835083 FlashRedStopLmpRSL 3039;
BA_ "CI_FullName" SG_ 2566835083 ProtLmp "Protect Lamp";
BA_ "CI_ParId" SG_ 2566835083 ProtLmp "ESMD_02904";
BA_ "CI_SLOT_Name" SG_ 2566835083 ProtLmp "SAEbs02";
BA_ "SPN" SG_ 2566835083 ProtLmp 987;
BA_ "CI_FullName" SG_ 2566835083 AmbrWarnLmp "Amber Warning Lamp";
BA_ "CI_ParId" SG_ 2566835083 AmbrWarnLmp "ESMD_00554";
BA_ "CI_SLOT_Name" SG_ 2566835083 AmbrWarnLmp "SAEbs02";
BA_ "SPN" SG_ 2566835083 AmbrWarnLmp 624;
BA_ "CI_FullName" SG_ 2566835083 RedStopLmp "Red Stop Lamp";
BA_ "CI_ParId" SG_ 2566835083 RedStopLmp "ESMD_02945";
BA_ "CI_SLOT_Name" SG_ 2566835083 RedStopLmp "SAEbs02";
BA_ "SPN" SG_ 2566835083 RedStopLmp 623;
BA_ "CI_FullName" SG_ 2566835083 MIL "Malfunction Indicator Lamp";
BA_ "CI_ParId" SG_ 2566835083 MIL "ESMD_02672";
BA_ "CI_SLOT_Name" SG_ 2566835083 MIL "SAEbs02";
BA_ "SPN" SG_ 2566835083 MIL 1213;
BA_ "CI_FullName" SG_ 2566834827 DTC_10 "Diagnostic Trouble Code 10";
BA_ "CI_ParId" SG_ 2566834827 DTC_10 "ESMD_03836";
BA_ "CI_FullName" SG_ 2566834827 DTC_09 "Diagnostic Trouble Code 09";
BA_ "CI_ParId" SG_ 2566834827 DTC_09 "ESMD_03835";
BA_ "CI_FullName" SG_ 2566834827 DTC_08 "Diagnostic Trouble Code 08";
BA_ "CI_ParId" SG_ 2566834827 DTC_08 "ESMD_03834";
BA_ "CI_FullName" SG_ 2566834827 DTC_07 "Diagnostic Trouble Code 07";
BA_ "CI_ParId" SG_ 2566834827 DTC_07 "ESMD_03833";
BA_ "CI_FullName" SG_ 2566834827 DTC_06 "Diagnostic Trouble Code 06";
BA_ "CI_ParId" SG_ 2566834827 DTC_06 "ESMD_03832";
BA_ "CI_FullName" SG_ 2566834827 DTC_05 "Diagnostic Trouble Code 05";
BA_ "CI_ParId" SG_ 2566834827 DTC_05 "ESMD_01146";
BA_ "CI_FullName" SG_ 2566834827 DTC_04 "Diagnostic Trouble Code 04";
BA_ "CI_ParId" SG_ 2566834827 DTC_04 "ESMD_01145";
BA_ "CI_FullName" SG_ 2566834827 DTC_03 "Diagnostic Trouble Code 03";
BA_ "CI_ParId" SG_ 2566834827 DTC_03 "ESMD_01144";
BA_ "CI_FullName" SG_ 2566834827 DTC_02 "Diagnostic Trouble Code 02";
BA_ "CI_ParId" SG_ 2566834827 DTC_02 "ESMD_01143";
BA_ "CI_FullName" SG_ 2566834827 DTC_01 "Diagnostic Trouble Code 01";
BA_ "CI_ParId" SG_ 2566834827 DTC_01 "ESMD_01142";
BA_ "CI_FullName" SG_ 2566834827 ProtLmp "Protect Lamp";
BA_ "CI_ParId" SG_ 2566834827 ProtLmp "ESMD_02904";
BA_ "CI_SLOT_Name" SG_ 2566834827 ProtLmp "SAEbs02";
BA_ "SPN" SG_ 2566834827 ProtLmp 987;
BA_ "CI_FullName" SG_ 2566834827 RedStopLmp "Red Stop Lamp";
BA_ "CI_ParId" SG_ 2566834827 RedStopLmp "ESMD_02945";
BA_ "CI_SLOT_Name" SG_ 2566834827 RedStopLmp "SAEbs02";
BA_ "SPN" SG_ 2566834827 RedStopLmp 623;
BA_ "CI_FullName" SG_ 2566834827 AmbrWarnLmp "Amber Warning Lamp";
BA_ "CI_ParId" SG_ 2566834827 AmbrWarnLmp "ESMD_00554";
BA_ "CI_SLOT_Name" SG_ 2566834827 AmbrWarnLmp "SAEbs02";
BA_ "SPN" SG_ 2566834827 AmbrWarnLmp 624;
BA_ "CI_FullName" SG_ 2566834827 MIL "Malfunction Indicator Lamp";
BA_ "CI_ParId" SG_ 2566834827 MIL "ESMD_02672";
BA_ "CI_SLOT_Name" SG_ 2566834827 MIL "SAEbs02";
BA_ "SPN" SG_ 2566834827 MIL 1213;
BA_ "CI_FullName" SG_ 2566834827 FlashAmbrWarnLmpAWL "Flash Amber Warning Lamp (AWL)";
BA_ "CI_ParId" SG_ 2566834827 FlashAmbrWarnLmpAWL "ESMD_01963";
BA_ "CI_SLOT_Name" SG_ 2566834827 FlashAmbrWarnLmpAWL "SAEbs02";
BA_ "SPN" SG_ 2566834827 FlashAmbrWarnLmpAWL 3040;
BA_ "CI_FullName" SG_ 2566834827 FlashMIL "Flash Malfunction Indicator Lamp";
BA_ "CI_ParId" SG_ 2566834827 FlashMIL "ESMD_01964";
BA_ "CI_SLOT_Name" SG_ 2566834827 FlashMIL "SAEbs02";
BA_ "SPN" SG_ 2566834827 FlashMIL 3038;
BA_ "CI_FullName" SG_ 2566834827 FlashProtLmp "Flash Protect Lamp";
BA_ "CI_ParId" SG_ 2566834827 FlashProtLmp "ESMD_01965";
BA_ "CI_SLOT_Name" SG_ 2566834827 FlashProtLmp "SAEbs02";
BA_ "SPN" SG_ 2566834827 FlashProtLmp 3041;
BA_ "CI_FullName" SG_ 2566834827 FlashRedStopLmpRSL "Flash Red Stop Lamp (RSL)";
BA_ "CI_ParId" SG_ 2566834827 FlashRedStopLmpRSL "ESMD_01966";
BA_ "CI_SLOT_Name" SG_ 2566834827 FlashRedStopLmpRSL "SAEbs02";
BA_ "SPN" SG_ 2566834827 FlashRedStopLmpRSL 3039;
BA_ "CI_FullName" SG_ 2499803431 MsgChksum_3 "Message Checksum 3";
BA_ "CI_ParId" SG_ 2499803431 MsgChksum_3 "ESMD_16006";
BA_ "CI_SLOT_Name" SG_ 2499803431 MsgChksum_3 "SAEct03";
BA_ "SPN" SG_ 2499803431 MsgChksum_3 7042;
BA_ "GenSigAutoGenSnd" SG_ 2499803431 MsgCnt 0;
BA_ "GenSigAutoGenDsp" SG_ 2499803431 MsgCnt 0;
BA_ "CI_FullName" SG_ 2499803431 MsgCnt "Message Counter";
BA_ "CI_ParId" SG_ 2499803431 MsgCnt "ESMD_02699";
BA_ "CI_SLOT_Name" SG_ 2499803431 MsgCnt "SAEct08";
BA_ "SPN" SG_ 2499803431 MsgCnt 3689;
BA_ "CI_RepetitionNum" SG_ 2499803431 ExtPrsRqst 1;
BA_ "CI_RepetitionType" SG_ 2499803431 ExtPrsRqst 3;
BA_ "CI_FullName" SG_ 2499803431 ExtPrsRqst "External Pressure Demand";
BA_ "CI_ParId" SG_ 2499803431 ExtPrsRqst "ESMD_24420";
BA_ "CI_SLOT_Name" SG_ 2499803431 ExtPrsRqst "SAEpr11";
BA_ "SPN" SG_ 2499803431 ExtPrsRqst 518897;
BA_ "CI_RepetitionNum" SG_ 2499803431 XPD_CntrlMode 1;
BA_ "CI_RepetitionType" SG_ 2499803431 XPD_CntrlMode 3;
BA_ "CI_FullName" SG_ 2499803431 XPD_CntrlMode "XPD Control Mode";
BA_ "CI_ParId" SG_ 2499803431 XPD_CntrlMode "ESMD_24421";
BA_ "CI_SLOT_Name" SG_ 2499803431 XPD_CntrlMode "SAEbs02";
BA_ "SPN" SG_ 2499803431 XPD_CntrlMode 518898;
BA_ "CI_RepetitionNum" SG_ 2499803431 XPD_Prio 1;
BA_ "CI_RepetitionType" SG_ 2499803431 XPD_Prio 3;
BA_ "CI_FullName" SG_ 2499803431 XPD_Prio "XPD Priority";
BA_ "CI_ParId" SG_ 2499803431 XPD_Prio "ESMD_24424";
BA_ "CI_SLOT_Name" SG_ 2499803431 XPD_Prio "SAEbs02";
BA_ "SPN" SG_ 2499803431 XPD_Prio 518901;
BA_ "CI_FullName" SG_ 2499743527 TrailPBrakeReq "Trailer Park Brake Request";
BA_ "CI_ParId" SG_ 2499743527 TrailPBrakeReq "NWD-1923";
BA_ "CI_SLOT_Name" SG_ 2499743527 TrailPBrakeReq "SAEbs02";
BA_ "SPN" SG_ 2499743527 TrailPBrakeReq 522503;
BA_ "CI_FullName" SG_ 2499743527 SteerBrakeDirect "Steering Brake Direction";
BA_ "CI_ParId" SG_ 2499743527 SteerBrakeDirect "NWD-1922";
BA_ "CI_SLOT_Name" SG_ 2499743527 SteerBrakeDirect "SAEbs02";
BA_ "SPN" SG_ 2499743527 SteerBrakeDirect 522502;
BA_ "GenSigAutoGenSnd" SG_ 2499743527 MsgCnt 0;
BA_ "GenSigAutoGenDsp" SG_ 2499743527 MsgCnt 0;
BA_ "CI_FullName" SG_ 2499743527 MsgCnt "Message Counter";
BA_ "CI_ParId" SG_ 2499743527 MsgCnt "ESMD_02699";
BA_ "CI_SLOT_Name" SG_ 2499743527 MsgCnt "SAEct08";
BA_ "SPN" SG_ 2499743527 MsgCnt 3689;
BA_ "CI_FullName" SG_ 2499743527 MsgChksum_3 "Message Checksum 3";
BA_ "CI_ParId" SG_ 2499743527 MsgChksum_3 "ESMD_16006";
BA_ "CI_SLOT_Name" SG_ 2499743527 MsgChksum_3 "SAEct03";
BA_ "SPN" SG_ 2499743527 MsgChksum_3 7042;
BA_ "CI_FullName" SG_ 2499743527 TrailBrakeRleasWarn "Trailer brake release warning";
BA_ "CI_ParId" SG_ 2499743527 TrailBrakeRleasWarn "ESMD_20424";
BA_ "CI_SLOT_Name" SG_ 2499743527 TrailBrakeRleasWarn "SAEbs02";
BA_ "SPN" SG_ 2499743527 TrailBrakeRleasWarn 517762;
BA_ "CI_FullName" SG_ 2499743527 RightBrakePedPositn "Right Brake Pedal Position";
BA_ "CI_ParId" SG_ 2499743527 RightBrakePedPositn "ESMD_16413";
BA_ "CI_SLOT_Name" SG_ 2499743527 RightBrakePedPositn "SAEpc03";
BA_ "SPN" SG_ 2499743527 RightBrakePedPositn 3032;
BA_ "CI_FullName" SG_ 2499743527 LeftBrakePedPositn "Left Brake Pedal Position";
BA_ "CI_ParId" SG_ 2499743527 LeftBrakePedPositn "ESMD_16414";
BA_ "CI_SLOT_Name" SG_ 2499743527 LeftBrakePedPositn "SAEpc03";
BA_ "SPN" SG_ 2499743527 LeftBrakePedPositn 3033;
BA_ "CI_RepetitionNum" SG_ 2499743527 RightBrakeSts 1;
BA_ "CI_RepetitionType" SG_ 2499743527 RightBrakeSts 3;
BA_ "CI_FullName" SG_ 2499743527 RightBrakeSts "Right Brake Status";
BA_ "CI_ParId" SG_ 2499743527 RightBrakeSts "ESMD_20086";
BA_ "CI_SLOT_Name" SG_ 2499743527 RightBrakeSts "SAEbs02";
BA_ "SPN" SG_ 2499743527 RightBrakeSts 518703;
BA_ "CI_RepetitionNum" SG_ 2499743527 LeftBrakeSts 1;
BA_ "CI_RepetitionType" SG_ 2499743527 LeftBrakeSts 3;
BA_ "CI_FullName" SG_ 2499743527 LeftBrakeSts "Left Brake Status";
BA_ "CI_ParId" SG_ 2499743527 LeftBrakeSts "ESMD_20087";
BA_ "CI_SLOT_Name" SG_ 2499743527 LeftBrakeSts "SAEbs02";
BA_ "SPN" SG_ 2499743527 LeftBrakeSts 518704;
BA_ "CI_FullName" SG_ 2499743527 BrakePedLckSts "Brake pedals lock status";
BA_ "CI_ParId" SG_ 2499743527 BrakePedLckSts "ESMD_27403";
BA_ "CI_SLOT_Name" SG_ 2499743527 BrakePedLckSts "SAEbs02";
BA_ "SPN" SG_ 2499743527 BrakePedLckSts 517710;
BA_ "CI_RepetitionNum" SG_ 2499743527 TrailBrakeReq 1;
BA_ "CI_RepetitionType" SG_ 2499743527 TrailBrakeReq 3;
BA_ "CI_FullName" SG_ 2499743527 TrailBrakeReq "Trailer Brake Request";
BA_ "CI_ParId" SG_ 2499743527 TrailBrakeReq "ESMD_24419";
BA_ "CI_SLOT_Name" SG_ 2499743527 TrailBrakeReq "SAEbs02";
BA_ "SPN" SG_ 2499743527 TrailBrakeReq 518896;
BA_ "CI_RepetitionNum" SG_ 2499743527 SecBrakePositn 1;
BA_ "CI_RepetitionType" SG_ 2499743527 SecBrakePositn 3;
BA_ "CI_FullName" SG_ 2499743527 SecBrakePositn "Secondary Brake Position";
BA_ "CI_ParId" SG_ 2499743527 SecBrakePositn "ESMD_24418";
BA_ "CI_SLOT_Name" SG_ 2499743527 SecBrakePositn "SAEpc03";
BA_ "SPN" SG_ 2499743527 SecBrakePositn 518895;
BA_ "CI_FullName" SG_ 2499743527 SecBrakeSw "Second Brake Switch";
BA_ "CI_ParId" SG_ 2499743527 SecBrakeSw "NWD-1921";
BA_ "CI_SLOT_Name" SG_ 2499743527 SecBrakeSw "SAEbs02";
BA_ "SPN" SG_ 2499743527 SecBrakeSw 522501;
BA_ "CI_FullName" SG_ 2566857475 KeySts "Key Status";
BA_ "CI_ParId" SG_ 2566857475 KeySts "NW_2781";
BA_ "CI_SLOT_Name" SG_ 2566857475 KeySts "SAEbs02";
BA_ "SPN" SG_ 2566857475 KeySts 520802;
BA_ "CI_FullName" SG_ 2566857475 CrankSts "Cranking Status";
BA_ "CI_ParId" SG_ 2566857475 CrankSts "NW_2783";
BA_ "CI_SLOT_Name" SG_ 2566857475 CrankSts "SAEbs02";
BA_ "SPN" SG_ 2566857475 CrankSts 520804;
BA_ "CI_FullName" SG_ 2566857475 DigitDumpSts "Digital Dump Status";
BA_ "CI_ParId" SG_ 2566857475 DigitDumpSts "NW_2782";
BA_ "CI_SLOT_Name" SG_ 2566857475 DigitDumpSts "SAEbs02";
BA_ "SPN" SG_ 2566857475 DigitDumpSts 520803;
BA_ "CI_FullName" SG_ 2566857475 V_Ref_5VSensSupply_2 "Voltage Reference 5V Sensor Supply 2";
BA_ "CI_ParId" SG_ 2566857475 V_Ref_5VSensSupply_2 "NWD_2148";
BA_ "CI_SLOT_Name" SG_ 2566857475 V_Ref_5VSensSupply_2 "SAEbs03";
BA_ "SPN" SG_ 2566857475 V_Ref_5VSensSupply_2 3510;
BA_ "CI_FullName" SG_ 2566857475 V_Ref_85VSensSupply_1 "Voltage Reference 8.5V Sensor Supply 1";
BA_ "CI_ParId" SG_ 2566857475 V_Ref_85VSensSupply_1 "NWD_2146";
BA_ "CI_SLOT_Name" SG_ 2566857475 V_Ref_85VSensSupply_1 "CNHev10";
BA_ "SPN" SG_ 2566857475 V_Ref_85VSensSupply_1 3513;
BA_ "CI_FullName" SG_ 2566857475 V_Ref_5VSensSupply_1 "Voltage Reference 5V Sensor Supply 1";
BA_ "CI_ParId" SG_ 2566857475 V_Ref_5VSensSupply_1 "NWD_2147";
BA_ "CI_SLOT_Name" SG_ 2566857475 V_Ref_5VSensSupply_1 "SAEbs03";
BA_ "SPN" SG_ 2566857475 V_Ref_5VSensSupply_1 3509;
BA_ "CI_FullName" SG_ 2566857475 V_Ref_5VSensSupply_TLF "Voltage Reference 5V Sensor Supply TLF";
BA_ "CI_ParId" SG_ 2566857475 V_Ref_5VSensSupply_TLF "NWD_2143";
BA_ "CI_SLOT_Name" SG_ 2566857475 V_Ref_5VSensSupply_TLF "CNHev09";
BA_ "SPN" SG_ 2566857475 V_Ref_5VSensSupply_TLF 522656;
BA_ "CI_FullName" SG_ 2566857475 SensSupplyV_12V "Sensor Supply Voltage 12 V";
BA_ "CI_ParId" SG_ 2566857475 SensSupplyV_12V "NWD_2149";
BA_ "CI_SLOT_Name" SG_ 2566857475 SensSupplyV_12V "SAEbs02";
BA_ "SPN" SG_ 2566857475 SensSupplyV_12V 3514;
BA_ "CI_FullName" SG_ 2566857475 V_Ref_5VSensSupply_4 "Voltage Reference 5V Sensor Supply 4";
BA_ "CI_ParId" SG_ 2566857475 V_Ref_5VSensSupply_4 "NWD_2145";
BA_ "CI_SLOT_Name" SG_ 2566857475 V_Ref_5VSensSupply_4 "CNHev09";
BA_ "SPN" SG_ 2566857475 V_Ref_5VSensSupply_4 3512;
BA_ "CI_FullName" SG_ 2566857475 V_Ref_5VSensSupply_3 "Voltage Reference 5V Sensor Supply 3";
BA_ "CI_ParId" SG_ 2566857475 V_Ref_5VSensSupply_3 "NWD_2144";
BA_ "CI_SLOT_Name" SG_ 2566857475 V_Ref_5VSensSupply_3 "CNHev09";
BA_ "SPN" SG_ 2566857475 V_Ref_5VSensSupply_3 3511;
BA_ "CI_FullName" SG_ 2566857475 V_BattPerm "Voltage Battery Permanent";
BA_ "CI_ParId" SG_ 2566857475 V_BattPerm "NWD_2142";
BA_ "CI_SLOT_Name" SG_ 2566857475 V_BattPerm "CNHev08";
BA_ "SPN" SG_ 2566857475 V_BattPerm 522655;
BA_ "CI_FullName" SG_ 2566857475 V_BattLoad "Voltage Battery Loads";
BA_ "CI_ParId" SG_ 2566857475 V_BattLoad "NWD_2141";
BA_ "CI_SLOT_Name" SG_ 2566857475 V_BattLoad "CNHev08";
BA_ "SPN" SG_ 2566857475 V_BattLoad 522654;
BA_ "GenSigAutoGenSnd" SG_ 2564488958 ProtocCntrlInfo 0;
BA_ "GenSigAutoGenDsp" SG_ 2564488958 ProtocCntrlInfo 0;
BA_ "CI_RepetitionComplemented" SG_ 2564488958 ProtocCntrlInfo 2;
BA_ "CI_FullName" SG_ 2564488958 ProtocCntrlInfo "Protocol Control Information";
BA_ "CI_ParId" SG_ 2564488958 ProtocCntrlInfo "ESMD_02905";
BA_ "GenSigAutoGenSnd" SG_ 2564488958 SN 0;
BA_ "GenSigAutoGenDsp" SG_ 2564488958 SN 0;
BA_ "CI_RepetitionComplemented" SG_ 2564488958 SN 2;
BA_ "CI_FullName" SG_ 2564488958 SN "Serial Number";
BA_ "CI_ParId" SG_ 2564488958 SN "ESMD_03138";
BA_ "GenSigAutoGenSnd" SG_ 2564488958 SepTime 0;
BA_ "GenSigAutoGenDsp" SG_ 2564488958 SepTime 0;
BA_ "CI_RepetitionComplemented" SG_ 2564488958 SepTime 2;
BA_ "CI_FullName" SG_ 2564488958 SepTime "Separation Time";
BA_ "CI_ParId" SG_ 2564488958 SepTime "ESMD_03113";
BA_ "GenSigAutoGenSnd" SG_ 2564488958 SingFrameDataLen 0;
BA_ "GenSigAutoGenDsp" SG_ 2564488958 SingFrameDataLen 0;
BA_ "CI_RepetitionComplemented" SG_ 2564488958 SingFrameDataLen 2;
BA_ "CI_FullName" SG_ 2564488958 SingFrameDataLen "Single Frame Data Length";
BA_ "CI_ParId" SG_ 2564488958 SingFrameDataLen "ESMD_03135";
BA_ "GenSigAutoGenSnd" SG_ 2564488958 N1FrameDataLen 0;
BA_ "GenSigAutoGenDsp" SG_ 2564488958 N1FrameDataLen 0;
BA_ "CI_RepetitionComplemented" SG_ 2564488958 N1FrameDataLen 2;
BA_ "CI_FullName" SG_ 2564488958 N1FrameDataLen "First Frame Data Length";
BA_ "CI_ParId" SG_ 2564488958 N1FrameDataLen "ESMD_01962";
BA_ "GenSigAutoGenSnd" SG_ 2564488958 FlowSts 0;
BA_ "GenSigAutoGenDsp" SG_ 2564488958 FlowSts 0;
BA_ "CI_RepetitionComplemented" SG_ 2564488958 FlowSts 2;
BA_ "CI_FullName" SG_ 2564488958 FlowSts "Flow Status";
BA_ "CI_ParId" SG_ 2564488958 FlowSts "ESMD_01968";
BA_ "GenSigAutoGenSnd" SG_ 2564488958 BlkSize 0;
BA_ "GenSigAutoGenDsp" SG_ 2564488958 BlkSize 0;
BA_ "CI_RepetitionComplemented" SG_ 2564488958 BlkSize 2;
BA_ "CI_FullName" SG_ 2564488958 BlkSize "Block Size";
BA_ "CI_ParId" SG_ 2564488958 BlkSize "ESMD_00809";
BA_ "CI_FullName" SG_ 2565603086 PktDataTPDT "Packetized Data (TP.DT)";
BA_ "CI_ParId" SG_ 2565603086 PktDataTPDT "ESMD_16027";
BA_ "SPN" SG_ 2565603086 PktDataTPDT 2573;
BA_ "CI_FullName" SG_ 2565603086 SN_TPDT "Sequence Number (TP.DT)";
BA_ "CI_ParId" SG_ 2565603086 SN_TPDT "ESMD_03114";
BA_ "SPN" SG_ 2565603086 SN_TPDT 2572;
BA_ "CI_FullName" SG_ 2499785475 RearHitchDraftLoad "Rear Hitch Draft Load";
BA_ "CI_ParId" SG_ 2499785475 RearHitchDraftLoad "ESMD_20558";
BA_ "CI_SLOT_Name" SG_ 2499785475 RearHitchDraftLoad "SAEpc06";
BA_ "SPN" SG_ 2499785475 RearHitchDraftLoad 517735;
BA_ "CI_FullName" SG_ 2499785475 DrvlRecovReq "Driveline Recovery Request";
BA_ "CI_ParId" SG_ 2499785475 DrvlRecovReq "NWD-2066";
BA_ "CI_SLOT_Name" SG_ 2499785475 DrvlRecovReq "SAEbs03";
BA_ "SPN" SG_ 2499785475 DrvlRecovReq 522594;
BA_ "CI_FullName" SG_ 2499785475 DrvlItemUnderCalibr "Driveline Item Under Calibration";
BA_ "CI_ParId" SG_ 2499785475 DrvlItemUnderCalibr "NW-2780";
BA_ "CI_SLOT_Name" SG_ 2499785475 DrvlItemUnderCalibr "SAEbs03";
BA_ "SPN" SG_ 2499785475 DrvlItemUnderCalibr 520764;
BA_ "CI_FullName" SG_ 2499785475 RngLckFdbk "Range lock feedback";
BA_ "CI_ParId" SG_ 2499785475 RngLckFdbk "ESMD_23685";
BA_ "CI_SLOT_Name" SG_ 2499785475 RngLckFdbk "SAEbs02";
BA_ "SPN" SG_ 2499785475 RngLckFdbk 519845;
BA_ "CI_RepetitionNum" SG_ 2499785475 VehSpdSecSetpFdbk 1;
BA_ "CI_RepetitionType" SG_ 2499785475 VehSpdSecSetpFdbk 3;
BA_ "CI_FullName" SG_ 2499785475 VehSpdSecSetpFdbk "Vehicle Speed Secondary Setpoint Feedback";
BA_ "CI_ParId" SG_ 2499785475 VehSpdSecSetpFdbk "ESMD_20096";
BA_ "CI_SLOT_Name" SG_ 2499785475 VehSpdSecSetpFdbk "SAEpc02";
BA_ "SPN" SG_ 2499785475 VehSpdSecSetpFdbk 519777;
BA_ "CI_FullName" SG_ 2499785475 DecelTorq "Deceleration Torque";
BA_ "CI_ParId" SG_ 2499785475 DecelTorq "ESMD_28259";
BA_ "CI_SLOT_Name" SG_ 2499785475 DecelTorq "SAEtq02";
BA_ "SPN" SG_ 2499785475 DecelTorq 519626;
BA_ "CI_FullName" SG_ 2499785475 PTO_AntiPitchFdbk "PTO Antipitch Feedback";
BA_ "CI_ParId" SG_ 2499785475 PTO_AntiPitchFdbk "NWD-1622";
BA_ "CI_SLOT_Name" SG_ 2499785475 PTO_AntiPitchFdbk "SAEbs02";
BA_ "SPN" SG_ 2499785475 PTO_AntiPitchFdbk 522281;
BA_ "CI_ParId" SG_ 2499785475 TransmDsrdSubmodeFdbk "NWD-1664";
BA_ "CI_SLOT_Name" SG_ 2499785475 TransmDsrdSubmodeFdbk "SAEbs03";
BA_ "SPN" SG_ 2499785475 TransmDsrdSubmodeFdbk 522010;
BA_ "CI_FullName" SG_ 2566877699 PBrakeTyp "Parking Brake Type";
BA_ "CI_ParId" SG_ 2566877699 PBrakeTyp "ESMD_26979";
BA_ "CI_SLOT_Name" SG_ 2566877699 PBrakeTyp "SAEbs04";
BA_ "SPN" SG_ 2566877699 PBrakeTyp 519262;
BA_ "CI_FullName" SG_ 2566877699 CreeprPresence "Creeper Presence";
BA_ "CI_ParId" SG_ 2566877699 CreeprPresence "ESMD_26971";
BA_ "CI_SLOT_Name" SG_ 2566877699 CreeprPresence "SAEbs02";
BA_ "SPN" SG_ 2566877699 CreeprPresence 519254;
BA_ "CI_FullName" SG_ 2566877699 DifflckTyp "Difflock type";
BA_ "CI_ParId" SG_ 2566877699 DifflckTyp "ESMD_28272";
BA_ "CI_FullName" SG_ 2566877699 DrvlTyp "Driveline Type";
BA_ "CI_ParId" SG_ 2566877699 DrvlTyp "ESMD_26970";
BA_ "CI_SLOT_Name" SG_ 2566877699 DrvlTyp "CNHbs16";
BA_ "SPN" SG_ 2566877699 DrvlTyp 519253;
BA_ "CI_FullName" SG_ 2566877699 ECU_DatasetInfoMapId "ECU dataset - Information mapping ID";
BA_ "CI_ParId" SG_ 2566877699 ECU_DatasetInfoMapId "ESMD_23037";
BA_ "CI_SLOT_Name" SG_ 2566877699 ECU_DatasetInfoMapId "SAEid01";
BA_ "SPN" SG_ 2566877699 ECU_DatasetInfoMapId 516611;
BA_ "SigType" SG_ 2566877699 ECU_DatasetInfoMapId 1;
BA_ "CI_FullName" SG_ 2566877699 EPL_Presence "EPL Presence";
BA_ "CI_ParId" SG_ 2566877699 EPL_Presence "ESMD_28358";
BA_ "CI_SLOT_Name" SG_ 2566877699 EPL_Presence "SAEbs02";
BA_ "SPN" SG_ 2566877699 EPL_Presence 520155;
BA_ "CI_FullName" SG_ 2566877699 MFD_Presence "Mechanical Front Drive Presence";
BA_ "CI_ParId" SG_ 2566877699 MFD_Presence "ESMD_26974";
BA_ "CI_SLOT_Name" SG_ 2566877699 MFD_Presence "SAEbs02";
BA_ "SPN" SG_ 2566877699 MFD_Presence 519257;
BA_ "CI_FullName" SG_ 2566877699 OverDrivPresence "Overdrive Presence";
BA_ "CI_ParId" SG_ 2566877699 OverDrivPresence "ESMD_26972";
BA_ "CI_SLOT_Name" SG_ 2566877699 OverDrivPresence "SAEbs02";
BA_ "SPN" SG_ 2566877699 OverDrivPresence 519255;
BA_ "CI_FullName" SG_ 2566877699 GPTO_Presence "Ground Speed PTO Presence";
BA_ "CI_ParId" SG_ 2566877699 GPTO_Presence "ESMD_27375";
BA_ "CI_SLOT_Name" SG_ 2566877699 GPTO_Presence "SAEbs02";
BA_ "SPN" SG_ 2566877699 GPTO_Presence 519349;
BA_ "CI_FullName" SG_ 2566877699 PTO_Typ "PTO Type";
BA_ "CI_ParId" SG_ 2566877699 PTO_Typ "ESMD_27374";
BA_ "CI_SLOT_Name" SG_ 2566877699 PTO_Typ "SAEbs06";
BA_ "SPN" SG_ 2566877699 PTO_Typ 519258;
BA_ "CI_FullName" SG_ 2566877699 FrntDifflckSolPresence "Front Difflock solenoid presence";
BA_ "CI_ParId" SG_ 2566877699 FrntDifflckSolPresence "ESMD_23689";
BA_ "CI_SLOT_Name" SG_ 2566877699 FrntDifflckSolPresence "SAEbs02";
BA_ "SPN" SG_ 2566877699 FrntDifflckSolPresence 520096;
BA_ "CI_FullName" SG_ 2566877699 B2C_Presence "Brake to clutch Presence";
BA_ "CI_ParId" SG_ 2566877699 B2C_Presence "ESMD_28300";
BA_ "CI_SLOT_Name" SG_ 2566877699 B2C_Presence "SAEbs02";
BA_ "SPN" SG_ 2566877699 B2C_Presence 519699;
BA_ "GenSigAutoGenSnd" SG_ 2565351182 AddrAccssDeny 0;
BA_ "GenSigAutoGenDsp" SG_ 2565351182 AddrAccssDeny 0;
BA_ "CI_FullName" SG_ 2565351182 AddrAccssDeny "Address Access Denied";
BA_ "CI_ParId" SG_ 2565351182 AddrAccssDeny "ESMD_00040";
BA_ "SPN" SG_ 2565351182 AddrAccssDeny 3292;
BA_ "GenSigAutoGenSnd" SG_ 2565351182 AddrAck 0;
BA_ "GenSigAutoGenDsp" SG_ 2565351182 AddrAck 0;
BA_ "CI_FullName" SG_ 2565351182 AddrAck "Address Acknowledged";
BA_ "CI_ParId" SG_ 2565351182 AddrAck "ESMD_00041";
BA_ "SPN" SG_ 2565351182 AddrAck 3290;
BA_ "GenSigAutoGenSnd" SG_ 2565351182 AddrBusy 0;
BA_ "GenSigAutoGenDsp" SG_ 2565351182 AddrBusy 0;
BA_ "CI_FullName" SG_ 2565351182 AddrBusy "Address Busy";
BA_ "CI_ParId" SG_ 2565351182 AddrBusy "ESMD_00043";
BA_ "SPN" SG_ 2565351182 AddrBusy 3293;
BA_ "GenSigAutoGenSnd" SG_ 2565351182 AddrNegAck 0;
BA_ "GenSigAutoGenDsp" SG_ 2565351182 AddrNegAck 0;
BA_ "CI_FullName" SG_ 2565351182 AddrNegAck "Address Negative Acknowledgement";
BA_ "CI_ParId" SG_ 2565351182 AddrNegAck "ESMD_00044";
BA_ "SPN" SG_ 2565351182 AddrNegAck 3291;
BA_ "GenSigAutoGenSnd" SG_ 2565351182 CByteAckm 0;
BA_ "GenSigAutoGenDsp" SG_ 2565351182 CByteAckm 0;
BA_ "CI_FullName" SG_ 2565351182 CByteAckm "Control Byte (ACKM)";
BA_ "CI_ParId" SG_ 2565351182 CByteAckm "ESMD_00942";
BA_ "SPN" SG_ 2565351182 CByteAckm 2541;
BA_ "SigType" SG_ 2565351182 CByteAckm 1;
BA_ "GenSigAutoGenSnd" SG_ 2565351182 GrpFunctValAck 0;
BA_ "GenSigAutoGenDsp" SG_ 2565351182 GrpFunctValAck 0;
BA_ "CI_RepetitionComplemented" SG_ 2565351182 GrpFunctValAck 2;
BA_ "CI_FullName" SG_ 2565351182 GrpFunctValAck "Group Function Value (ACK)";
BA_ "CI_ParId" SG_ 2565351182 GrpFunctValAck "ESMD_02063";
BA_ "SPN" SG_ 2565351182 GrpFunctValAck 2542;
BA_ "SigType" SG_ 2565351182 GrpFunctValAck 1;
BA_ "CI_FullName" SG_ 2565351182 PGN_RQST2_0E_27 "Parameter Group Number (RQST2)";
BA_ "CI_ParId" SG_ 2565351182 PGN_RQST2_0E_27 "ESMD_20977";
BA_ "SPN" SG_ 2565351182 PGN_RQST2_0E_27 2574;
BA_ "SigType" SG_ 2565351182 PGN_RQST2_0E_27 6;
BA_ "GenSigAutoGenSnd" SG_ 2565351171 AddrNegAck 0;
BA_ "GenSigAutoGenDsp" SG_ 2565351171 AddrNegAck 0;
BA_ "CI_FullName" SG_ 2565351171 AddrNegAck "Address Negative Acknowledgement";
BA_ "CI_ParId" SG_ 2565351171 AddrNegAck "ESMD_00044";
BA_ "SPN" SG_ 2565351171 AddrNegAck 3291;
BA_ "GenSigAutoGenSnd" SG_ 2565351171 AddrBusy 0;
BA_ "GenSigAutoGenDsp" SG_ 2565351171 AddrBusy 0;
BA_ "CI_FullName" SG_ 2565351171 AddrBusy "Address Busy";
BA_ "CI_ParId" SG_ 2565351171 AddrBusy "ESMD_00043";
BA_ "SPN" SG_ 2565351171 AddrBusy 3293;
BA_ "GenSigAutoGenSnd" SG_ 2565351171 AddrAck 0;
BA_ "GenSigAutoGenDsp" SG_ 2565351171 AddrAck 0;
BA_ "CI_FullName" SG_ 2565351171 AddrAck "Address Acknowledged";
BA_ "CI_ParId" SG_ 2565351171 AddrAck "ESMD_00041";
BA_ "SPN" SG_ 2565351171 AddrAck 3290;
BA_ "GenSigAutoGenSnd" SG_ 2565351171 AddrAccssDeny 0;
BA_ "GenSigAutoGenDsp" SG_ 2565351171 AddrAccssDeny 0;
BA_ "CI_FullName" SG_ 2565351171 AddrAccssDeny "Address Access Denied";
BA_ "CI_ParId" SG_ 2565351171 AddrAccssDeny "ESMD_00040";
BA_ "SPN" SG_ 2565351171 AddrAccssDeny 3292;
BA_ "GenSigAutoGenSnd" SG_ 2565351171 GrpFunctValAck 0;
BA_ "GenSigAutoGenDsp" SG_ 2565351171 GrpFunctValAck 0;
BA_ "CI_RepetitionComplemented" SG_ 2565351171 GrpFunctValAck 2;
BA_ "CI_FullName" SG_ 2565351171 GrpFunctValAck "Group Function Value (ACK)";
BA_ "CI_ParId" SG_ 2565351171 GrpFunctValAck "ESMD_02063";
BA_ "SPN" SG_ 2565351171 GrpFunctValAck 2542;
BA_ "SigType" SG_ 2565351171 GrpFunctValAck 1;
BA_ "CI_FullName" SG_ 2565351171 PGN_RQST2_03_27 "Parameter Group Number (RQST2)";
BA_ "CI_ParId" SG_ 2565351171 PGN_RQST2_03_27 "ESMD_20974";
BA_ "SPN" SG_ 2565351171 PGN_RQST2_03_27 2574;
BA_ "SigType" SG_ 2565351171 PGN_RQST2_03_27 6;
BA_ "GenSigAutoGenSnd" SG_ 2565351171 CByteAckm 0;
BA_ "GenSigAutoGenDsp" SG_ 2565351171 CByteAckm 0;
BA_ "CI_FullName" SG_ 2565351171 CByteAckm "Control Byte (ACKM)";
BA_ "CI_ParId" SG_ 2565351171 CByteAckm "ESMD_00942";
BA_ "SPN" SG_ 2565351171 CByteAckm 2541;
BA_ "SigType" SG_ 2565351171 CByteAckm 1;
BA_ "CI_RepetitionNum" SG_ 2566888195 GearMapAv 1;
BA_ "CI_RepetitionType" SG_ 2566888195 GearMapAv 3;
BA_ "CI_FullName" SG_ 2566888195 GearMapAv "Gear Map Available";
BA_ "CI_ParId" SG_ 2566888195 GearMapAv "ESMD_23606";
BA_ "CI_SLOT_Name" SG_ 2566888195 GearMapAv "SAEbm64";
BA_ "SPN" SG_ 2566888195 GearMapAv 518735;
BA_ "CI_FullName" SG_ 2566871043 AxId "Axle Identification";
BA_ "CI_ParId" SG_ 2566871043 AxId "ESMD_26109";
BA_ "CI_SLOT_Name" SG_ 2566871043 AxId "SAEbs08";
BA_ "SPN" SG_ 2566871043 AxId 517646;
BA_ "GenSigAutoGenSnd" SG_ 2499798019 Hrtbt 0;
BA_ "GenSigAutoGenDsp" SG_ 2499798019 Hrtbt 0;
BA_ "CI_RepetitionNum" SG_ 2499798019 Hrtbt 1;
BA_ "CI_RepetitionType" SG_ 2499798019 Hrtbt 3;
BA_ "CI_RepetitionComplemented" SG_ 2499798019 Hrtbt 2;
BA_ "CI_FullName" SG_ 2499798019 Hrtbt "Heartbeat";
BA_ "CI_ParId" SG_ 2499798019 Hrtbt "ESMD_20033";
BA_ "CI_SLOT_Name" SG_ 2499798019 Hrtbt "SAEct03";
BA_ "GenSigStartValue" SG_ 2499798019 Hrtbt 251;
BA_ "SPN" SG_ 2499798019 Hrtbt 518020;
BA_ "GenSigAutoGenSnd" SG_ 2499798019 MsgChksum_4 0;
BA_ "GenSigAutoGenDsp" SG_ 2499798019 MsgChksum_4 0;
BA_ "CI_RepetitionNum" SG_ 2499798019 MsgChksum_4 1;
BA_ "CI_RepetitionType" SG_ 2499798019 MsgChksum_4 3;
BA_ "CI_RepetitionComplemented" SG_ 2499798019 MsgChksum_4 2;
BA_ "CI_FullName" SG_ 2499798019 MsgChksum_4 "Message Checksum 4";
BA_ "CI_ParId" SG_ 2499798019 MsgChksum_4 "ESMD_22124";
BA_ "CI_SLOT_Name" SG_ 2499798019 MsgChksum_4 "SAEct08";
BA_ "GenSigStartValue" SG_ 2499798019 MsgChksum_4 15;
BA_ "SPN" SG_ 2499798019 MsgChksum_4 518268;
BA_ "CI_FullName" SG_ 2499798019 SpecialModeResp "Special Mode Response";
BA_ "CI_ParId" SG_ 2499798019 SpecialModeResp "ESMD_20020";
BA_ "CI_SLOT_Name" SG_ 2499798019 SpecialModeResp "";
BA_ "GenSigStartValue" SG_ 2499798019 SpecialModeResp 1;
BA_ "SPN" SG_ 2499798019 SpecialModeResp 522813;
BA_ "CI_FullName" SG_ 2499798019 SpecialModeReq "Special Mode Request";
BA_ "CI_ParId" SG_ 2499798019 SpecialModeReq "ESMD_20019";
BA_ "GenSigStartValue" SG_ 2499798019 SpecialModeReq 7;
BA_ "SPN" SG_ 2499798019 SpecialModeReq 522812;
BA_ "CI_FullName" SG_ 2499798019 ThisNetReq "This Net Request";
BA_ "CI_ParId" SG_ 2499798019 ThisNetReq "ESMD_22066";
BA_ "CI_SLOT_Name" SG_ 2499798019 ThisNetReq "SAEbs02";
BA_ "SPN" SG_ 2499798019 ThisNetReq 518162;
BA_ "CI_FullName" SG_ 2499798019 BattMainSwHoldReq "Battery Main Switch Hold Request";
BA_ "CI_ParId" SG_ 2499798019 BattMainSwHoldReq "ESMD_00776";
BA_ "CI_SLOT_Name" SG_ 2499798019 BattMainSwHoldReq "SAEbs02";
BA_ "SPN" SG_ 2499798019 BattMainSwHoldReq 1682;
BA_ "CI_FullName" SG_ 2499798019 KeyPositn "Key Position";
BA_ "CI_ParId" SG_ 2499798019 KeyPositn "ESMD_22053";
BA_ "CI_SLOT_Name" SG_ 2499798019 KeyPositn "SAEbs08";
BA_ "GenSigStartValue" SG_ 2499798019 KeyPositn 255;
BA_ "SPN" SG_ 2499798019 KeyPositn 518023;
BA_ "CI_FullName" SG_ 2499798019 BattMainSwHoldFunct "Battery Main Switch Hold Function";
BA_ "CI_ParId" SG_ 2499798019 BattMainSwHoldFunct "ESMD_22054";
BA_ "CI_SLOT_Name" SG_ 2499798019 BattMainSwHoldFunct "SAEbs04";
BA_ "GenSigStartValue" SG_ 2499798019 BattMainSwHoldFunct 15;
BA_ "SPN" SG_ 2499798019 BattMainSwHoldFunct 518160;
BA_ "CI_RepetitionNum" SG_ 2499798019 OpSeatSw 1;
BA_ "CI_RepetitionType" SG_ 2499798019 OpSeatSw 3;
BA_ "CI_FullName" SG_ 2499798019 OpSeatSw "Operator Seat Switch";
BA_ "CI_ParId" SG_ 2499798019 OpSeatSw "ESMD_03848";
BA_ "CI_SLOT_Name" SG_ 2499798019 OpSeatSw "SAEbs02";
BA_ "GenSigStartValue" SG_ 2499798019 OpSeatSw 3;
BA_ "SPN" SG_ 2499798019 OpSeatSw 1504;
BA_ "CI_FullName" SG_ 2499798019 AutoGuideEnaSts "Auto Guidance Enable Status";
BA_ "CI_ParId" SG_ 2499798019 AutoGuideEnaSts "ESMD_20027";
BA_ "CI_SLOT_Name" SG_ 2499798019 AutoGuideEnaSts "SAEbs02";
BA_ "GenSigStartValue" SG_ 2499798019 AutoGuideEnaSts 3;
BA_ "SPN" SG_ 2499798019 AutoGuideEnaSts 517677;
BA_ "CI_FullName" SG_ 2499798019 WakeUpInDozeMode "Wake Up In Doze Mode";
BA_ "CI_ParId" SG_ 2499798019 WakeUpInDozeMode "ESMD_20038";
BA_ "CI_SLOT_Name" SG_ 2499798019 WakeUpInDozeMode "SAEbs02";
BA_ "GenSigStartValue" SG_ 2499798019 WakeUpInDozeMode 3;
BA_ "SPN" SG_ 2499798019 WakeUpInDozeMode 517674;
BA_ "CI_FullName" SG_ 2499798019 WakeUpFunct "Wake Up Function";
BA_ "CI_ParId" SG_ 2499798019 WakeUpFunct "ESMD_20040";
BA_ "CI_SLOT_Name" SG_ 2499798019 WakeUpFunct "SAEbs04";
BA_ "GenSigStartValue" SG_ 2499798019 WakeUpFunct 15;
BA_ "SPN" SG_ 2499798019 WakeUpFunct 518024;
BA_ "CI_FullName" SG_ 2499798019 VehMov "Vehicle moving";
BA_ "CI_ParId" SG_ 2499798019 VehMov "ESMD_20043";
BA_ "CI_SLOT_Name" SG_ 2499798019 VehMov "SAEbs02";
BA_ "GenSigStartValue" SG_ 2499798019 VehMov 3;
BA_ "SPN" SG_ 2499798019 VehMov 517669;
BA_ "CI_FullName" SG_ 2499798019 KeySwNotOFF "Key Switch NOT OFF";
BA_ "CI_ParId" SG_ 2499798019 KeySwNotOFF "ESMD_08769";
BA_ "CI_SLOT_Name" SG_ 2499798019 KeySwNotOFF "SAEbs02";
BA_ "GenSigStartValue" SG_ 2499798019 KeySwNotOFF 3;
BA_ "SPN" SG_ 2499798019 KeySwNotOFF 1865;
BA_ "CI_FullName" SG_ 2499798019 IgnON "Ignition On";
BA_ "CI_ParId" SG_ 2499798019 IgnON "ESMD_20039";
BA_ "CI_SLOT_Name" SG_ 2499798019 IgnON "SAEbs02";
BA_ "GenSigStartValue" SG_ 2499798019 IgnON 3;
BA_ "SPN" SG_ 2499798019 IgnON 518022;
BA_ "GenSigAutoGenSnd" SG_ 2499798019 EngStartSts 0;
BA_ "GenSigAutoGenDsp" SG_ 2499798019 EngStartSts 0;
BA_ "CI_RepetitionComplemented" SG_ 2499798019 EngStartSts 2;
BA_ "CI_FullName" SG_ 2499798019 EngStartSts "Engine Starter Status";
BA_ "CI_ParId" SG_ 2499798019 EngStartSts "ESMD_20041";
BA_ "CI_SLOT_Name" SG_ 2499798019 EngStartSts "SAEbs02";
BA_ "GenSigStartValue" SG_ 2499798019 EngStartSts 3;
BA_ "SPN" SG_ 2499798019 EngStartSts 518021;
BA_ "GenSigAutoGenSnd" SG_ 2499798019 CByteNetManage 0;
BA_ "GenSigAutoGenDsp" SG_ 2499798019 CByteNetManage 0;
BA_ "CI_RepetitionComplemented" SG_ 2499798019 CByteNetManage 2;
BA_ "CI_FullName" SG_ 2499798019 CByteNetManage "Control Byte Network Management";
BA_ "CI_ParId" SG_ 2499798019 CByteNetManage "ESMD_20028";
BA_ "CI_SLOT_Name" SG_ 2499798019 CByteNetManage "SAEbs02";
BA_ "GenSigStartValue" SG_ 2499798019 CByteNetManage 3;
BA_ "SPN" SG_ 2499798019 CByteNetManage 517676;
BA_ "GenSigAutoGenSnd" SG_ 2499798019 EngRun 0;
BA_ "GenSigAutoGenDsp" SG_ 2499798019 EngRun 0;
BA_ "CI_RepetitionComplemented" SG_ 2499798019 EngRun 2;
BA_ "CI_FullName" SG_ 2499798019 EngRun "Engine Running";
BA_ "CI_ParId" SG_ 2499798019 EngRun "ESMD_20042";
BA_ "CI_SLOT_Name" SG_ 2499798019 EngRun "SAEbs02";
BA_ "GenSigStartValue" SG_ 2499798019 EngRun 3;
BA_ "SPN" SG_ 2499798019 EngRun 517670;
BA_ "CI_FullName" SG_ 2499798019 EmergEngOff_ReqSts "Emergency engine OFF request status";
BA_ "CI_ParId" SG_ 2499798019 EmergEngOff_ReqSts "ESMD_23514";
BA_ "CI_SLOT_Name" SG_ 2499798019 EmergEngOff_ReqSts "SAEbs01";
BA_ "SPN" SG_ 2499798019 EmergEngOff_ReqSts 520095;
BA_ "CI_FullName" SG_ 2499798019 MasterDisconnSwSts "Master Disconnect switch status";
BA_ "CI_ParId" SG_ 2499798019 MasterDisconnSwSts "ESMD_23513";
BA_ "CI_SLOT_Name" SG_ 2499798019 MasterDisconnSwSts "SAEbs01";
BA_ "SPN" SG_ 2499798019 MasterDisconnSwSts 520094;
BA_ "CI_FullName" SG_ 2565799819 Rsrvd_1Bit "Reserved 1 Bit";
BA_ "CI_ParId" SG_ 2565799819 Rsrvd_1Bit "ESMD_23062";
BA_ "GenSigAutoGenSnd" SG_ 2565799819 VehSys 0;
BA_ "GenSigAutoGenDsp" SG_ 2565799819 VehSys 0;
BA_ "CI_RepetitionComplemented" SG_ 2565799819 VehSys 2;
BA_ "CI_FullName" SG_ 2565799819 VehSys "Vehicle system";
BA_ "CI_ParId" SG_ 2565799819 VehSys "ESMD_16375";
BA_ "SPN" SG_ 2565799819 VehSys 2842;
BA_ "GenSigAutoGenSnd" SG_ 2565799819 VehSysInst 0;
BA_ "GenSigAutoGenDsp" SG_ 2565799819 VehSysInst 0;
BA_ "CI_RepetitionComplemented" SG_ 2565799819 VehSysInst 2;
BA_ "CI_FullName" SG_ 2565799819 VehSysInst "Vehicle System Instance";
BA_ "CI_ParId" SG_ 2565799819 VehSysInst "ESMD_09571";
BA_ "SPN" SG_ 2565799819 VehSysInst 2843;
BA_ "GenSigAutoGenSnd" SG_ 2565799819 ManufctCod 0;
BA_ "GenSigAutoGenDsp" SG_ 2565799819 ManufctCod 0;
BA_ "CI_RepetitionComplemented" SG_ 2565799819 ManufctCod 2;
BA_ "CI_FullName" SG_ 2565799819 ManufctCod "Manufacturer Code";
BA_ "CI_ParId" SG_ 2565799819 ManufctCod "ESMD_08852";
BA_ "SPN" SG_ 2565799819 ManufctCod 2838;
BA_ "SigType" SG_ 2565799819 ManufctCod 1;
BA_ "GenSigAutoGenSnd" SG_ 2565799819 IndstryGrp 0;
BA_ "GenSigAutoGenDsp" SG_ 2565799819 IndstryGrp 0;
BA_ "CI_RepetitionComplemented" SG_ 2565799819 IndstryGrp 2;
BA_ "CI_FullName" SG_ 2565799819 IndstryGrp "Industry Group";
BA_ "CI_ParId" SG_ 2565799819 IndstryGrp "ESMD_02136";
BA_ "SPN" SG_ 2565799819 IndstryGrp 2846;
BA_ "GenSigAutoGenSnd" SG_ 2565799819 IdNum 0;
BA_ "GenSigAutoGenDsp" SG_ 2565799819 IdNum 0;
BA_ "CI_RepetitionComplemented" SG_ 2565799819 IdNum 2;
BA_ "CI_FullName" SG_ 2565799819 IdNum "Identity Number";
BA_ "CI_ParId" SG_ 2565799819 IdNum "ESMD_08726";
BA_ "SPN" SG_ 2565799819 IdNum 2837;
BA_ "GenSigAutoGenSnd" SG_ 2565799819 FunctInst 0;
BA_ "GenSigAutoGenDsp" SG_ 2565799819 FunctInst 0;
BA_ "CI_RepetitionComplemented" SG_ 2565799819 FunctInst 2;
BA_ "CI_FullName" SG_ 2565799819 FunctInst "Function Instance";
BA_ "CI_ParId" SG_ 2565799819 FunctInst "ESMD_08670";
BA_ "SPN" SG_ 2565799819 FunctInst 2839;
BA_ "GenSigAutoGenSnd" SG_ 2565799819 Funct 0;
BA_ "GenSigAutoGenDsp" SG_ 2565799819 Funct 0;
BA_ "CI_RepetitionComplemented" SG_ 2565799819 Funct 2;
BA_ "CI_FullName" SG_ 2565799819 Funct "Function";
BA_ "CI_ParId" SG_ 2565799819 Funct "ESMD_08663";
BA_ "SPN" SG_ 2565799819 Funct 2841;
BA_ "GenSigAutoGenSnd" SG_ 2565799819 ECU_Inst 0;
BA_ "GenSigAutoGenDsp" SG_ 2565799819 ECU_Inst 0;
BA_ "CI_RepetitionComplemented" SG_ 2565799819 ECU_Inst 2;
BA_ "CI_FullName" SG_ 2565799819 ECU_Inst "ECU Instance";
BA_ "CI_ParId" SG_ 2565799819 ECU_Inst "ESMD_08387";
BA_ "SPN" SG_ 2565799819 ECU_Inst 2840;
BA_ "GenSigAutoGenSnd" SG_ 2565799819 ArbAddrCap 0;
BA_ "GenSigAutoGenDsp" SG_ 2565799819 ArbAddrCap 0;
BA_ "CI_RepetitionComplemented" SG_ 2565799819 ArbAddrCap 2;
BA_ "CI_FullName" SG_ 2565799819 ArbAddrCap "Arbitrary Address Capable";
BA_ "CI_ParId" SG_ 2565799819 ArbAddrCap "ESMD_08115";
BA_ "SPN" SG_ 2565799819 ArbAddrCap 2844;
BA_ "GenSigAutoGenSnd" SG_ 2565406603 AddrAccssDeny 0;
BA_ "GenSigAutoGenDsp" SG_ 2565406603 AddrAccssDeny 0;
BA_ "CI_FullName" SG_ 2565406603 AddrAccssDeny "Address Access Denied";
BA_ "CI_ParId" SG_ 2565406603 AddrAccssDeny "ESMD_00040";
BA_ "SPN" SG_ 2565406603 AddrAccssDeny 3292;
BA_ "GenSigAutoGenSnd" SG_ 2565406603 AddrAck 0;
BA_ "GenSigAutoGenDsp" SG_ 2565406603 AddrAck 0;
BA_ "CI_FullName" SG_ 2565406603 AddrAck "Address Acknowledged";
BA_ "CI_ParId" SG_ 2565406603 AddrAck "ESMD_00041";
BA_ "SPN" SG_ 2565406603 AddrAck 3290;
BA_ "GenSigAutoGenSnd" SG_ 2565406603 AddrBusy 0;
BA_ "GenSigAutoGenDsp" SG_ 2565406603 AddrBusy 0;
BA_ "CI_FullName" SG_ 2565406603 AddrBusy "Address Busy";
BA_ "CI_ParId" SG_ 2565406603 AddrBusy "ESMD_00043";
BA_ "SPN" SG_ 2565406603 AddrBusy 3293;
BA_ "GenSigAutoGenSnd" SG_ 2565406603 AddrNegAck 0;
BA_ "GenSigAutoGenDsp" SG_ 2565406603 AddrNegAck 0;
BA_ "CI_FullName" SG_ 2565406603 AddrNegAck "Address Negative Acknowledgement";
BA_ "CI_ParId" SG_ 2565406603 AddrNegAck "ESMD_00044";
BA_ "SPN" SG_ 2565406603 AddrNegAck 3291;
BA_ "GenSigAutoGenSnd" SG_ 2565406603 CByteAckm 0;
BA_ "GenSigAutoGenDsp" SG_ 2565406603 CByteAckm 0;
BA_ "CI_FullName" SG_ 2565406603 CByteAckm "Control Byte (ACKM)";
BA_ "CI_ParId" SG_ 2565406603 CByteAckm "ESMD_00942";
BA_ "SPN" SG_ 2565406603 CByteAckm 2541;
BA_ "SigType" SG_ 2565406603 CByteAckm 1;
BA_ "GenSigAutoGenSnd" SG_ 2565406603 GrpFunctValAck 0;
BA_ "GenSigAutoGenDsp" SG_ 2565406603 GrpFunctValAck 0;
BA_ "CI_RepetitionComplemented" SG_ 2565406603 GrpFunctValAck 2;
BA_ "CI_FullName" SG_ 2565406603 GrpFunctValAck "Group Function Value (ACK)";
BA_ "CI_ParId" SG_ 2565406603 GrpFunctValAck "ESMD_02063";
BA_ "SPN" SG_ 2565406603 GrpFunctValAck 2542;
BA_ "SigType" SG_ 2565406603 GrpFunctValAck 1;
BA_ "CI_FullName" SG_ 2565406603 PGN_RQST2_EHR "Parameter Group Number (RQST2)";
BA_ "CI_ParId" SG_ 2565406603 PGN_RQST2_EHR "ESMD_20954";
BA_ "SPN" SG_ 2565406603 PGN_RQST2_EHR 2574;
BA_ "SigType" SG_ 2565406603 PGN_RQST2_EHR 6;
BA_ "CI_ParId" SG_ 2499777575 CalibrOngoing "NWD_1460";
BA_ "CI_SLOT_Name" SG_ 2499777575 CalibrOngoing "SAEbs02";
BA_ "SPN" SG_ 2499777575 CalibrOngoing 522186;
BA_ "CI_FullName" SG_ 2499777575 CalibrStart "Calibration Start";
BA_ "CI_ParId" SG_ 2499777575 CalibrStart "ESMD_23605";
BA_ "CI_SLOT_Name" SG_ 2499777575 CalibrStart "SAEbs02";
BA_ "SPN" SG_ 2499777575 CalibrStart 518958;
BA_ "CI_FullName" SG_ 2499777575 CalibrModeEna "Calibration Mode Enable";
BA_ "CI_ParId" SG_ 2499777575 CalibrModeEna "ESMD_23602";
BA_ "CI_SLOT_Name" SG_ 2499777575 CalibrModeEna "SAEbs02";
BA_ "SPN" SG_ 2499777575 CalibrModeEna 518959;
BA_ "CI_RepetitionNum" SG_ 2499777575 WhRevolSpdLim 1;
BA_ "CI_RepetitionType" SG_ 2499777575 WhRevolSpdLim 3;
BA_ "CI_FullName" SG_ 2499777575 WhRevolSpdLim "Wheel Revolution Speed Limitation";
BA_ "CI_ParId" SG_ 2499777575 WhRevolSpdLim "ESMD_21679";
BA_ "CI_SLOT_Name" SG_ 2499777575 WhRevolSpdLim "SAEvr01";
BA_ "SPN" SG_ 2499777575 WhRevolSpdLim 518694;
BA_ "CI_RepetitionNum" SG_ 2499777575 SelAggrsvns 1;
BA_ "CI_RepetitionType" SG_ 2499777575 SelAggrsvns 3;
BA_ "CI_FullName" SG_ 2499777575 SelAggrsvns "Selected aggressiveness";
BA_ "CI_ParId" SG_ 2499777575 SelAggrsvns "ESMD_20013";
BA_ "CI_SLOT_Name" SG_ 2499777575 SelAggrsvns "SAEpc03";
BA_ "SPN" SG_ 2499777575 SelAggrsvns 517660;
BA_ "CI_RepetitionNum" SG_ 2499777575 GearRngMin 1;
BA_ "CI_RepetitionType" SG_ 2499777575 GearRngMin 3;
BA_ "CI_FullName" SG_ 2499777575 GearRngMin "Gear Range Min";
BA_ "CI_ParId" SG_ 2499777575 GearRngMin "ESMD_20030";
BA_ "CI_SLOT_Name" SG_ 2499777575 GearRngMin "SAEgv01";
BA_ "SPN" SG_ 2499777575 GearRngMin 517648;
BA_ "CI_RepetitionNum" SG_ 2499777575 GearRngMax 1;
BA_ "CI_RepetitionType" SG_ 2499777575 GearRngMax 3;
BA_ "CI_FullName" SG_ 2499777575 GearRngMax "Gear Range Max";
BA_ "CI_ParId" SG_ 2499777575 GearRngMax "ESMD_20029";
BA_ "CI_SLOT_Name" SG_ 2499777575 GearRngMax "SAEgv01";
BA_ "SPN" SG_ 2499777575 GearRngMax 517647;
BA_ "CI_RepetitionNum" SG_ 2499777575 RPTO_BrakeRleasCmd 1;
BA_ "CI_RepetitionType" SG_ 2499777575 RPTO_BrakeRleasCmd 3;
BA_ "CI_FullName" SG_ 2499777575 RPTO_BrakeRleasCmd "RPTO Brake Release Command";
BA_ "CI_ParId" SG_ 2499777575 RPTO_BrakeRleasCmd "ESMD_20035";
BA_ "CI_SLOT_Name" SG_ 2499777575 RPTO_BrakeRleasCmd "SAEbs02";
BA_ "SPN" SG_ 2499777575 RPTO_BrakeRleasCmd 517659;
BA_ "CI_RepetitionNum" SG_ 2499777575 RPTO_SpdRatioCmd 1;
BA_ "CI_RepetitionType" SG_ 2499777575 RPTO_SpdRatioCmd 3;
BA_ "CI_FullName" SG_ 2499777575 RPTO_SpdRatioCmd "RPTO Speed Ratio Command";
BA_ "CI_ParId" SG_ 2499777575 RPTO_SpdRatioCmd "ESMD_23622";
BA_ "CI_SLOT_Name" SG_ 2499777575 RPTO_SpdRatioCmd "SAEbs03";
BA_ "SPN" SG_ 2499777575 RPTO_SpdRatioCmd 518643;
BA_ "CI_RepetitionNum" SG_ 2499777575 RPTO_EngagCmd 1;
BA_ "CI_RepetitionType" SG_ 2499777575 RPTO_EngagCmd 3;
BA_ "CI_FullName" SG_ 2499777575 RPTO_EngagCmd "Rear Power Take Off Engagement Command";
BA_ "CI_ParId" SG_ 2499777575 RPTO_EngagCmd "ESMD_09090";
BA_ "SPN" SG_ 2499777575 RPTO_EngagCmd 1894;
BA_ "CI_RepetitionNum" SG_ 2499777575 RPTO_AggrsvnsCmd 1;
BA_ "CI_RepetitionType" SG_ 2499777575 RPTO_AggrsvnsCmd 3;
BA_ "CI_FullName" SG_ 2499777575 RPTO_AggrsvnsCmd "RPTO Aggressiveness Command";
BA_ "CI_ParId" SG_ 2499777575 RPTO_AggrsvnsCmd "ESMD_20417";
BA_ "CI_SLOT_Name" SG_ 2499777575 RPTO_AggrsvnsCmd "SAEbs03";
BA_ "SPN" SG_ 2499777575 RPTO_AggrsvnsCmd 518344;
BA_ "CI_RepetitionNum" SG_ 2499777575 TransmReqGear_2 1;
BA_ "CI_RepetitionType" SG_ 2499777575 TransmReqGear_2 3;
BA_ "CI_FullName" SG_ 2499777575 TransmReqGear_2 "Transmission Requested Gear 2";
BA_ "CI_ParId" SG_ 2499777575 TransmReqGear_2 "ESMD_20076";
BA_ "CI_SLOT_Name" SG_ 2499777575 TransmReqGear_2 "SAEgv01";
BA_ "SPN" SG_ 2499777575 TransmReqGear_2 517668;
VAL_ 2632777610 CByteTPCM 16 "RTS" 17 "CTS" 19 "EoMA" 32 "BAM" 255 "Abort" ;
VAL_ 2632777610 ConnAbrtReason 1 "AlreadyInConnManagedSession" 2 "NoFreeSystemResources" 3 "Timeout_CloseSession" 4 "UnexpectedDataTransferPacket" 5 "BadSequenceNumber" 6 "DuplicateSequenceNumber" 7 "AnyOtherError" ;
VAL_ 2632777610 PGN_PktMsgTPCM_BAM 255 "NotAvailable" ;
VAL_ 2632777610 PGN_PktMsgTPCM_ConnAbort 255 "NotAvailable" ;
VAL_ 2632777610 PGN_PktMsgTPCM_CTS 255 "NotAvailable" ;
VAL_ 2632777610 PGN_PktMsgTPCM_RTS 255 "NotAvailable" ;
VAL_ 2632777610 PGN_PktMsgTPCM_RTS2 255 "NotAvailable" ;
VAL_ 2566834825 AmbrWarnLmp 2 "flashing" 0 "Lamp off" 1 "Lamp on" 3 "Not available" ;
VAL_ 2566834825 FlashAmbrWarnLmpAWL 0 "Slow Flash" 1 "Fast Flash" 2 "Reserved" 3 "Unavailable / Do Not Flash" ;
VAL_ 2566834825 FlashMIL 0 "Slow Flash" 1 "Fast Flash" 2 "Reserved" 3 "Unavailable / Do Not Flash" ;
VAL_ 2566834825 FlashProtLmp 0 "Slow Flash" 1 "Fast Flash" 2 "Reserved" 3 "Unavailable / Do Not Flash" ;
VAL_ 2566834825 FlashRedStopLmpRSL 0 "Slow Flash" 1 "Fast Flash" 2 "Reserved" 3 "Unavailable / Do Not Flash" ;
VAL_ 2566834825 MIL 0 "Lamp off" 1 "Lamp on" 2 "Reserved" 3 "Not available" ;
VAL_ 2566834825 ProtLmp 0 "Lamp off" 1 "Lamp on" 2 "Reserved" 3 "Not available" ;
VAL_ 2566834825 RedStopLmp 0 "Lamp off" 1 "Lamp on" 3 "Not available" ;
VAL_ 2566834826 AmbrWarnLmp 2 "flashing" 0 "Lamp off" 1 "Lamp on" 3 "Not available" ;
VAL_ 2566834826 FlashAmbrWarnLmpAWL 0 "Slow Flash" 1 "Fast Flash" 2 "Reserved" 3 "Unavailable / Do Not Flash" ;
VAL_ 2566834826 FlashMIL 0 "Slow Flash" 1 "Fast Flash" 2 "Reserved" 3 "Unavailable / Do Not Flash" ;
VAL_ 2566834826 FlashProtLmp 0 "Slow Flash" 1 "Fast Flash" 2 "Reserved" 3 "Unavailable / Do Not Flash" ;
VAL_ 2566834826 FlashRedStopLmpRSL 0 "Slow Flash" 1 "Fast Flash" 2 "Reserved" 3 "Unavailable / Do Not Flash" ;
VAL_ 2566834826 MIL 0 "Lamp off" 1 "Lamp on" 2 "Reserved" 3 "Not available" ;
VAL_ 2566834826 ProtLmp 0 "Lamp off" 1 "Lamp on" 2 "Reserved" 3 "Not available" ;
VAL_ 2566834826 RedStopLmp 0 "Lamp off" 1 "Lamp on" 3 "Not available" ;
VAL_ 2566834831 ProtLmp 0 "Lamp off" 1 "Lamp on" 2 "Reserved" 3 "Not available" ;
VAL_ 2566834831 RedStopLmp 0 "Lamp off" 1 "Lamp on" 3 "Not available" ;
VAL_ 2566834831 AmbrWarnLmp 2 "flashing" 0 "Lamp off" 1 "Lamp on" 3 "Not available" ;
VAL_ 2566834831 MIL 0 "Lamp off" 1 "Lamp on" 2 "Reserved" 3 "Not available" ;
VAL_ 2566834831 FlashAmbrWarnLmpAWL 0 "Slow Flash" 1 "Fast Flash" 2 "Reserved" 3 "Unavailable / Do Not Flash" ;
VAL_ 2566834831 FlashMIL 0 "Slow Flash" 1 "Fast Flash" 2 "Reserved" 3 "Unavailable / Do Not Flash" ;
VAL_ 2566834831 FlashProtLmp 0 "Slow Flash" 1 "Fast Flash" 2 "Reserved" 3 "Unavailable / Do Not Flash" ;
VAL_ 2566834831 FlashRedStopLmpRSL 0 "Slow Flash" 1 "Fast Flash" 2 "Reserved" 3 "Unavailable / Do Not Flash" ;
VAL_ 2632712075 SN_TPDT 255 "NoSequenceAvailable" ;
VAL_ 2632777611 CByteTPCM 16 "RTS" 17 "CTS" 19 "EoMA" 32 "BAM" 255 "Abort" ;
VAL_ 2632777611 ConnAbrtReason 1 "AlreadyInConnManagedSession" 2 "NoFreeSystemResources" 3 "Timeout_CloseSession" 4 "UnexpectedDataTransferPacket" 5 "BadSequenceNumber" 6 "DuplicateSequenceNumber" 7 "AnyOtherError" ;
VAL_ 2632777611 PGN_PktMsgTPCM_BAM 255 "NotAvailable" ;
VAL_ 2632777611 PGN_PktMsgTPCM_ConnAbort 255 "NotAvailable" ;
VAL_ 2632777611 PGN_PktMsgTPCM_CTS 255 "NotAvailable" ;
VAL_ 2632777611 PGN_PktMsgTPCM_RTS 255 "NotAvailable" ;
VAL_ 2632777611 PGN_PktMsgTPCM_RTS2 255 "NotAvailable" ;
VAL_ 2566871842 EHR_CntrlSts 0 "Block / Neutral" 1 "Extend" 2 "Retract" 3 "Float / open centre" 14 "Reserved" 15 "Don't care" ;
VAL_ 2566871842 EHR_CrvGrad 255 "Error" ;
VAL_ 2566871842 EHR_CrvShp 0 "Curve Shape 0h" 1 "Curve Shape 1h" 2 "Curve Shape 2h" 3 "Curve Shape 3h" 4 "Curve Shape 4h" 5 "Curve Shape 5h" 6 "Curve Shape 6h" 7 "Curve Shape 7h" 8 "Curve Shape 8h" 9 "Curve Shape 9h" 10 "Curve Shape Ah" 11 "Curve Shape Bh" 12 "Curve Shape Ch" 13 "Curve Shape Dh" 14 "Curve Shape Eh" 15 "Curve Shape Fh" ;
VAL_ 2566871842 EHR_DynRmpTime 255 "N/A" ;
VAL_ 2566871842 EHR_EvFlow 255 "N/A" ;
VAL_ 2566871842 EHR_EvTemp 255 "Error" ;
VAL_ 2566871842 EHR_FailSafe 0 "Neutral" 1 "Float" 2 "Reserved" 3 "Don't care" ;
VAL_ 2566871842 EHR_Init 3 "Reserved" 2 "Reserved" 1 "Cranking" 0 "Operation" ;
VAL_ 2566871842 EHR_Op_1 0 "Calibration active" 1 "Reserved" 2 "Error" 3 "Normal Operation" ;
VAL_ 2566871842 EHR_Op_2 2 "Reserved" 1 "Reserved" 0 "Goto Fialsafe" 3 "Normal Operation" ;
VAL_ 2564487563 ProtocCntrlInfo 0 "Single frame" 1 "First frame" 2 "Consecutive frame" 3 "Flow control " ;
VAL_ 2564487563 FlowSts 0 "Continue To Send" 1 "Wait " 2 "Overflow" ;
VAL_ 2566854795 FailSvng 3 "Do Not Care" 2 "Error Indication" 1 "Float" 0 "Neutral" ;
VAL_ 2566854795 OpMode 15 "Do Not Care" 14 "Error Indication" 3 "Float/Open Centre" 2 "Retract" 1 "Extend" 0 "Blocked/Neutral" ;
VAL_ 2566866059 EHR_ParamStsByte_3 244 "Check status (PTO uses)" 103 "RoundingOfTheTimeRamp" 80 "ReadChecksumOfApplicationSw" ;
VAL_ 2566866059 EHR_ParamByte_1 127 "EHR Parameter Status" 59 "EHR Parameter Control" ;
VAL_ 2566865547 EHR_EvTemp 255 "Error" ;
VAL_ 2566865547 EHR_Err 0 "Normal Operation" 1 "Fault State" 2 "Error" 3 "Not Available" ;
VAL_ 2566865547 EHR_InitDiag 0 "Normal Operation" 1 "Initialisation State" 2 "Error" 3 "Not Available" ;
VAL_ 2566865547 EHR_ErrCod 69 "InternalComponentFailureSevere" 68 "InternalComponentFailureCritical" 61 "Open center position not reached" 59 "Invalid command message" 58 "Command message timeout" 54 "Address claim conflict" 48 "Spool not in neutral at power on" 47 "Open center position not reached" 46 "Spool stuck out of neutral" 44 "Actuator temp above upper limit" 5 "Supply voltage below limit" 4 "Supply voltage above limit" 0 "Initialization failure" 131 "Checksum failure" 23 "No neutral command at power on" 20 "Valve spool not calibrated" 130 "Spool not in neutral at power on" 129 "Spool not responding to commands" 67 "InternalComponentFailureWarning" 66 "D:No neutral cmd, T:intrnl fail" 65 "Supply voltage above limit" 50 "Supply voltage above limit" 49 "Low volts, D: Position error" 38 "Manual operation" 37 "Open center position not reached" 36 "Spool deflection excessive" 35 "Spool deflection too short" 34 "Supply voltage above limit" 33 "D:Init failure, B:Low volt input" 19 "Implausible CAN control message" 17 "No CAN control message received" 22 "EEPROM failure" ;
VAL_ 2566835083 FlashAmbrWarnLmpAWL 0 "Slow Flash" 1 "Fast Flash" 2 "Reserved" 3 "Unavailable / Do Not Flash" ;
VAL_ 2566835083 FlashMIL 0 "Slow Flash" 1 "Fast Flash" 2 "Reserved" 3 "Unavailable / Do Not Flash" ;
VAL_ 2566835083 FlashProtLmp 0 "Slow Flash" 1 "Fast Flash" 2 "Reserved" 3 "Unavailable / Do Not Flash" ;
VAL_ 2566835083 FlashRedStopLmpRSL 0 "Slow Flash" 1 "Fast Flash" 2 "Reserved" 3 "Unavailable / Do Not Flash" ;
VAL_ 2566835083 ProtLmp 0 "Lamp off" 1 "Lamp on" 2 "Reserved" 3 "Not available" ;
VAL_ 2566835083 AmbrWarnLmp 2 "flashing" 0 "Lamp off" 1 "Lamp on" 3 "Not available" ;
VAL_ 2566835083 RedStopLmp 0 "Lamp off" 1 "Lamp on" 3 "Not available" ;
VAL_ 2566835083 MIL 0 "Lamp off" 1 "Lamp on" 2 "Reserved" 3 "Not available" ;
VAL_ 2566834827 ProtLmp 0 "Lamp off" 1 "Lamp on" 2 "Reserved" 3 "Not available" ;
VAL_ 2566834827 RedStopLmp 0 "Lamp off" 1 "Lamp on" 3 "Not available" ;
VAL_ 2566834827 AmbrWarnLmp 2 "flashing" 0 "Lamp off" 1 "Lamp on" 3 "Not available" ;
VAL_ 2566834827 MIL 0 "Lamp off" 1 "Lamp on" 2 "Reserved" 3 "Not available" ;
VAL_ 2566834827 FlashAmbrWarnLmpAWL 0 "Slow Flash" 1 "Fast Flash" 2 "Reserved" 3 "Unavailable / Do Not Flash" ;
VAL_ 2566834827 FlashMIL 0 "Slow Flash" 1 "Fast Flash" 2 "Reserved" 3 "Unavailable / Do Not Flash" ;
VAL_ 2566834827 FlashProtLmp 0 "Slow Flash" 1 "Fast Flash" 2 "Reserved" 3 "Unavailable / Do Not Flash" ;
VAL_ 2566834827 FlashRedStopLmpRSL 0 "Slow Flash" 1 "Fast Flash" 2 "Reserved" 3 "Unavailable / Do Not Flash" ;
VAL_ 2499803431 XPD_CntrlMode 3 "Not Available" 2 "Press control with maximum mode" 1 "Press control with addition mode" 0 "Override disabled-any cntrl cmd" ;
VAL_ 2499803431 XPD_Prio 3 "Low priority-override disabled" 2 "Medium priority" 1 "High priority-doesn't override" 0 "Highest priority-overrides all" ;
VAL_ 2499743527 TrailPBrakeReq 3 "Don't care/Take no action" 2 "Reserved" 1 "ParkBrakeRequested" 0 "ParkBrakeNotRequested" ;
VAL_ 2499743527 SteerBrakeDirect 3 "N/A" 2 "Right" 1 "Left" 0 "None" ;
VAL_ 2499743527 TrailBrakeRleasWarn 3 "Not Available" 2 "Error" 1 "TrailerP_BrakManReleaseActive" 0 "TrailerP_BrakManReleaseNotActive" ;
VAL_ 2499743527 RightBrakeSts 0 "Not pushed" 1 "pushed" 2 "Error" 3 "NA" ;
VAL_ 2499743527 LeftBrakeSts 3 "NA" 2 "Error" 1 "Pushed" 0 "Not pushed" ;
VAL_ 2499743527 BrakePedLckSts 3 "NA" 2 "Error" 1 "Locked" 0 "Unlocked" ;
VAL_ 2499743527 TrailBrakeReq 0 "Don't Brake" 1 "Brake" 2 "Error" 3 "Not available" ;
VAL_ 2499743527 SecBrakeSw 3 "N/A" 2 "Error" 1 "On" 0 "Off" ;
VAL_ 2566857475 KeySts 0 "Not Active" 3 "N/A" 2 "Error" 1 "Active" ;
VAL_ 2566857475 CrankSts 3 "N/A" 2 "Error" 1 "Active" 0 "Not Active" ;
VAL_ 2566857475 DigitDumpSts 3 "N/A" 2 "Error" 1 "Active" 0 "Not Active" ;
VAL_ 2566857475 V_Ref_5VSensSupply_2 7 "N/A" 6 "Error" 5 "Reserved" 4 "QT_NotTraking" 3 "QT_UV" 2 "QT_OV" 1 "QT_STG" 0 "QT_NoError" ;
VAL_ 2566857475 V_Ref_5VSensSupply_1 7 "N/A" 6 "Error" 5 "Reserved" 4 "QT_NotTraking" 3 "QT_UV" 2 "QT_OV" 1 "QT_STG" 0 "QT_NoError" ;
VAL_ 2566857475 SensSupplyV_12V 3 "N/A" 2 "Error" 1 "12V_NotPresent" 0 "12V_Present" ;
VAL_ 2564488958 ProtocCntrlInfo 0 "Single frame" 1 "First frame" 2 "Consecutive frame" 3 "Flow control " ;
VAL_ 2564488958 FlowSts 0 "Continue To Send" 1 "Wait " 2 "Overflow" ;
VAL_ 2565603086 SN_TPDT 255 "NoSequenceAvailable" ;
VAL_ 2499785475 DrvlRecovReq 4 "Operator Neutral Required (N-Ac)" 3 "Cycle Clutch Pedal required" 7 "Not available" 6 "Error" 0 "Transmission Okay" 1 "Transmission Disengaged" 2 "Transmission in Power Zero" ;
VAL_ 2499785475 DrvlItemUnderCalibr 7 "N/A" 6 "Error" 1 "Park Brake" 0 "Transmission" ;
VAL_ 2499785475 RngLckFdbk 3 "N/A" 2 "Error" 1 "Enabled" 0 "Disabled" ;
VAL_ 2499785475 DecelTorq 65535 "N/A" 65024 "Err" ;
VAL_ 2499785475 PTO_AntiPitchFdbk 3 "NA" 2 "Error" 1 "Active" 0 "Not Active" ;
VAL_ 2499785475 TransmDsrdSubmodeFdbk 7 "N/A" 6 "Error" 3 "Road to Field" 2 "Field to Road" 1 "Road" 0 "Field" ;
VAL_ 2566877699 PBrakeTyp 15 "N/A" 14 "Error" 5 "EU SAHR CH26 MR" 4 "NA SAHR 2 (NON MR)" 3 "NA SAHR 1 (NON MR)" 2 "HD SAHR" 1 "EPL" 0 "No Park brake" ;
VAL_ 2566877699 CreeprPresence 3 "N/A" 2 "Error" 1 "Present" 0 "Not Present" ;
VAL_ 2566877699 DifflckTyp 7 "NA" 6 "Error" 5 "Reserved" 4 "Reserved" 3 "Reserved" 2 "Dog Clutch" 1 "Wet Clutch" 0 "No Difflock" ;
VAL_ 2566877699 DrvlTyp 34 "SUB100 Mech PS 12x12" 255 "N/A" 254 "Error" 16 "SWB CVT (2x1)" 0 "Not Defined" 24 "CCH 160 CD FPS LF 21x5" 23 "APH DCT 6 CYL" 22 "APL SH DCT" 21 "18x6 SPS" 20 "APH 16x16" 19 "APL 16x16" 18 "UT Hi-Lo 24x24" 17 "Spe Hi-Lo 24x24" 15 "APL SH CVT 2x1" 14 "APH FPS" 13 "APH CVT" 12 "APH DCT 4 CYL" 11 "CCM LWB FPS (ACM36 FPS)" 10 "CCM LWB CVT (ACM36 CVT)" 9 "CCM HD CVT HD" 8 "CCH MR CVT" 7 "CCH MR FPS" 6 "4WD PS7 FPS" 5 "4WD PS6 FPS" 4 "4WD PS4 FPS" 26 "Spe CVT 2x1 (Specialty CVT)" 25 "Spe PS 16x16" 3 "4WD PS4 JR FPS" 2 "CCH LF CVT" 1 "CCH LF FPS" 33 "SWB CVT 3x1" 32 "SWB DCT" 31 "APH DCT CNG" 30 "SUB100 El PS 12x12" 29 "CCH 160 CD FPS LF 21x5 C2B" 28 "CCM HD FPS DCT 26x26" 27 "CCM LWB Japan (3x1)" ;
VAL_ 2566877699 EPL_Presence 3 "NA" 2 "Error" 1 "Present" 0 "Not Present" ;
VAL_ 2566877699 MFD_Presence 3 "N/A" 2 "Error" 1 "Present" 0 "Not Present" ;
VAL_ 2566877699 OverDrivPresence 3 "NA" 2 "Error" 1 "Present" 0 "Not Present" ;
VAL_ 2566877699 GPTO_Presence 3 "NA" 2 "Error" 1 "Present" 0 "Not Present" ;
VAL_ 2566877699 PTO_Typ 33 "Sh Tec 1000|1000E w/o N" 32 "Sh Tec 540E|1000 w/o N" 255 "NA" 254 "Error" 31 "Sh Tec 540E|1000E" 30 "Sh Tec 540|540E|1000E" 29 "Sh Tec 540E|1000|1000E" 28 "Sh Tec 540|540E|1000 " 27 "Sh Tec 540E|1000" 26 "Sh Tec 540|1000E" 25 "Sh Tec 540|1000" 24 "Sh Tec 540|540E" 20 "Sh Tec 4 Spd 540|540E|1000|1000E" 19 "Sh Tec 3 Spd 540|1000|1000E" 18 "Sh Tec 2 Spd 1000|1000E" 15 "540E|1000E" 14 "540|540E|1000E" 13 "540E|1000|1000E" 12 "540|540E|1000" 11 "540E|1000" 10 "540|1000E" 9 "540|1000" 8 "540|540E" 7 "1000" 6 "1000E" 5 "540E" 4 "Four Spd 540|540E|1000|1000E" 3 "Three Spd 540|1000|1000E" 2 "Two Spd 1000|1000E|540|1000 CH26" 1 "Single Speed 540" 0 "No PTO" 34 "Mechanical" ;
VAL_ 2566877699 FrntDifflckSolPresence 3 "N/A" 1 "Present" 0 "Not Present" ;
VAL_ 2566877699 B2C_Presence 3 "NA" 2 "Error" 1 "Present" 0 "Not Present" ;
VAL_ 2565351182 CByteAckm 3 "CannotRespond" 2 "AccessDenied" 1 "NACK" 0 "ACK" ;
VAL_ 2565351182 PGN_RQST2_0E_27 65242 "SOFT" 65235 "DM11Req" 65229 "DM4Req" 65228 "DM3Req" 65227 "DM2Req" 64965 "ECUID" 60928 "ACL" 41728 "DM31Req" 65259 "CI" ;
VAL_ 2565351171 PGN_RQST2_03_27 65368 "PB_AxleId_03" 65395 "ECU_DatasetChksum" 65394 "ECU_Dataset" ;
VAL_ 2565351171 CByteAckm 3 "CannotRespond" 2 "AccessDenied" 1 "NACK" 0 "ACK" ;
VAL_ 2566871043 AxId 9 "Available for future definition" 253 "Available for future definition" 255 "NA" 254 "Error" 8 "4WD 550 SERIES AXLE" 7 "4WD 600 SERIES AXLE (9C)" 6 "4WD 500 SERIES AXLE (8.5C)" 5 "4WD 425 SERIES AXLE (8C)" 4 "4WD 315 SERIES AXLE (8C)" 3 "CCM MR Standard Duty" 2 "CCH LF Heavy Duty" 1 "CCH LF Standard Duty" 0 "Not Defined" ;
VAL_ 2499798019 SpecialModeResp 1 "Normal Mode" 0 "Special Mode" ;
VAL_ 2499798019 SpecialModeReq 7 "No Special Mode Activated" 6 "Reserved" 5 "Reserved" 4 "Reserved" 3 "Reserved" 2 "Reserved" 1 "EngineCoolDownMode" 0 "Keypad Test Mode" ;
VAL_ 2499798019 ThisNetReq 3 "Don't care " 2 "Reserved" 1 "Net ON" 0 "Net OFF" ;
VAL_ 2499798019 BattMainSwHoldReq 3 "Dont care/take no action" 2 "undefined" 1 "Hold Battery Main Switch" 0 "Release Battery Main Switch" ;
VAL_ 2499798019 KeyPositn 255 "N/A" 4 "Key ON" 1 "Key OFF" ;
VAL_ 2499798019 BattMainSwHoldFunct 15 "Not Available" 14 "Function 15" 13 "Function 14" 12 "Function 13" 11 "Function 12" 10 "Function 11" 9 "Function 10" 8 "Function 9" 7 "Function 8" 6 "Function 7" 5 "Function 6" 4 "Function 5" 3 "Function 4" 2 "Function 3" 1 "Function 2" 0 "Function 1" ;
VAL_ 2499798019 OpSeatSw 0 "Absent" 1 "Present" 2 "Error" 3 "NA" ;
VAL_ 2499798019 AutoGuideEnaSts 3 "Don't care/take no action" 2 "Reserved" 1 "CommandToEnableFunction" 0 "CmdToDisableFunct(NotApplicable)" ;
VAL_ 2499798019 WakeUpInDozeMode 3 "No Action" 2 "Reserved" 1 "On in Doze Mode Command/Request" 0 "Off Command, No Request" ;
VAL_ 2499798019 WakeUpFunct 15 "Not Available" 14 "Function 15" 13 "Function 14" 12 "Function 13" 11 "Function 12" 10 "Function 11" 9 "Function 10" 8 "Function 9" 7 "Function 8" 6 "Function 7" 5 "Function 6" 4 "Function 5" 3 "Function 4" 2 "Function 3" 1 "Function 2" 0 "Function 1" ;
VAL_ 2499798019 VehMov 3 "Not Available" 2 "Error Indicator" 1 "On" 0 "Off" ;
VAL_ 2499798019 KeySwNotOFF 3 "NotAvailable" 2 "ErrorIndication" 1 "KeySwitchNotOff" 0 "KeySwitchOff" ;
VAL_ 2499798019 IgnON 3 "No Action" 2 "Reserved" 1 "On Status/Request" 0 "Off Status, No Request" ;
VAL_ 2499798019 EngStartSts 2 "Error" 3 "Not Available" 1 "On" 0 "Off" ;
VAL_ 2499798019 CByteNetManage 3 "Default or NetWorkMang_N/A" 2 "Reserved" 1 "Command" 0 "Request" ;
VAL_ 2499798019 EngRun 3 "Not Available" 2 "Error Indicator" 1 "On" 0 "Off" ;
VAL_ 2499798019 EmergEngOff_ReqSts 1 "Emergency engine OFF request ACTIVE" 0 "Emergency engine OFF request INACTIVE" ;
VAL_ 2499798019 MasterDisconnSwSts 1 "Master Disconnect switch ACTIVE" 0 "Master Disconnect switch INACTIVE" ;
VAL_ 2565799819 ManufctCod 195 "General Engine Products" 196 "LEMKEN GmbH & Co. KG" 197 "Mechron Power Systems" 198 "Mystic Valley Communications" 199 "Actia Corp." 200 "MGM Brakes" 201 "Disenos y Tecnologia S.A." 202 "Curtis Instruments, Inc." 203 "MILtronik GmbH" 204 "The Morey Corporation" 205 "SmarTire Systems Inc" 206 "port GmbH" 207 "Otto Engineering" 208 "Drew Technologies, Inc." 209 "Bell Equip. Co. SA (PTY) LTD" 210 "Iteris, Inc." 211 "DNA Group" 212 "Sure Power Industries, Inc." 213 "CNH Belgium N.V." 214 "MC elettronica Srl" 215 "Aetna Engineering/Fireboy-Xintex" 216 "Paneltronics Inc." 217 "RM Michaelides Software & Elektronik GmbH" 218 "Gits Manufacturing Company" 219 "Cat OEM Solutions" 220 "Beede Electrical Instrument Company, Inc." 221 "SiE" 222 "Generac Power Systems, Inc." 1850 "Teleflex" 1851 "Raymarine" 1852 "Navionics" 1853 "Japan Radio Co." 1854 "Northstar Technologies" 1855 "Furuno USA" 1856 "Trimble" 1857 "Simrad" 1858 "Litton" 1859 "Kvasar AB" 1860 "MMP" 1861 "Vector CANtech" 1862 "Sanshin" 1863 "Thomas G. Faria Co." 232 "TSD Integrated Controls" 234 "Mondial electronic GmbH" 235 "SailorMade Marine Telemetry - Tetra Technology Ltd." 236 "Norac Systems International Inc" 237 "Agtron Enterprises Inc" 238 "ZF Friedrichshafen AG" 239 "May & Scofield Ltd" 240 "Vanair Mfg" 241 "Schneider Automation SAS " 242 "Kokusandenki Co. Ltd" 243 "eRide, Inc." 244 "Techno-Matic" 245 "Capstan Ag Systems, Inc." 246 "Class 1, Inc" 247 "ePULSE" 248 "Cooper Standard Automotive Active Systems Group" 264 "Autolync" 265 "MTS Sensor Technologie GmbH" 266 "International Thermal Research Ltd" 114 "EControls, Inc." 115 "NACCO Materials Handling Group, Inc." 116 "BEELINE Technologies" 117 "HUSCO International" 118 "Intron GmbH" 119 "IntegriNautics" 120 "RDS Technology Ltd." 121 "HED (Hydro Electronic Devices, Inc.)" 122 "FG Wilson (Engineering) Limited" 123 "Basler Electric" 124 "Hydac Electronic" 125 "Nevada Automotive Test Center" 126 "Driver Tech" 127 "Holland USA" 128 "Gerhard Duecker GmbH & Co. KG" 129 "OMNEX Control Systems, Inc." 130 "Nido - Universal Machines B.V." 131 "ITT Industries" 132 "Mulag-Fahrzeugwerk" 133 "Bucher Schoerling GmbH" 134 "Iris Technology Ltd." 135 "Airmar Technology Corporation" 136 "Komatsu Ltd." 137 "Maretron" 138 "Georg Fritzmeier GmbH & Co. KG" 139 "Caterpillar Trimble Control Technologies (CTCT), LLC" 140 "Lowrance Electronics, Inc." 141 "Thales Navigation Ltd." 142 "TRW Automotive (Commercial Steering Systems)" 143 "W. Gmeiner GmbH & Co." 144 "Mercury Marine" 145 "MurCal Controls" 146 "Maxima Technologies" 147 "Nautibus Electronic GmbH" 148 "Blue Water Data, Inc." 149 "Holset" 150 "Fleetguard" 151 "Raven Industries Inc. - Flow Controls Division" 152 "elobau GmbH & Co. KG" 153 "Woodward, Industrial Controls Division" 154 "Westerbeke Corporation" 155 "Vetronix Corporation" 156 "ITT Industries - Cannon" 157 "ISSPRO Inc." 158 "Firestone Industrial Products Company" 159 "NTech Industries Inc." 160 "Nido" 161 "Offshore Systems (UK) Limited" 162 "Axiomatic Technologies" 163 "BRP Inc." 164 "DaimlerChrysler Off-Highway" 165 "CPAC Systems AB" 166 "Phoenix International" 167 "JLG Industries Inc." 168 "Xantrex" 169 "Marlin Technologies Inc." 170 "Computronics Corporation Ltd." 171 "Wachendorff Elektronik GmbH & Co. KG" 172 "Yanmar Marine USA" 173 "Ryeso, Inc." 174 "AB Volvo Penta" 175 "Veris Technologies, Inc." 176 "Moritz Aerospace" 177 "Diagnostic System Associates" 178 "Siemens VDO Automotive AG" 179 "TeeJet Technologies Denmark" 180 "Smart Power Systems" 181 "Coretronics, Inc." 182 "Vehicle Systems Engineering B.V." 183 "KDS Controls, Inc." 184 "EIA Electronics" 185 "Beede Electrical Instrument Company" 186 "Altronic, Inc." 187 "Air-Weigh" 188 "EMP Corp." 189 "QUALCOMM" 190 "Hella KGaA Hueck & Co." 191 "XRS Corporation" 192 "Floscan" 193 "Nobletec" 194 "TriMark Corporation" 378 "Glendinning Marine Products" 379 "Yamabiko Corporation" 380 "Suntech International Ltd." 382 "National Agricultural and Food Research Organization" 383 "MCL Industries" 384 "Camano Light" 385 "Johnson Outdoor Marine Electronics" 386 "JLG Automation BVBA" 387 "Orscheln Products, LLC" 388 "Innomatix, LLC" 389 "Benchmark Electronics, Minnesota Division" 390 "Partech Inc." 391 "Electronic Design for Industry, Inc" 392 "Tianyuan Technology Co Ltd." 393 "Harvest Tec, Inc" 394 "Capi 2 Nederland BV" 395 "GENTEC S.R.L." 396 "Beyond Measure" 397 "Sanyo-kiki Co Ltd." 398 "Hilite International" 399 "ISEKI & Co., Ltd." 400 "Livorsi Marine" 401 "Torqeedo GmbH" 402 "Simma Software, Inc." 403 "Trackwell ADS, Inc." 404 "Com Nav Marine Ltd" 405 "Wema System AS" 406 "Vecima Networks Inc." 407 "Comtech Mobile Datacom" 408 "Corvus Energy Ltd." 409 "Transfluid S.r.L." 410 "COBO S.p.A. Divisione 3B6" 411 "Hy-Drive Technologies Ltd." 412 "WebTech Wireless Inc." 413 "Datapross Nijbroek bv" 414 "Cattron Group International" 415 "Valid Manufacturing Ltd." 416 "Kubota Corporation" 417 "KZValve" 418 "Intellistick Inc" 419 "Fusion Electronics Ltd" 420 "Vermeer Corporation, ACS Group" 421 "Vertex Standard Co., Ltd" 422 "True Heading AB" 423 "BSM Wireless, Inc." 424 "Odyne LLC" 425 "Methode Electronics Inc, MDI" 426 "Egersund Marine Electronics AS" 427 "em-trak Marine Electronics Ltd" 428 "Mfg_428" 429 "Rota Engineering Ltd." 455 "ADZ NAGANO GmbH" 456 "General Kinetics" 457 "RUSELPROM-ElectricDrive Ltd" 458 "Control Solutions, Inc." 459 "Alltek Marine Electronics Corp" 1098 "Preh GmbH" 593 "Sensata Technologies" 460 "San Giorgio S.E.I.N." 267 "Red Lion Controls, Inc" 268 "Accurate Technologies" 269 "Saft America Inc.,  Space & Defense Division" 270 "Tennant" 271 "Cole Hersee" 312 "Lectronix, Inc." 313 "Ilmor Engineering, Inc" 314 "CSM GmbH" 315 "Icom Incorporated" 316 "ITT Flow Control" 317 "Navtronics Bvba" 318 "SAT Plan" 319 "Cadec Global" 320 "Miedema Landbouwwerktuigenfabriek B.V." 321 "Ultra Electronics, Electrics" 322 "MICHENKA s.r.o." 323 "Mobileye Vision Technologies Ltd." 324 "Snap-on Diagnostics" 325 "ASM Automation Sensorik Messtechnik GmbH" 326 "Akron Brass Company" 327 "Sonceboz SA" 272 "Gross Mechanical Laboratories, Inc" 273 "Active Research Limited" 274 "LTW Technology Co., LTD" 275 "Navico Egersund AS" 276 "Aqua-Hot Heating Systems" 277 "LHP Telematics" 278 "Takata Electronics" 279 "Geometris LP" 280 "Leica Geosystems Pty Ltd" 299 "Rauch Landmaschinen GmbH" 300 "Systron Donner Automotive" 301 "Parker Hannifin (UK) Ltd FDE group" 302 "Nissin Kogyo Co., LTD" 303 "CTS Corporation" 304 "EmpirBus AB" 305 "NovAtel Inc" 306 "Sleipner Motor AB" 307 "MBW Technologies" 308 "Cyntrx" 309 "Krauss-Maffei Wegmann GmbH & Co. KG" 310 "TECNORD srl" 311 "Patrick Power Products" 281 "Precision Governors LLC" 282 "Medallion Instrumentation Systems" 283 "CWF Hamilton & Co Ltd" 284 "Mobile Tech Chile" 285 "Sea Recovery Corp" 286 "Coelmo srl" 287 "NTech Industries, Inc" 288 "Mitsubishi FUSO Truck & Bus Corp." 289 "Watlow" 290 "Kuebler GmbH" 291 "Groeneveld Transport Efficiency BV" 292 "IKUSI - Angel Iglesias S.A." 293 "Spyder Controls Corp." 294 "Grayhill Inc." 295 "BEP Marine" 296 "micro dynamics GmbH" 297 "Zonar Systems Inc" 298 "Holley Performance" 253 "Mobile Control Systems" 254 "GE Sensing" 255 "MEAS France" 256 "Tyco Electronics AMP" 257 "Honda Motor Co., Ltd" 258 "ARAG" 259 "Jetter AG" 260 "Reichhardt GmbH" 261 "Red Dot Corporation" 262 "HydraForce, Inc" 263 "IMMI" 223 "Vaueo Retarder Co., Ltd." 224 "EMMI Network, S.L." 225 "SKF" 226 "Monaco Coach Corporation" 227 "Lykketronic A/S" 228 "ZF Marine Electronics" 229 "Garmin International Inc." 230 "Saucon Technologies" 231 "Topcon Positioning Systems, Inc." 0 "Reserved" 1 "Allied Signal Inc." 2 "Allison Transmission, GMC" 3 "Ametek, US Gauge Division" 4 "Ametek-Dixson" 5 "AMP Inc." 6 "Berifors Electronics AB" 7 "Case Corp." 8 "Caterpillar Inc." 9 "Chrysler Corp." 10 "Cummins Engine Co." 11 "Dearborn Group Inc." 12 "Deere & Company, Precision Farming" 13 "Delco Electronics" 14 "Detroit Diesel Corporation" 15 "Dickey-John Corp." 16 "Eaton Corp." 17 "Eaton Corp. Res & Dev" 18 "Eaton Corp, Transmission Division" 19 "Eaton Corp. Trucking Info Services" 20 "Eaton Ltd" 21 "Echilin Inc., Midland Brake Inc." 22 "Ford Motor Co., Electronic Concepts $ Systems" 23 "Ford Motor Co., Heavy Truck" 24 "Ford Motor Co., Vehicle Controls" 25 "Daimler Trucks North America LLC" 26 "General Motors Corp., Service Technology Group" 27 "GMC" 28 "Grote Ind. Inc." 29 "Hino Motors Ltd." 30 "Isuzu Motors Ltd." 31 "J Pollak Corp." 32 "Jacobs Vehicle Systems" 33 "John Deere" 34 "Kelsey Hayes Co." 35 "Kenworth Truck Co." 36 "Lucas Ltd." 37 "Mack Trucks Inc." 38 "Micro Processor Systems Inc." 39 "Microfirm Inc." 40 "Motorola AIEG Inc." 41 "Motorola Inc." 42 "International Truck and Engine Corp. Engine Electronics" 43 "International Truck and Engine Corp. Vehicle Electronics" 233 "Yacht Monitoring Solutions Inc." 249 "Schaltbau GmbH" 250 "Kuhn Group" 251 "German Agricultural Society" 252 "Sensor-Technik Wiedemann GmbH" 328 "Qwerty Electronik AB" 329 "Deif A/S" 330 "Kidde Aerospace and Defense" 331 "Horton, Inc." 332 "HWH Corporation" 333 "Hadley Products Corporation" 334 "Takata-Petri AG" 335 "Evo Electric Ltd" 336 "APE s.r.o." 337 "Carraro S.p.A." 338 "GRAF-SYTECO" 339 "Competence Center ISOBUS e.V." 340 "Continental AG" 341 "Boning GmbH & Co" 342 "THOMAS MAGNETE GmbH" 343 "Baumer Group" 344 "Parvus Corporation" 345 "Korean Maritime University" 346 "Control Solutions" 347 "Honeywell" 348 "Amazonen Werke H. Dreyer" 349 "Suonentiet" 350 "Noris Marine Systems GmbH & Co KG" 351 "Thrane & Thrane" 352 "SAME DEUTZ-FAHR" 353 "Hegemon Electronics, Inc." 354 "Junkkari OY" 355 "Mastervolt International B.V." 356 "Fischer Panda Generators, Inc" 357 "Hardi International A/S" 358 "Victron Energy BV" 359 "Ludwig Bergmann GmbH" 360 "HJS Emission Technology GmbH & Co KG" 361 "InMach" 362 "Alois Poettinger Maschinenfabrik GmbH" 363 "BEI Duncan" 364 "OEM Controls Inc." 365 "Digi-Star, LLC" 366 "Viewnyx Corp." 367 "Fliegl Agrartechnik" 368 "HANSENHOF_electronic" 369 "Power Torque Engineering Ltd" 370 "Rolls-Royce Marine AS" 371 "Heinzmann GmbH & Co. KG" 373 "Electronic Design Inc." 374 "Northern Lights, Inc." 381 "B&G" 372 "Delphi" 375 "Williams Controls Inc." 376 "Quake Global" 454 "NGK Spark Plug Co. Ltd" 480 "EnerDel, Inc." 481 "Chetco Digital Instruments" 482 "Tricon Electronics" 483 "Valeo" 484 "Headsight Inc." 485 "MATT automotive" 377 "ifm electronic gmbh" 44 "Nippondenso Co. Ltd." 45 "PACCAR" 46 "Noregon Systems, Inc" 47 "Phillips Semiconductor" 48 "Pollak Alphabet" 49 "RE America Inc." 50 "Robert Bosch Corp" 51 "Robert Bosch GmbH" 52 "Meritor Automotive, Inc." 53 "Continental Automotive Systems US, Inc." 54 "Meritor Wabco" 55 "Ryder System Inc." 56 "SAIC" 57 "Sauer-Danfoss Co." 58 "SPX Corporation, OTC Division" 59 "VES Inc." 60 "Volvo Trucks North America Inc." 61 "Volvo Truck Corp." 62 "Wabco" 63 "ZF Industries Inc." 64 "unused" 65 "MAN Nutzfahrzeuge AG" 66 "John Deere Construction Equipment Division" 67 "Funk Manufacturing Company" 68 "Scania" 69 "Trimble Navigation" 70 "Flex-Coil Limited" 71 "Vansco Electronics Ltd." 72 "Sisu Corporation" 73 "LeTourneau, Inc." 74 "Eaton Axle-Brake Division" 75 "Deere & Co. Agricultural Division" 76 "unused" 77 "Deere Power Systems Group" 78 "Frank W. Murphy Manufacturing, Inc." 79 "Daimler Benz AG - Engine Division (PBM)" 80 "Twin Disc, Inc." 81 "Fire Research Corp" 82 "Bobcat/Ingersoll-Rand" 83 "Bendix VORAD Technologies" 84 "New Holland UK Limited" 85 "Kohler Co." 86 "C.E. Niehoff & Company" 87 "J.C. Bamford Excavators Ltd (JCB)" 88 "Satloc Precision GPS" 89 "Kverneland Group, Electronics Division" 90 "Knorr-Bremse SfN GmbH" 91 "BSG Bodensee Steuergeraete GmbH" 92 "Ag-Chem Equipment Co., Inc." 93 "Perkins Engines Company Ltd." 94 "CNH Global N.V." 95 "Pacific Insight Electronics Corp." 96 "Mech@tronic IT GmbH" 97 "Ag Leader Technology, Inc." 98 "Mueller-Elektronik GmbH & Co." 99 "International Transmissions Ltd (ITL)" 100 "VDO Technik AG" 101 "Sensoria" 102 "AGCO GmbH & Co." 103 "CLAAS Agrosystems GmbH & Co. KG" 104 "Claas Selbstfahrende Erntemaschinen GmbH" 105 "Kiepe Elektrik GmbH & Co. KG" 106 "BAE Systems Controls, Inc." 107 "Grimme Landmaschinen GmbH & Co. KG" 108 "WTK-Elecktronik GmbH" 109 "TeeJet Technologies Denmark" 110 "EPIQ Sensor-Nite" 111 "Maschinenfabrik Bernard Krone GmbH" 112 "MECALAC" 113 "Stress-Tek, Inc." 461 "HAWE Hydraulik SE" 462 "IHI Shibaura Machinery Corporation" 463 "PROBOTIQ" 464 "Leach International Corporation" 465 "Ashcroft Inc" 466 "Veethree Electronics and Marine LLC" 467 "Lely Industries N.V." 468 "Tyco Fire Protection Products" 469 "RA Consulting GmbH" 470 "SI-TEX Marine Electronics" 471 "Sea Cross Marine AB" 472 "Tenneco Inc." 473 "Boss Industries, Inc." 474 "Persen Technologies Inc." 475 "GME" 476 "Hummingbird Marine Electronics" 477 "OilQuick AB" 478 "OceanSat BV" 479 "Vapor Bus International" 430 "Auteq Telematica S.A." 431 "Tohatsu Corporation" 432 "S&A Systems, Inc." 433 "Rowe Electronics" 434 "Stored Energy Systems" 435 "Zunhammer GmbH" 436 "Kinze Manufacturing" 437 "Digital Yacht Limited" 438 "Comar Systems Ltd" 439 "Hyundai Heavy Industries" 440 "Cummins Power Generation" 441 "PTG Reifendruckregelsysteme GmbH" 442 "Horsch Maschinen GmbH" 443 "SignalQuest, Inc." 444 "ITT Power Solutions" 445 "KAT MECHATRONIC, Electronic Product Division" 446 "CertTech, L.L.C." 447 "Great Plains Mfg." 448 "Stanadyne Corporation, Electronics Systems" 449 "Polaris Industries Inc" 450 "Dycor Technologies Ltd." 451 "Parker Hannifin Corp" 452 "WIKA Alexander Wiegand SE & Co. KG" 453 "Cooper Bussmann" 486 "Westport Innovations Inc." 487 "DSE Test Solutions A/S" 488 "The Charles Machine Works, Inc." 489 "Appareo Systems" 490 "QuikQ" 491 "Penny and Giles Ltd" 492 "Inergy Automotive Systems" 493 "Watcheye" 494 "Synerject" 495 "HOLMER Maschinenbau GmbH" 496 "W. Gessmann GmbH" 497 "SENTRON Sistemas Embarcados" 498 "Innovative Design Solutions, Inc." 499 "LCJ Capteurs" 500 "Oxbo International Corporation" 501 "Agrotronix S.A." 502 "Attwood Corporation" 503 "Naviop S.R.L." 504 "Vesper Marine" 505 "Yetter Farm Equipment" 506 "IHI STAR Machinery Corporation" 507 "Test Center ISOBUS" 508 "Transtech Innovations" 509 "MOTORTECH GmbH" 510 "Marinesoft Co. Ltd" 511 "Sulky" 512 "Inpower LLC" 513 "FarmscanAg" 514 "DISTek Integration, Inc." 515 "GINAF Trucks Nederland B.V." 516 "AVAT Automation GmbH" 517 "Noland Engineering" 518 "Transas USA Inc." 519 "Peeters Landbouwmachines b.v." 520 "Trapeze" ;
VAL_ 2565799819 IndstryGrp 7 "NotAvailable" 5 "Reserved" 4 "Marine" 3 "Construction" 2 "AgriculturalAndForestry" 1 "OnHighway" 0 "Global" ;
VAL_ 2565799819 Funct 57 "Steering Column Unit" 58 "Fan Drive Control" 59 "Starter" 60 "Cab Display" 61 "File Server/Printer" 62 "On-Board Diagnostic Unit" 63 "Engine Valve Controller" 64 "Endurance Braking" 65 "Gas Flow Measurement" 66 "I/O Controller" 67 "Electrical System Controller" 68 "Aftertreatment system gas measurement" 69 "Engine Emission Aftertreatement System" 30 "Management Computer" 31 "Propulsion Battery Charger" 104 "Reserved" 105 "Reserved" 106 "Reserved" 70 "Auxiliary Regeneration Device" 71 "Transfer Case Control" 72 "Coolant Valve Controller" 73 "Rollover Detection Control" 74 "Lubrication System" 75 "Supplemental Fan" 76 "Temperature Sensor" 77 "Fuel Properties Sensor" 78 "Fire Suppression System" 79 "Reserved" 80 "Reserved" 81 "Reserved" 82 "Reserved" 83 "Reserved" 84 "Reserved" 85 "Reserved" 86 "Reserved" 87 "Reserved" 88 "Reserved" 89 "Reserved" 90 "Reserved" 91 "Reserved" 92 "Reserved" 93 "Reserved" 94 "Reserved" 95 "Reserved" 96 "Reserved" 97 "Reserved" 98 "Reserved" 99 "Reserved" 100 "Reserved" 0 "Engine" 1 "Auxiliary Power Unit (APU)" 2 "Electric Propulsion Control" 3 "Transmission" 4 "Battery Pack Monitor" 5 "Shift Control/Console" 6 "Power TakeOff - (Main or Rear)" 7 "Axle - Steering" 8 "Axle - Drive" 9 "Brakes - System Controller" 10 "Brakes - Steer Axle" 11 "Brakes - Drive Axle" 12 "Retarder - Engine" 13 "Retarder - Driveline" 14 "Cruise Control" 15 "Fuel System" 16 "Steering Controller" 17 "Suspension - Steer Axle" 18 "Suspension - Drive Axle" 19 "Instrument Cluster" 20 "Trip Recorder" 21 "Cab Climate Control" 22 "Aerodynamic Control" 23 "Vehicle Navigation" 24 "Vehicle Security" 107 "Reserved" 108 "Reserved" 109 "Reserved" 110 "Reserved" 111 "Reserved" 112 "Reserved" 113 "Reserved" 114 "Reserved" 115 "Reserved" 116 "Reserved" 117 "Reserved" 118 "Reserved" 119 "Reserved" 120 "Reserved" 121 "Reserved" 122 "Reserved" 123 "Reserved" 124 "Reserved" 125 "Reserved" 126 "Reserved" 127 "Reserved" 25 "Network Interconnect ECU" 26 "Body Controller" 27 "Power TakeOff (Secondary or Front)" 28 "Off Vehicle Gateway" 29 "Virtual Terminal (in cab)" 43 "Transmission Display" 44 "Exhaust Emission Control" 45 "Vehicle Dynamic Stability Control" 46 "Oil Sensor Unit" 47 "Information System Controller" 48 "Ramp Control" 49 "Clutch/Converter Control" 50 "Auxiliary Heater" 51 "Forward-Looking Collision Warning System" 52 "Chassis Controller" 53 "Alternator/Charging System" 54 "Communications Unit, Cellular" 55 "Communications Unit, Satellite" 56 "Communications Unit, Radio" 32 "Headway Controller" 33 "System Monitor" 34 "Hydraulic Pump Controller" 35 "Suspension - System Controller" 36 "Pneumatic - System Controller" 37 "Cab Controller" 38 "Tire Pressure Control" 39 "Ignition Control Module" 40 "Seat Control" 41 "Lighting - Operator Controls" 42 "Water Pump Control" 101 "Reserved" 102 "Reserved" 103 "Reserved" ;
VAL_ 2565799819 ArbAddrCap 0 "No" 1 "Yes" ;
VAL_ 2565406603 CByteAckm 3 "CannotRespond" 2 "AccessDenied" 1 "NACK" 0 "ACK" ;
VAL_ 2565406603 PGN_RQST2_EHR 65227 "DM2" ;
VAL_ 2499777575 CalibrOngoing 3 "N/A" 2 "Error" 1 "Calibration" 0 "No calibration" ;
VAL_ 2499777575 CalibrStart 3 "NA" 2 "Error" 1 "Start" 0 "Stop" ;
VAL_ 2499777575 CalibrModeEna 3 "Not Available" 2 "Error" 1 "Enabled" 0 "Not Enabled" ;
VAL_ 2499777575 RPTO_BrakeRleasCmd 3 "Not Available" 2 "Error" 1 "ON (Release PTO Brake)" 0 "OFF (Don't Release PTO Brake)" ;
VAL_ 2499777575 RPTO_SpdRatioCmd 7 "NA" 6 "Error" 4 " N - PTO shiftable only" 0 " 540" 1 " 540 E" 2 "1000" 3 "1000 E" ;
VAL_ 2499777575 RPTO_EngagCmd 3 "DoNotCare" 1 "EngangePTO" 0 "DisengagePTO" ;
VAL_ 2499777575 RPTO_AggrsvnsCmd 3 "Auto" 7 "Not Available" 6 "Error" 2 "High" 1 "Medium" 0 "Low" ;
VAL_ 2499777575 TransmReqGear_2 254 "Error" 251 "Park pos" 255 "Not Availble" ;
